VERSION "dbc-export 1 2025.20.8"

NS_ :

BS_:

BU_: APB APP APS DAS EPAS3S ESP GTW IBST PARK RADC RCM RCM2 RCM3 TPMS TRCM USM

BO_ 981 ESP_alertMatrix: 8 ESP
 SG_ ESP_matrixIndex M : 0|4@1+ (1,0) [0|15] "" Vector__XXX
 SG_ ESP_a001_ecuGenericFault m0 : 4|1@1+ (1,0) [0|1] "" Vector__XXX
 SG_ ESP_a002_valvesGenericFault m0 : 5|1@1+ (1,0) [0|1] "" Vector__XXX
 SG_ ESP_a003_outletValvesFault m0 : 6|1@1+ (1,0) [0|1] "" Vector__XXX
 SG_ ESP_a004_inletValvesFault m0 : 7|1@1+ (1,0) [0|1] "" Vector__XXX
 SG_ ESP_a005_HSVValvesFault m0 : 8|1@1+ (1,0) [0|1] "" Vector__XXX
 SG_ ESP_a006_USVValvesFault m0 : 9|1@1+ (1,0) [0|1] "" Vector__XXX
 SG_ ESP_a007_pumpMotorFault m0 : 10|1@1+ (1,0) [0|1] "" Vector__XXX
 SG_ ESP_a008_pumpMotor12VsupplyLow m0 : 11|1@1+ (1,0) [0|1] "" Vector__XXX
 SG_ ESP_a009_12VHardUndervoltage m0 : 12|1@1+ (1,0) [0|1] "" Vector__XXX
 SG_ ESP_a010_12VUndervoltage m0 : 13|1@1+ (1,0) [0|1] "" Vector__XXX
 SG_ ESP_a011_12VSystemUndervoltage m0 : 14|1@1+ (1,0) [0|1] "" Vector__XXX
 SG_ ESP_a012_netUndervoltage m0 : 15|1@1+ (1,0) [0|1] "" Vector__XXX
 SG_ ESP_a013_valveRelayUndervoltage m0 : 16|1@1+ (1,0) [0|1] "" Vector__XXX
 SG_ ESP_a014_WSSSupplyUndervoltage m0 : 17|1@1+ (1,0) [0|1] "" Vector__XXX
 SG_ ESP_a015_12VSupplyOvervoltage m0 : 18|1@1+ (1,0) [0|1] "" Vector__XXX
 SG_ ESP_a016_12VSystemOvervoltage m0 : 19|1@1+ (1,0) [0|1] "" Vector__XXX
 SG_ ESP_a017_netOvervoltage m0 : 20|1@1+ (1,0) [0|1] "" Vector__XXX
 SG_ ESP_a018_WSSSignFrontAxle m0 : 21|1@1+ (1,0) [0|1] "" Vector__XXX
 SG_ ESP_a019_WSSSignRearAxle m0 : 22|1@1+ (1,0) [0|1] "" Vector__XXX
 SG_ ESP_a020_WSSGenericTempFault m0 : 23|1@1+ (1,0) [0|1] "" Vector__XXX
 SG_ ESP_a021_WSSGeneralVDiffFault m0 : 24|1@1+ (1,0) [0|1] "" Vector__XXX
 SG_ ESP_a022_WSSDirectionFault m0 : 25|1@1+ (1,0) [0|1] "" Vector__XXX
 SG_ ESP_a023_WSSSeveralSuspected m0 : 26|1@1+ (1,0) [0|1] "" Vector__XXX
 SG_ ESP_a024_WSSReverseCurrent m0 : 27|1@1+ (1,0) [0|1] "" Vector__XXX
 SG_ ESP_a025_FrLWSSOpenOrShortToGnd m0 : 28|1@1+ (1,0) [0|1] "" Vector__XXX
 SG_ ESP_a026_FrLWSSShortTo12V m0 : 29|1@1+ (1,0) [0|1] "" Vector__XXX
 SG_ ESP_a027_FrLWSSLineInterruption m0 : 30|1@1+ (1,0) [0|1] "" Vector__XXX
 SG_ ESP_a028_FrLWSSMaxSpeedExceeded m0 : 31|1@1+ (1,0) [0|1] "" Vector__XXX
 SG_ ESP_a029_FrLWSSTooManyPulses m0 : 32|1@1+ (1,0) [0|1] "" Vector__XXX
 SG_ ESP_a030_FrLWSSLostSignal m0 : 33|1@1+ (1,0) [0|1] "" Vector__XXX
 SG_ ESP_a031_FrLWSSNoPulsesDetected m0 : 34|1@1+ (1,0) [0|1] "" Vector__XXX
 SG_ ESP_a032_FrLWSSWrongSensorType m0 : 35|1@1+ (1,0) [0|1] "" Vector__XXX
 SG_ ESP_a033_FrLWSSSignalNoise m0 : 36|1@1+ (1,0) [0|1] "" Vector__XXX
 SG_ ESP_a034_FrLWSSVDiffFault m0 : 37|1@1+ (1,0) [0|1] "" Vector__XXX
 SG_ ESP_a035_FrLWSSDirectionFault m0 : 38|1@1+ (1,0) [0|1] "" Vector__XXX
 SG_ ESP_a036_FrLWSSLargeAirGap m0 : 39|1@1+ (1,0) [0|1] "" Vector__XXX
 SG_ ESP_a037_FrLWSSSupplyShortToGnd m0 : 40|1@1+ (1,0) [0|1] "" Vector__XXX
 SG_ ESP_a038_FrLWSSGeneralFault m0 : 41|1@1+ (1,0) [0|1] "" Vector__XXX
 SG_ ESP_a039_FrRWSSOpenOrShortToGnd m0 : 42|1@1+ (1,0) [0|1] "" Vector__XXX
 SG_ ESP_a040_FrRWSSShortTo12V m0 : 43|1@1+ (1,0) [0|1] "" Vector__XXX
 SG_ ESP_a041_FrRWSSLineInterruption m0 : 44|1@1+ (1,0) [0|1] "" Vector__XXX
 SG_ ESP_a042_FrRWSSMaxSpeedExceeded m0 : 45|1@1+ (1,0) [0|1] "" Vector__XXX
 SG_ ESP_a043_FrRWSSTooManyPulses m0 : 46|1@1+ (1,0) [0|1] "" Vector__XXX
 SG_ ESP_a044_FrRWSSLostSignal m0 : 47|1@1+ (1,0) [0|1] "" Vector__XXX
 SG_ ESP_a045_FrRWSSNoPulsesDetected m0 : 48|1@1+ (1,0) [0|1] "" Vector__XXX
 SG_ ESP_a046_FrRWSSWrongSensorType m0 : 49|1@1+ (1,0) [0|1] "" Vector__XXX
 SG_ ESP_a047_FrRWSSSignalNoise m0 : 50|1@1+ (1,0) [0|1] "" Vector__XXX
 SG_ ESP_a048_FrRWSSVDiffFault m0 : 51|1@1+ (1,0) [0|1] "" Vector__XXX
 SG_ ESP_a049_FrRWSSDirectionFault m0 : 52|1@1+ (1,0) [0|1] "" Vector__XXX
 SG_ ESP_a050_FrRWSSLargeAirGap m0 : 53|1@1+ (1,0) [0|1] "" Vector__XXX
 SG_ ESP_a051_FrRWSSSupplyShortToGnd m0 : 54|1@1+ (1,0) [0|1] "" Vector__XXX
 SG_ ESP_a052_FrRWSSGeneralFault m0 : 55|1@1+ (1,0) [0|1] "" Vector__XXX
 SG_ ESP_a053_ReLWSSOpenOrShortToGnd m0 : 56|1@1+ (1,0) [0|1] "" Vector__XXX
 SG_ ESP_a054_ReLWSSShortTo12V m0 : 57|1@1+ (1,0) [0|1] "" Vector__XXX
 SG_ ESP_a055_ReLWSSLineInterruption m0 : 58|1@1+ (1,0) [0|1] "" Vector__XXX
 SG_ ESP_a056_ReLWSSMaxSpeedExceeded m0 : 59|1@1+ (1,0) [0|1] "" Vector__XXX
 SG_ ESP_a057_ReLWSSTooManyPulses m0 : 60|1@1+ (1,0) [0|1] "" Vector__XXX
 SG_ ESP_a058_ReLWSSLostSignal m0 : 61|1@1+ (1,0) [0|1] "" Vector__XXX
 SG_ ESP_a059_ReLWSSNoPulsesDetected m0 : 62|1@1+ (1,0) [0|1] "" Vector__XXX
 SG_ ESP_a060_ReLWSSWrongSensorType m0 : 63|1@1+ (1,0) [0|1] "" Vector__XXX
 SG_ ESP_a061_ReLWSSSignalNoise m1 : 4|1@1+ (1,0) [0|1] "" Vector__XXX
 SG_ ESP_a062_ReLWSSVDiffFault m1 : 5|1@1+ (1,0) [0|1] "" Vector__XXX
 SG_ ESP_a063_ReLWSSDirectionFault m1 : 6|1@1+ (1,0) [0|1] "" Vector__XXX
 SG_ ESP_a064_ReLWSSLargeAirGap m1 : 7|1@1+ (1,0) [0|1] "" Vector__XXX
 SG_ ESP_a065_ReLWSSSupplyShortToGnd m1 : 8|1@1+ (1,0) [0|1] "" Vector__XXX
 SG_ ESP_a066_ReLWSSGeneralFault m1 : 9|1@1+ (1,0) [0|1] "" Vector__XXX
 SG_ ESP_a067_ReRWSSOpenOrShortToGnd m1 : 10|1@1+ (1,0) [0|1] "" Vector__XXX
 SG_ ESP_a068_ReRWSSShortTo12V m1 : 11|1@1+ (1,0) [0|1] "" Vector__XXX
 SG_ ESP_a069_ReRWSSLineInterruption m1 : 12|1@1+ (1,0) [0|1] "" Vector__XXX
 SG_ ESP_a070_ReRWSSMaxSpeedExceeded m1 : 13|1@1+ (1,0) [0|1] "" Vector__XXX
 SG_ ESP_a071_ReRWSSTooManyPulses m1 : 14|1@1+ (1,0) [0|1] "" Vector__XXX
 SG_ ESP_a072_ReRWSSLostSignal m1 : 15|1@1+ (1,0) [0|1] "" Vector__XXX
 SG_ ESP_a073_ReRWSSNoPulsesDetected m1 : 16|1@1+ (1,0) [0|1] "" Vector__XXX
 SG_ ESP_a074_ReRWSSWrongSensorType m1 : 17|1@1+ (1,0) [0|1] "" Vector__XXX
 SG_ ESP_a075_ReRWSSSignalNoise m1 : 18|1@1+ (1,0) [0|1] "" Vector__XXX
 SG_ ESP_a076_ReRWSSVDiffFault m1 : 19|1@1+ (1,0) [0|1] "" Vector__XXX
 SG_ ESP_a077_ReRWSSDirectionFault m1 : 20|1@1+ (1,0) [0|1] "" Vector__XXX
 SG_ ESP_a078_ReRWSSLargeAirGap m1 : 21|1@1+ (1,0) [0|1] "" Vector__XXX
 SG_ ESP_a079_ReRWSSSupplyShortToGnd m1 : 22|1@1+ (1,0) [0|1] "" Vector__XXX
 SG_ ESP_a080_ReRWSSGeneralFault m1 : 23|1@1+ (1,0) [0|1] "" Vector__XXX
 SG_ ESP_a081_PressureSensorShort m1 : 24|1@1+ (1,0) [0|1] "" Vector__XXX
 SG_ ESP_a082_PMCSensorOffsetHigh m1 : 25|1@1+ (1,0) [0|1] "" Vector__XXX
 SG_ ESP_a083_PMCSensorFault m1 : 26|1@1+ (1,0) [0|1] "" Vector__XXX
 SG_ ESP_a084_BrakeFluidReservoirLow m1 : 27|1@1+ (1,0) [0|1] "" Vector__XXX
 SG_ ESP_a085_BrakeSwitchStuckHigh m1 : 28|1@1+ (1,0) [0|1] "" Vector__XXX
 SG_ ESP_a086_BrakeSwitchImplausible1 m1 : 29|1@1+ (1,0) [0|1] "" Vector__XXX
 SG_ ESP_a087_BrakeSwitchImplausible3 m1 : 30|1@1+ (1,0) [0|1] "" Vector__XXX
 SG_ ESP_a088_absContinuousControl m1 : 31|1@1+ (1,0) [0|1] "" Vector__XXX
 SG_ ESP_a089_absNoPressureIncrease m1 : 32|1@1+ (1,0) [0|1] "" Vector__XXX
 SG_ ESP_a090_vdcContinuousControl m1 : 33|1@1+ (1,0) [0|1] "" Vector__XXX
 SG_ ESP_a091_CANUndervoltage m1 : 34|1@1+ (1,0) [0|1] "" Vector__XXX
 SG_ ESP_a092_CANOvervoltage m1 : 35|1@1+ (1,0) [0|1] "" Vector__XXX
 SG_ ESP_a093_partyBusOff m1 : 36|1@1+ (1,0) [0|1] "" Vector__XXX
 SG_ ESP_a094_partyBusPassive m1 : 37|1@1+ (1,0) [0|1] "" Vector__XXX
 SG_ ESP_a095_chassisBusOff m1 : 38|1@1+ (1,0) [0|1] "" Vector__XXX
 SG_ ESP_a096_chassisBusPassive m1 : 39|1@1+ (1,0) [0|1] "" Vector__XXX
 SG_ ESP_a097_tcsRefSpeedNotInit m1 : 40|1@1+ (1,0) [0|1] "" Vector__XXX
 SG_ ESP_a098_vdcRefSpeedNotInit m1 : 41|1@1+ (1,0) [0|1] "" Vector__XXX
 SG_ ESP_a099_brakeTempModelOverheat m1 : 42|1@1+ (1,0) [0|1] "" Vector__XXX
 SG_ ESP_a100_brakeTempModelDisabled m1 : 43|1@1+ (1,0) [0|1] "" Vector__XXX
 SG_ ESP_a101_ebdFault m1 : 44|1@1+ (1,0) [0|1] "" Vector__XXX
 SG_ ESP_a102_absFault m1 : 45|1@1+ (1,0) [0|1] "" Vector__XXX
 SG_ ESP_a103_stabilityControlFault m1 : 46|1@1+ (1,0) [0|1] "" Vector__XXX
 SG_ ESP_a104_hbcEnabled m1 : 47|1@1+ (1,0) [0|1] "" Vector__XXX
 SG_ ESP_a105_ebrFault m1 : 48|1@1+ (1,0) [0|1] "" Vector__XXX
 SG_ ESP_a106_vdcActuatorFault m1 : 49|1@1+ (1,0) [0|1] "" Vector__XXX
 SG_ ESP_a107_reserved107 m1 : 50|1@1+ (1,0) [0|1] "" Vector__XXX
 SG_ ESP_a108_reserved108 m1 : 51|1@1+ (1,0) [0|1] "" Vector__XXX
 SG_ ESP_a109_reserved109 m1 : 52|1@1+ (1,0) [0|1] "" Vector__XXX
 SG_ ESP_a110_rollerBenchActive m1 : 53|1@1+ (1,0) [0|1] "" Vector__XXX
 SG_ ESP_a111_absActive m1 : 54|1@1+ (1,0) [0|1] "" Vector__XXX
 SG_ ESP_a112_espActive m1 : 55|1@1+ (1,0) [0|1] "" Vector__XXX
 SG_ ESP_a113_btcActive m1 : 56|1@1+ (1,0) [0|1] "" Vector__XXX
 SG_ ESP_a114_tvdcActive m1 : 57|1@1+ (1,0) [0|1] "" Vector__XXX
 SG_ ESP_a115_ebdActive m1 : 58|1@1+ (1,0) [0|1] "" Vector__XXX
 SG_ ESP_a116_tsmActive m1 : 59|1@1+ (1,0) [0|1] "" Vector__XXX
 SG_ ESP_a117_hbaActive m1 : 60|1@1+ (1,0) [0|1] "" Vector__XXX
 SG_ ESP_a118_hfcActive m1 : 61|1@1+ (1,0) [0|1] "" Vector__XXX
 SG_ ESP_a119_hbbActive m1 : 62|1@1+ (1,0) [0|1] "" Vector__XXX
 SG_ ESP_a120_rmiActive m1 : 63|1@1+ (1,0) [0|1] "" Vector__XXX
 SG_ ESP_a121_regenTcActive m2 : 4|1@1+ (1,0) [0|1] "" Vector__XXX
 SG_ ESP_a122_bdwActive m2 : 5|1@1+ (1,0) [0|1] "" Vector__XXX
 SG_ ESP_a123_ebrActive m2 : 6|1@1+ (1,0) [0|1] "" Vector__XXX
 SG_ ESP_a124_ebrSkidActive m2 : 7|1@1+ (1,0) [0|1] "" Vector__XXX
 SG_ ESP_a125_reserved125 m2 : 8|1@1+ (1,0) [0|1] "" Vector__XXX
 SG_ ESP_a126_reserved126 m2 : 9|1@1+ (1,0) [0|1] "" Vector__XXX
 SG_ ESP_a127_reserved127 m2 : 10|1@1+ (1,0) [0|1] "" Vector__XXX
 SG_ ESP_a128_reserved128 m2 : 11|1@1+ (1,0) [0|1] "" Vector__XXX
 SG_ ESP_a129_reserved129 m2 : 12|1@1+ (1,0) [0|1] "" Vector__XXX
 SG_ ESP_a130_EPAS3PsysStatusTimeout m2 : 13|1@1+ (1,0) [0|1] "" Vector__XXX
 SG_ ESP_a131_EPAS3PsysStatusDLC m2 : 14|1@1+ (1,0) [0|1] "" Vector__XXX
 SG_ ESP_a132_EPAS3PsysStatusChecksum m2 : 15|1@1+ (1,0) [0|1] "" Vector__XXX
 SG_ ESP_a133_EPAS3PsysStatusCounter m2 : 16|1@1+ (1,0) [0|1] "" Vector__XXX
 SG_ ESP_a134_steeringAngleInvalid m2 : 17|1@1+ (1,0) [0|1] "" Vector__XXX
 SG_ ESP_a135_steeringAngleNoCenter m2 : 18|1@1+ (1,0) [0|1] "" Vector__XXX
 SG_ ESP_a136_steeringAngleFrozen m2 : 19|1@1+ (1,0) [0|1] "" Vector__XXX
 SG_ ESP_a137_steeringOffsetTooLarge m2 : 20|1@1+ (1,0) [0|1] "" Vector__XXX
 SG_ ESP_a138_steeringAngleImplaus m2 : 21|1@1+ (1,0) [0|1] "" Vector__XXX
 SG_ ESP_a139_steeringAngleWrongSign m2 : 22|1@1+ (1,0) [0|1] "" Vector__XXX
 SG_ ESP_a140_RCMInertial1Timeout m2 : 23|1@1+ (1,0) [0|1] "" Vector__XXX
 SG_ ESP_a141_RCMInertial1DLC m2 : 24|1@1+ (1,0) [0|1] "" Vector__XXX
 SG_ ESP_a142_RCMInertial1Checksum m2 : 25|1@1+ (1,0) [0|1] "" Vector__XXX
 SG_ ESP_a143_RCMInertial1Counter m2 : 26|1@1+ (1,0) [0|1] "" Vector__XXX
 SG_ ESP_a144_yawMaxLatency m2 : 27|1@1+ (1,0) [0|1] "" Vector__XXX
 SG_ ESP_a145_yawInitFault m2 : 28|1@1+ (1,0) [0|1] "" Vector__XXX
 SG_ ESP_a146_yawInvalidValue m2 : 29|1@1+ (1,0) [0|1] "" Vector__XXX
 SG_ ESP_a147_yawSensorNotAvailable m2 : 30|1@1+ (1,0) [0|1] "" Vector__XXX
 SG_ ESP_a148_yawSignalFault m2 : 31|1@1+ (1,0) [0|1] "" Vector__XXX
 SG_ ESP_a149_yawInvalidSign m2 : 32|1@1+ (1,0) [0|1] "" Vector__XXX
 SG_ ESP_a150_yawImplausible m2 : 33|1@1+ (1,0) [0|1] "" Vector__XXX
 SG_ ESP_a151_RCMInertial2Timeout m2 : 34|1@1+ (1,0) [0|1] "" Vector__XXX
 SG_ ESP_a152_RCMInertial2DLC m2 : 35|1@1+ (1,0) [0|1] "" Vector__XXX
 SG_ ESP_a153_RCMInertial2Checksum m2 : 36|1@1+ (1,0) [0|1] "" Vector__XXX
 SG_ ESP_a154_RCMInertial2Counter m2 : 37|1@1+ (1,0) [0|1] "" Vector__XXX
 SG_ ESP_a155_ayMaxLatency m2 : 38|1@1+ (1,0) [0|1] "" Vector__XXX
 SG_ ESP_a156_ayInitFault m2 : 39|1@1+ (1,0) [0|1] "" Vector__XXX
 SG_ ESP_a157_ayInvalidValue m2 : 40|1@1+ (1,0) [0|1] "" Vector__XXX
 SG_ ESP_a158_aySensorNotAvailable m2 : 41|1@1+ (1,0) [0|1] "" Vector__XXX
 SG_ ESP_a159_aySignalFault m2 : 42|1@1+ (1,0) [0|1] "" Vector__XXX
 SG_ ESP_a160_ayRangeExceeded m2 : 43|1@1+ (1,0) [0|1] "" Vector__XXX
 SG_ ESP_a161_ayOffsetExceeded m2 : 44|1@1+ (1,0) [0|1] "" Vector__XXX
 SG_ ESP_a162_ayImplausible m2 : 45|1@1+ (1,0) [0|1] "" Vector__XXX
 SG_ ESP_a163_axMaxLatency m2 : 46|1@1+ (1,0) [0|1] "" Vector__XXX
 SG_ ESP_a164_axInitFault m2 : 47|1@1+ (1,0) [0|1] "" Vector__XXX
 SG_ ESP_a165_axInvalidValue m2 : 48|1@1+ (1,0) [0|1] "" Vector__XXX
 SG_ ESP_a166_axSensorNotAvailable m2 : 49|1@1+ (1,0) [0|1] "" Vector__XXX
 SG_ ESP_a167_axSignalFault m2 : 50|1@1+ (1,0) [0|1] "" Vector__XXX
 SG_ ESP_a168_axRangeExceeded m2 : 51|1@1+ (1,0) [0|1] "" Vector__XXX
 SG_ ESP_a169_axOffsetExceeded m2 : 52|1@1+ (1,0) [0|1] "" Vector__XXX
 SG_ ESP_a170_axSignalFrozen m2 : 53|1@1+ (1,0) [0|1] "" Vector__XXX
 SG_ ESP_a171_axImplausible m2 : 54|1@1+ (1,0) [0|1] "" Vector__XXX
 SG_ ESP_a172_IBSTparty1Timeout m2 : 55|1@1+ (1,0) [0|1] "" Vector__XXX
 SG_ ESP_a173_IBSTparty1DLC m2 : 56|1@1+ (1,0) [0|1] "" Vector__XXX
 SG_ ESP_a174_IBSTparty1Checksum m2 : 57|1@1+ (1,0) [0|1] "" Vector__XXX
 SG_ ESP_a175_IBSTparty1Counter m2 : 58|1@1+ (1,0) [0|1] "" Vector__XXX
 SG_ ESP_a176_IBSTEBRNotAvailable m2 : 59|1@1+ (1,0) [0|1] "" Vector__XXX
 SG_ ESP_a177_IBSTOutputRodDrvInvalid m2 : 60|1@1+ (1,0) [0|1] "" Vector__XXX
 SG_ ESP_a178_IBSTOutputRodActInvalid m2 : 61|1@1+ (1,0) [0|1] "" Vector__XXX
 SG_ ESP_a179_IBSTparty2Timeout m2 : 62|1@1+ (1,0) [0|1] "" Vector__XXX
 SG_ ESP_a180_IBSTparty2Checksum m2 : 63|1@1+ (1,0) [0|1] "" Vector__XXX
 SG_ ESP_a181_IBSTparty2DLC m3 : 4|1@1+ (1,0) [0|1] "" Vector__XXX
 SG_ ESP_a182_IBSTparty2Counter m3 : 5|1@1+ (1,0) [0|1] "" Vector__XXX
 SG_ ESP_a183_IBSTStatusOff m3 : 6|1@1+ (1,0) [0|1] "" Vector__XXX
 SG_ ESP_a184_IBSTpRunoutInvalid m3 : 7|1@1+ (1,0) [0|1] "" Vector__XXX
 SG_ ESP_a185_IBSTFeedforwardBackup m3 : 8|1@1+ (1,0) [0|1] "" Vector__XXX
 SG_ ESP_a186_IBSTBrakeAppliedInvalid m3 : 9|1@1+ (1,0) [0|1] "" Vector__XXX
 SG_ ESP_a187_DIbtcRequestTimeout m3 : 10|1@1+ (1,0) [0|1] "" Vector__XXX
 SG_ ESP_a188_DIbtcRequestDLC m3 : 11|1@1+ (1,0) [0|1] "" Vector__XXX
 SG_ ESP_a189_DIbtcRequestChecksum m3 : 12|1@1+ (1,0) [0|1] "" Vector__XXX
 SG_ ESP_a190_DIbtcRequestCounter m3 : 13|1@1+ (1,0) [0|1] "" Vector__XXX
 SG_ ESP_a191_DIchassisControlTimeout m3 : 14|1@1+ (1,0) [0|1] "" Vector__XXX
 SG_ ESP_a192_DIchassisControlDLC m3 : 15|1@1+ (1,0) [0|1] "" Vector__XXX
 SG_ ESP_a193_DIchassisControlChecksu m3 : 16|1@1+ (1,0) [0|1] "" Vector__XXX
 SG_ ESP_a194_DIchassisControlCounter m3 : 17|1@1+ (1,0) [0|1] "" Vector__XXX
 SG_ ESP_a195_ptcStateInvalid m3 : 18|1@1+ (1,0) [0|1] "" Vector__XXX
 SG_ ESP_a196_DIsystemStatusTimeout m3 : 19|1@1+ (1,0) [0|1] "" Vector__XXX
 SG_ ESP_a197_DIsystemStatusDLC m3 : 20|1@1+ (1,0) [0|1] "" Vector__XXX
 SG_ ESP_a198_DIsystemStatusChecksum m3 : 21|1@1+ (1,0) [0|1] "" Vector__XXX
 SG_ ESP_a199_DIsystemStatusCounter m3 : 22|1@1+ (1,0) [0|1] "" Vector__XXX
 SG_ ESP_a200_reverseGearStuckHigh m3 : 23|1@1+ (1,0) [0|1] "" Vector__XXX
 SG_ ESP_a201_reverseGearStuckLow m3 : 24|1@1+ (1,0) [0|1] "" Vector__XXX
 SG_ ESP_a202_accelPedalInvalid m3 : 25|1@1+ (1,0) [0|1] "" Vector__XXX
 SG_ ESP_a203_DItorqueTimeout m3 : 26|1@1+ (1,0) [0|1] "" Vector__XXX
 SG_ ESP_a204_DItorqueDLC m3 : 27|1@1+ (1,0) [0|1] "" Vector__XXX
 SG_ ESP_a205_DItorqueChecksum m3 : 28|1@1+ (1,0) [0|1] "" Vector__XXX
 SG_ ESP_a206_DItorqueCounter m3 : 29|1@1+ (1,0) [0|1] "" Vector__XXX
 SG_ ESP_a207_DITorqueCommandInvalid m3 : 30|1@1+ (1,0) [0|1] "" Vector__XXX
 SG_ ESP_a208_DIRPMInvalid m3 : 31|1@1+ (1,0) [0|1] "" Vector__XXX
 SG_ ESP_a209_DITorqueActualInvalid m3 : 32|1@1+ (1,0) [0|1] "" Vector__XXX
 SG_ ESP_a210_DIStorqueTimeout m3 : 33|1@1+ (1,0) [0|1] "" Vector__XXX
 SG_ ESP_a211_DIStorqueDLC m3 : 34|1@1+ (1,0) [0|1] "" Vector__XXX
 SG_ ESP_a212_DIStorqueChecksum m3 : 35|1@1+ (1,0) [0|1] "" Vector__XXX
 SG_ ESP_a213_DIStorqueCounter m3 : 36|1@1+ (1,0) [0|1] "" Vector__XXX
 SG_ ESP_a214_DISTorqueCommandInvalid m3 : 37|1@1+ (1,0) [0|1] "" Vector__XXX
 SG_ ESP_a215_DISRPMInvalid m3 : 38|1@1+ (1,0) [0|1] "" Vector__XXX
 SG_ ESP_a216_DISTorqueActualInvalid m3 : 39|1@1+ (1,0) [0|1] "" Vector__XXX
 SG_ ESP_a217_DIvdcLeftTimeout m3 : 40|1@1+ (1,0) [0|1] "" Vector__XXX
 SG_ ESP_a218_DIvdcLeftDLC m3 : 41|1@1+ (1,0) [0|1] "" Vector__XXX
 SG_ ESP_a219_DIvdcLeftChecksum m3 : 42|1@1+ (1,0) [0|1] "" Vector__XXX
 SG_ ESP_a220_DIvdcLeftCounter m3 : 43|1@1+ (1,0) [0|1] "" Vector__XXX
 SG_ ESP_a221_DIvdcRightTimeout m3 : 44|1@1+ (1,0) [0|1] "" Vector__XXX
 SG_ ESP_a222_DIvdcRightDLC m3 : 45|1@1+ (1,0) [0|1] "" Vector__XXX
 SG_ ESP_a223_DIvdcRightChecksum m3 : 46|1@1+ (1,0) [0|1] "" Vector__XXX
 SG_ ESP_a224_DIvdcRightCounter m3 : 47|1@1+ (1,0) [0|1] "" Vector__XXX
 SG_ ESP_a225_configMismatch m3 : 48|1@1+ (1,0) [0|1] "" Vector__XXX
 SG_ ESP_a226_bdwRequestInvalid m3 : 49|1@1+ (1,0) [0|1] "" Vector__XXX
 SG_ ESP_a227_bdwRequestActiveInvalid m3 : 50|1@1+ (1,0) [0|1] "" Vector__XXX
 SG_ ESP_a228_GTWvinTimeout m3 : 51|1@1+ (1,0) [0|1] "" Vector__XXX
 SG_ ESP_a229_GTWvinDLC m3 : 52|1@1+ (1,0) [0|1] "" Vector__XXX
 SG_ ESP_a230_vinNotLearned m3 : 53|1@1+ (1,0) [0|1] "" Vector__XXX
 SG_ ESP_a231_storedVINMismatch m3 : 54|1@1+ (1,0) [0|1] "" Vector__XXX
 SG_ ESP_a232_PMstate2Timeout m3 : 55|1@1+ (1,0) [0|1] "" Vector__XXX
 SG_ ESP_a233_PMstate2Checksum m3 : 56|1@1+ (1,0) [0|1] "" Vector__XXX
 SG_ ESP_a234_PMstate2DLC m3 : 57|1@1+ (1,0) [0|1] "" Vector__XXX
 SG_ ESP_a235_PMstate2Counter m3 : 58|1@1+ (1,0) [0|1] "" Vector__XXX
 SG_ ESP_a236_ebrCommandStateInvalid m3 : 59|1@1+ (1,0) [0|1] "" Vector__XXX
 SG_ ESP_a237_vdcCommandStateInvalid m3 : 60|1@1+ (1,0) [0|1] "" Vector__XXX
 SG_ ESP_a238_UIodoTimeout m3 : 61|1@1+ (1,0) [0|1] "" Vector__XXX
 SG_ ESP_a239_UIodoDLC m3 : 62|1@1+ (1,0) [0|1] "" Vector__XXX
 SG_ ESP_a240_LVPowerStateTimeout m3 : 63|1@1+ (1,0) [0|1] "" Vector__XXX
 SG_ ESP_a241_LVPowerStateChecksum m4 : 4|1@1+ (1,0) [0|1] "" Vector__XXX
 SG_ ESP_a242_LVPowerStateDLC m4 : 5|1@1+ (1,0) [0|1] "" Vector__XXX
 SG_ ESP_a243_LVPowerStateCounter m4 : 6|1@1+ (1,0) [0|1] "" Vector__XXX
 SG_ ESP_a244_LVOffStateInvalid m4 : 7|1@1+ (1,0) [0|1] "" Vector__XXX
 SG_ ESP_a245_LVGoingDownStateInvalid m4 : 8|1@1+ (1,0) [0|1] "" Vector__XXX
 SG_ ESP_a246_VCFRONTsensorTimeout m4 : 9|1@1+ (1,0) [0|1] "" Vector__XXX
 SG_ ESP_a247_VCFRONTsensorDLC m4 : 10|1@1+ (1,0) [0|1] "" Vector__XXX
 SG_ ESP_a248_vdcBrkeTrqTarFrLInvalid m4 : 11|1@1+ (1,0) [0|1] "" Vector__XXX
 SG_ ESP_a249_vdcBrkeTrqTarFrRInvalid m4 : 12|1@1+ (1,0) [0|1] "" Vector__XXX
 SG_ ESP_a250_vdcBrkeTrqTarReLInvalid m4 : 13|1@1+ (1,0) [0|1] "" Vector__XXX
 SG_ ESP_a251_vdcBrkeTrqTarReRInvalid m4 : 14|1@1+ (1,0) [0|1] "" Vector__XXX
 SG_ ESP_a252_vdcWhlSlipLimFrLInvalid m4 : 15|1@1+ (1,0) [0|1] "" Vector__XXX
 SG_ ESP_a253_vdcWhlSlipLimFrRInvalid m4 : 16|1@1+ (1,0) [0|1] "" Vector__XXX
 SG_ ESP_a254_vdcWhlSlipLimReLInvalid m4 : 17|1@1+ (1,0) [0|1] "" Vector__XXX
 SG_ ESP_a255_vdcWhlSlipLimReRInvalid m4 : 18|1@1+ (1,0) [0|1] "" Vector__XXX
 SG_ ESP_a256_epbmStatusTimeout m4 : 19|1@1+ (1,0) [0|1] "" Vector__XXX
 SG_ ESP_a257_epbmStatusChecksum m4 : 20|1@1+ (1,0) [0|1] "" Vector__XXX
 SG_ ESP_a258_epbmStatusDLC m4 : 21|1@1+ (1,0) [0|1] "" Vector__XXX
 SG_ ESP_a259_epbmStatusCounter m4 : 22|1@1+ (1,0) [0|1] "" Vector__XXX
 SG_ ESP_a260_epblStatusTimeout m4 : 23|1@1+ (1,0) [0|1] "" Vector__XXX
 SG_ ESP_a261_epblStatusChecksum m4 : 24|1@1+ (1,0) [0|1] "" Vector__XXX
 SG_ ESP_a262_epblStatusDLC m4 : 25|1@1+ (1,0) [0|1] "" Vector__XXX
 SG_ ESP_a263_epblStatusCounter m4 : 26|1@1+ (1,0) [0|1] "" Vector__XXX
 SG_ ESP_a264_pumpSpeedLimitInvalid m4 : 27|1@1+ (1,0) [0|1] "" Vector__XXX
 SG_ ESP_a265_DIRELtorqueTimeout m4 : 28|1@1+ (1,0) [0|1] "" Vector__XXX
 SG_ ESP_a266_DIRELtorqueDLC m4 : 29|1@1+ (1,0) [0|1] "" Vector__XXX
 SG_ ESP_a267_DIRELtorqueChecksum m4 : 30|1@1+ (1,0) [0|1] "" Vector__XXX
 SG_ ESP_a268_DIRELtorqueCounter m4 : 31|1@1+ (1,0) [0|1] "" Vector__XXX
 SG_ ESP_a269_DIRELTorqueCommandInval m4 : 32|1@1+ (1,0) [0|1] "" Vector__XXX
 SG_ ESP_a270_DIRELRPMInvalid m4 : 33|1@1+ (1,0) [0|1] "" Vector__XXX
 SG_ ESP_a271_DIRELTorqueActualInvali m4 : 34|1@1+ (1,0) [0|1] "" Vector__XXX
 SG_ ESP_a272_DIRERtorqueTimeout m4 : 35|1@1+ (1,0) [0|1] "" Vector__XXX
 SG_ ESP_a273_DIRERtorqueDLC m4 : 36|1@1+ (1,0) [0|1] "" Vector__XXX
 SG_ ESP_a274_DIRERtorqueChecksum m4 : 37|1@1+ (1,0) [0|1] "" Vector__XXX
 SG_ ESP_a275_DIRERtorqueCounter m4 : 38|1@1+ (1,0) [0|1] "" Vector__XXX
 SG_ ESP_a276_DIRERTorqueCommandInval m4 : 39|1@1+ (1,0) [0|1] "" Vector__XXX
 SG_ ESP_a277_DIRERRPMInvalid m4 : 40|1@1+ (1,0) [0|1] "" Vector__XXX
 SG_ ESP_a278_DIRERTorqueActualInvali m4 : 41|1@1+ (1,0) [0|1] "" Vector__XXX
 SG_ ESP_a279_lifetimeManagementOverr m4 : 42|1@1+ (1,0) [0|1] "" Vector__XXX
 SG_ ESP_a280_trackModeABSEnabled m4 : 43|1@1+ (1,0) [0|1] "" Vector__XXX
 SG_ ESP_a281_trackModeABSdisabled m4 : 44|1@1+ (1,0) [0|1] "" Vector__XXX
 SG_ ESP_a282_trackModeABSRequestInva m4 : 45|1@1+ (1,0) [0|1] "" Vector__XXX
 SG_ ESP_a283_secondaryCollisionMitig m4 : 46|1@1+ (1,0) [0|1] "" Vector__XXX
 SG_ ESP_a284_scmRequestInvalidChecks m4 : 47|1@1+ (1,0) [0|1] "" Vector__XXX
 SG_ ESP_a285_scmRequestDLC m4 : 48|1@1+ (1,0) [0|1] "" Vector__XXX
 SG_ ESP_a286_hydroplaneDetected m4 : 49|1@1+ (1,0) [0|1] "" Vector__XXX
 SG_ ESP_a287_failedBrakeCircuitDetec m4 : 50|1@1+ (1,0) [0|1] "" Vector__XXX
 SG_ ESP_a288_leftBusOff m4 : 51|1@1+ (1,0) [0|1] "" Vector__XXX
 SG_ ESP_a289_leftBusPassive m4 : 52|1@1+ (1,0) [0|1] "" Vector__XXX
 SG_ ESP_a290_brakeBusOff m4 : 53|1@1+ (1,0) [0|1] "" Vector__XXX
 SG_ ESP_a291_brakeBusPassive m4 : 54|1@1+ (1,0) [0|1] "" Vector__XXX
 SG_ ESP_a292_PEPSstatusTimeout m4 : 55|1@1+ (1,0) [0|1] "" Vector__XXX
 SG_ ESP_a293_PEPSstatusDLC m4 : 56|1@1+ (1,0) [0|1] "" Vector__XXX
 SG_ ESP_a294_PEPSstatusChecksum m4 : 57|1@1+ (1,0) [0|1] "" Vector__XXX
 SG_ ESP_a295_PEPSstatusCounter m4 : 58|1@1+ (1,0) [0|1] "" Vector__XXX
 SG_ ESP_a296_roadWheelAngleHealthDeg m4 : 59|1@1+ (1,0) [0|1] "" Vector__XXX
 SG_ ESP_a297_roadWheelAngleHealthFau m4 : 60|1@1+ (1,0) [0|1] "" Vector__XXX
 SG_ ESP_a298_RSArearSteerStatusTimeo m4 : 61|1@1+ (1,0) [0|1] "" Vector__XXX
 SG_ ESP_a299_RSArearSteerStatusDLC m4 : 62|1@1+ (1,0) [0|1] "" Vector__XXX
 SG_ ESP_a300_RSArearSteerStatusCheck m4 : 63|1@1+ (1,0) [0|1] "" Vector__XXX
 SG_ ESP_a301_PEPSstatusCounter m5 : 4|1@1+ (1,0) [0|1] "" Vector__XXX
 SG_ ESP_a302_rearRoadWheelAngleHealt m5 : 5|1@1+ (1,0) [0|1] "" Vector__XXX
 SG_ ESP_a303_rearRoadWheelAngleHealt m5 : 6|1@1+ (1,0) [0|1] "" Vector__XXX
 SG_ ESP_a304_rearVCLVPowerStateTimeo m5 : 7|1@1+ (1,0) [0|1] "" Vector__XXX
 SG_ ESP_a305_rearVCLVPowerStateDLC m5 : 8|1@1+ (1,0) [0|1] "" Vector__XXX
 SG_ ESP_a306_rearVCLVPowerStateCheck m5 : 9|1@1+ (1,0) [0|1] "" Vector__XXX
 SG_ ESP_a307_rearVCLVPowerStateCount m5 : 10|1@1+ (1,0) [0|1] "" Vector__XXX
 SG_ ESP_a308_evacFillNotComplete m5 : 11|1@1+ (1,0) [0|1] "" Vector__XXX
 SG_ ESP_a309_factoryModeActive m5 : 12|1@1+ (1,0) [0|1] "" Vector__XXX
 SG_ ESP_a310_brakeLatencyReductionAc m5 : 13|1@1+ (1,0) [0|1] "" Vector__XXX
 SG_ ESP_a311_aesActive m5 : 14|1@1+ (1,0) [0|1] "" Vector__XXX
 SG_ ESP_a312_undefinedAlertDetected m5 : 15|1@1+ (1,0) [0|1] "" Vector__XXX
 SG_ ESP_a313_cdpRequestStateInvalid m5 : 16|1@1+ (1,0) [0|1] "" Vector__XXX
 SG_ ESP_a314_aesFault m5 : 17|1@1+ (1,0) [0|1] "" Vector__XXX
 SG_ ESP_a315_EMCBackup11Timeout m5 : 18|1@1+ (1,0) [0|1] "" Vector__XXX
 SG_ ESP_a316_EMCBackup11DLC m5 : 19|1@1+ (1,0) [0|1] "" Vector__XXX
 SG_ ESP_a317_EMCBackup11Checksum m5 : 20|1@1+ (1,0) [0|1] "" Vector__XXX
 SG_ ESP_a318_EMCBackup11Counter m5 : 21|1@1+ (1,0) [0|1] "" Vector__XXX
 SG_ ESP_a319_AES_BackupActuatorActiv m5 : 22|1@1+ (1,0) [0|1] "" Vector__XXX
 SG_ ESP_a320_DPB_actuator1Counter m5 : 23|1@1+ (1,0) [0|1] "" Vector__XXX
 SG_ ESP_a321_DPB_actuator1Checksum m5 : 24|1@1+ (1,0) [0|1] "" Vector__XXX
 SG_ ESP_a322_DPB_actuator1DLC m5 : 25|1@1+ (1,0) [0|1] "" Vector__XXX
 SG_ ESP_a323_DPB_actuator1Timeout m5 : 26|1@1+ (1,0) [0|1] "" Vector__XXX
 SG_ ESP_a324_DPB_actuator2Counter m5 : 27|1@1+ (1,0) [0|1] "" Vector__XXX
 SG_ ESP_a325_DPB_actuator2Checksum m5 : 28|1@1+ (1,0) [0|1] "" Vector__XXX
 SG_ ESP_a326_DPB_actuator2DLC m5 : 29|1@1+ (1,0) [0|1] "" Vector__XXX
 SG_ ESP_a327_DPB_actuator2Timeout m5 : 30|1@1+ (1,0) [0|1] "" Vector__XXX
 SG_ ESP_a328_DPB_actuator3Counter m5 : 31|1@1+ (1,0) [0|1] "" Vector__XXX
 SG_ ESP_a329_DPB_actuator3Checksum m5 : 32|1@1+ (1,0) [0|1] "" Vector__XXX
 SG_ ESP_a330_DPB_actuator3DLC m5 : 33|1@1+ (1,0) [0|1] "" Vector__XXX
 SG_ ESP_a331_DPB_actuator3Timeout m5 : 34|1@1+ (1,0) [0|1] "" Vector__XXX
 SG_ ESP_a332_PressureSensorValHigh m5 : 35|1@1+ (1,0) [0|1] "" Vector__XXX
 SG_ ESP_a333_ActCircuitNoPressure m5 : 36|1@1+ (1,0) [0|1] "" Vector__XXX
 SG_ ESP_a334_BrakePedalAppliedInvali m5 : 37|1@1+ (1,0) [0|1] "" Vector__XXX
 SG_ ESP_a335_LdmFxTarBrakeActInvalid m5 : 38|1@1+ (1,0) [0|1] "" Vector__XXX
 SG_ ESP_a336_FxTargetDriverInvalid m5 : 39|1@1+ (1,0) [0|1] "" Vector__XXX
 SG_ ESP_a337_pReductionPotentialInva m5 : 40|1@1+ (1,0) [0|1] "" Vector__XXX
 SG_ ESP_a338_pRunoutInvalid m5 : 41|1@1+ (1,0) [0|1] "" Vector__XXX
 SG_ ESP_a339_sInputRodInvalid m5 : 42|1@1+ (1,0) [0|1] "" Vector__XXX
 SG_ ESP_a340_RollerBenchMisuse m5 : 43|1@1+ (1,0) [0|1] "" Vector__XXX
 SG_ ESP_a341_EnhancedPressureBuildAc m5 : 44|1@1+ (1,0) [0|1] "" Vector__XXX
 SG_ ESP_a342_EnhancedPressureBuildNo m5 : 45|1@1+ (1,0) [0|1] "" Vector__XXX
 SG_ ESP_a343_EnhancedPressureBuildLt m5 : 46|1@1+ (1,0) [0|1] "" Vector__XXX
 SG_ ESP_a344_DIbrakeCommandCounter m5 : 47|1@1+ (1,0) [0|1] "" Vector__XXX
 SG_ ESP_a345_DIbrakeCommandChecksum m5 : 48|1@1+ (1,0) [0|1] "" Vector__XXX
 SG_ ESP_a346_DIbrakeCommandDLC m5 : 49|1@1+ (1,0) [0|1] "" Vector__XXX
 SG_ ESP_a347_DIbrakeCommandTimeout m5 : 50|1@1+ (1,0) [0|1] "" Vector__XXX
 SG_ ESP_a348_brakeCmdStateInvalid m5 : 51|1@1+ (1,0) [0|1] "" Vector__XXX
 SG_ ESP_a349_ForceLampToRed m5 : 52|1@1+ (1,0) [0|1] "" Vector__XXX
 SG_ ESP_a350_ActuatorOff m5 : 53|1@1+ (1,0) [0|1] "" Vector__XXX
 SG_ ESP_a351_ActuatorYellowLampReque m5 : 54|1@1+ (1,0) [0|1] "" Vector__XXX
 SG_ ESP_a352_ActuatorLDMFailure m5 : 55|1@1+ (1,0) [0|1] "" Vector__XXX
 SG_ ESP_a353_PressureSensorImplausHi m5 : 56|1@1+ (1,0) [0|1] "" Vector__XXX
 SG_ ESP_a354_HBCRequestInvalid m5 : 57|1@1+ (1,0) [0|1] "" Vector__XXX
 SG_ ESP_a355_RecuStatusActInvalid m5 : 58|1@1+ (1,0) [0|1] "" Vector__XXX
 SG_ ESP_a356_DIFAxleTorqueInvalid m5 : 59|1@1+ (1,0) [0|1] "" Vector__XXX
 SG_ ESP_a357_DIRAxleTorqueInvalid m5 : 60|1@1+ (1,0) [0|1] "" Vector__XXX
 SG_ ESP_a358_externalActuatorFallbac m5 : 61|1@1+ (1,0) [0|1] "" Vector__XXX
 SG_ ESP_a359_externalActuatorNoExtRe m5 : 62|1@1+ (1,0) [0|1] "" Vector__XXX
 SG_ ESP_a360_BBbrakeActuationTimeout m5 : 63|1@1+ (1,0) [0|1] "" Vector__XXX
 SG_ ESP_a361_BBbrakeActuationDLC m6 : 4|1@1+ (1,0) [0|1] "" Vector__XXX
 SG_ ESP_a362_BBbrakeActuationChecksu m6 : 5|1@1+ (1,0) [0|1] "" Vector__XXX
 SG_ ESP_a363_BBbrakeActuationCounter m6 : 6|1@1+ (1,0) [0|1] "" Vector__XXX
 SG_ ESP_a364_DIgearInvalid m6 : 7|1@1+ (1,0) [0|1] "" Vector__XXX
 SG_ ESP_a365_TCSInputQualityTooLow m6 : 8|1@1+ (1,0) [0|1] "" Vector__XXX
 SG_ ESP_a366_ActuatorBlendingModeReq m6 : 9|1@1+ (1,0) [0|1] "" Vector__XXX
 SG_ ESP_a367_CBDS_fillBufferThreshol m6 : 10|1@1+ (1,0) [0|1] "" Vector__XXX
 SG_ ESP_a368_CBDS_fmeInternalEvent m6 : 11|1@1+ (1,0) [0|1] "" Vector__XXX
 SG_ ESP_a369_LargeLeakageDetectedByD m6 : 12|1@1+ (1,0) [0|1] "" Vector__XXX
 SG_ ESP_a370_DPB_actuator4Timeout m6 : 13|1@1+ (1,0) [0|1] "" Vector__XXX
 SG_ ESP_a371_DPB_actuator4DLC m6 : 14|1@1+ (1,0) [0|1] "" Vector__XXX
 SG_ ESP_a372_DPB_actuator4Checksum m6 : 15|1@1+ (1,0) [0|1] "" Vector__XXX
 SG_ ESP_a373_DPB_actuator4Counter m6 : 16|1@1+ (1,0) [0|1] "" Vector__XXX
 SG_ ESP_a374_StatInvalid_DI_FullSNA m6 : 17|1@1+ (1,0) [0|1] "" Vector__XXX
 SG_ ESP_a375_PM_locStateCounter m6 : 18|1@1+ (1,0) [0|1] "" Vector__XXX
 SG_ ESP_a376_PM_locStateChecksum m6 : 19|1@1+ (1,0) [0|1] "" Vector__XXX
 SG_ ESP_a377_PM_locStateDLC m6 : 20|1@1+ (1,0) [0|1] "" Vector__XXX
 SG_ ESP_a378_PM_locStateTimeout m6 : 21|1@1+ (1,0) [0|1] "" Vector__XXX

BO_ 805 ESP_info: 8 ESP
 SG_ ESP_infoIndex M : 0|8@1+ (1,0) [0|255] "" Vector__XXX
 SG_ ESP_infoBuildType m10 : 8|8@1+ (1,0) [0|255] "" Vector__XXX
 SG_ ESP_vehFlashMode m10 : 24|1@1+ (1,0) [0|1] "" Vector__XXX
 SG_ ESP_infoComponentID m10 : 48|16@1+ (1,0) [0|65535] "" Vector__XXX
 SG_ ESP_infoPcbaID m11 : 16|8@1+ (1,0) [0|255] "" Vector__XXX
 SG_ ESP_infoAssemblyID m11 : 24|8@1+ (1,0) [0|255] "" Vector__XXX
 SG_ ESP_infoUsageID m11 : 32|16@1+ (1,0) [0|65535] "" Vector__XXX
 SG_ ESP_infoSubUsageID m11 : 48|16@1+ (1,0) [0|65535] "" Vector__XXX
 SG_ ESP_infoApplicationCRC m13 : 39|32@0+ (1,0) [0|4294967295] "" Vector__XXX
 SG_ ESP_infoVehicleVariant m16 : 16|8@1+ (1,0) [0|255] "" Vector__XXX
 SG_ ESP_infoSubcomponent1 m16 : 32|32@1+ (1,0) [0|4294967295] "" Vector__XXX
 SG_ ESP_infoBootUdsProtoVersion m20 : 8|8@1+ (1,0) [0|255] "" Vector__XXX
 SG_ ESP_infoBootloaderCRC m20 : 32|32@1+ (1,0) [0|4294967295] "" Vector__XXX
 SG_ ESP_infoVariantCRC m22 : 39|32@0+ (1,0) [0|4294967295] "" Vector__XXX

BO_ 861 IBST_alertMatrix: 8 IBST
 SG_ IBST_matrixIndex M : 0|4@1+ (1,0) [0|15] "" Vector__XXX
 SG_ IBST_a001_microSupplyError m0 : 4|1@1+ (1,0) [0|1] "" Vector__XXX
 SG_ IBST_a002_HWBISTError m0 : 5|1@1+ (1,0) [0|1] "" Vector__XXX
 SG_ IBST_a003_RAMFault m0 : 6|1@1+ (1,0) [0|1] "" Vector__XXX
 SG_ IBST_a004_flashFault m0 : 7|1@1+ (1,0) [0|1] "" Vector__XXX
 SG_ IBST_a005_microSafetyFault m0 : 8|1@1+ (1,0) [0|1] "" Vector__XXX
 SG_ IBST_a006_microSafetyLogicFault m0 : 9|1@1+ (1,0) [0|1] "" Vector__XXX
 SG_ IBST_a007_RBCPUException m0 : 10|1@1+ (1,0) [0|1] "" Vector__XXX
 SG_ IBST_a008_stackOverUnderFlow m0 : 11|1@1+ (1,0) [0|1] "" Vector__XXX
 SG_ IBST_a009_systemErrorHook m0 : 12|1@1+ (1,0) [0|1] "" Vector__XXX
 SG_ IBST_a010_OSErrorHook m0 : 13|1@1+ (1,0) [0|1] "" Vector__XXX
 SG_ IBST_a011_systemTaskOverRun m0 : 14|1@1+ (1,0) [0|1] "" Vector__XXX
 SG_ IBST_a012_OSTaskSchemeError m0 : 15|1@1+ (1,0) [0|1] "" Vector__XXX
 SG_ IBST_a013_systemTaskJitter m0 : 16|1@1+ (1,0) [0|1] "" Vector__XXX
 SG_ IBST_a014_DMATransferError m0 : 17|1@1+ (1,0) [0|1] "" Vector__XXX
 SG_ IBST_a015_asicOscillatorError m0 : 18|1@1+ (1,0) [0|1] "" Vector__XXX
 SG_ IBST_a016_RBBLMShaftShiftError m0 : 19|1@1+ (1,0) [0|1] "" Vector__XXX
 SG_ IBST_a017_assertionFault m0 : 20|1@1+ (1,0) [0|1] "" Vector__XXX
 SG_ IBST_a018_unsupportedHW m0 : 21|1@1+ (1,0) [0|1] "" Vector__XXX
 SG_ IBST_a019_supplyASICInitFault m0 : 22|1@1+ (1,0) [0|1] "" Vector__XXX
 SG_ IBST_a020_VPREU5VOutOfRange m0 : 23|1@1+ (1,0) [0|1] "" Vector__XXX
 SG_ IBST_a021_IREFOutOfRange m0 : 24|1@1+ (1,0) [0|1] "" Vector__XXX
 SG_ IBST_a022_U5VTestFault m0 : 25|1@1+ (1,0) [0|1] "" Vector__XXX
 SG_ IBST_a023_U5VOutOfRange m0 : 26|1@1+ (1,0) [0|1] "" Vector__XXX
 SG_ IBST_a024_chargePumpFault m0 : 27|1@1+ (1,0) [0|1] "" Vector__XXX
 SG_ IBST_a025_ecuClockTestFault m0 : 28|1@1+ (1,0) [0|1] "" Vector__XXX
 SG_ IBST_a026_ecuBistCmdTestFault m0 : 29|1@1+ (1,0) [0|1] "" Vector__XXX
 SG_ IBST_a027_ecuFastWdTestFault m0 : 30|1@1+ (1,0) [0|1] "" Vector__XXX
 SG_ IBST_a028_ecuBistFaultCtrFault m0 : 31|1@1+ (1,0) [0|1] "" Vector__XXX
 SG_ IBST_a029_ecuErrpinCounterFault m0 : 32|1@1+ (1,0) [0|1] "" Vector__XXX
 SG_ IBST_a030_ecuEnableElLowFault m0 : 33|1@1+ (1,0) [0|1] "" Vector__XXX
 SG_ IBST_a031_decoupleBitTestFault m0 : 34|1@1+ (1,0) [0|1] "" Vector__XXX
 SG_ IBST_a032_ecuEnableElHighFault m0 : 35|1@1+ (1,0) [0|1] "" Vector__XXX
 SG_ IBST_a033_ecuWdStartuptestFault m0 : 36|1@1+ (1,0) [0|1] "" Vector__XXX
 SG_ IBST_a034_ecuEnableHyHighFault m0 : 37|1@1+ (1,0) [0|1] "" Vector__XXX
 SG_ IBST_a035_ecuEnableHyLowFault m0 : 38|1@1+ (1,0) [0|1] "" Vector__XXX
 SG_ IBST_a036_MRGPathTestFault m0 : 39|1@1+ (1,0) [0|1] "" Vector__XXX
 SG_ IBST_a037_ecuWdSContinuousError m0 : 40|1@1+ (1,0) [0|1] "" Vector__XXX
 SG_ IBST_a038_ecuEnContinuousError m0 : 41|1@1+ (1,0) [0|1] "" Vector__XXX
 SG_ IBST_a039_GTMRefFrequencyError m0 : 42|1@1+ (1,0) [0|1] "" Vector__XXX
 SG_ IBST_a040_GTMTbuMonError m0 : 43|1@1+ (1,0) [0|1] "" Vector__XXX
 SG_ IBST_a041_micAsicClkInError m0 : 44|1@1+ (1,0) [0|1] "" Vector__XXX
 SG_ IBST_a042_micAsicInitTestError m0 : 45|1@1+ (1,0) [0|1] "" Vector__XXX
 SG_ IBST_a043_micSpiTransferError m0 : 46|1@1+ (1,0) [0|1] "" Vector__XXX
 SG_ IBST_a044_NvMEepromWIP m0 : 47|1@1+ (1,0) [0|1] "" Vector__XXX
 SG_ IBST_a045_WdhAsicWdErrorCntStuck m0 : 48|1@1+ (1,0) [0|1] "" Vector__XXX
 SG_ IBST_a046_WdhAsicWdErrorCntLimit m0 : 49|1@1+ (1,0) [0|1] "" Vector__XXX
 SG_ IBST_a047_WdhAsicWdCmdMissing m0 : 50|1@1+ (1,0) [0|1] "" Vector__XXX
 SG_ IBST_a048_WdhSwBistConCnt m0 : 51|1@1+ (1,0) [0|1] "" Vector__XXX
 SG_ IBST_a049_WdhTaskMonConCnt m0 : 52|1@1+ (1,0) [0|1] "" Vector__XXX
 SG_ IBST_a050_VPreExternalFeeding m0 : 53|1@1+ (1,0) [0|1] "" Vector__XXX
 SG_ IBST_a051_ecuBandgap m0 : 54|1@1+ (1,0) [0|1] "" Vector__XXX
 SG_ IBST_a052_AdcPinTest m0 : 55|1@1+ (1,0) [0|1] "" Vector__XXX
 SG_ IBST_a053_AdcSelftestC5P m0 : 56|1@1+ (1,0) [0|1] "" Vector__XXX
 SG_ IBST_a054_AdcPeripheralFault m0 : 57|1@1+ (1,0) [0|1] "" Vector__XXX
 SG_ IBST_a055_UB6SupplyPathFault m0 : 58|1@1+ (1,0) [0|1] "" Vector__XXX
 SG_ IBST_a056_UB6PlausiMonFault m0 : 59|1@1+ (1,0) [0|1] "" Vector__XXX
 SG_ IBST_a057_microRegisterFault m0 : 60|1@1+ (1,0) [0|1] "" Vector__XXX
 SG_ IBST_a058_NvMWriteCycleExceed m0 : 61|1@1+ (1,0) [0|1] "" Vector__XXX
 SG_ IBST_a059_NvMEepromSize m0 : 62|1@1+ (1,0) [0|1] "" Vector__XXX
 SG_ IBST_a060_NvMMigrationFault m0 : 63|1@1+ (1,0) [0|1] "" Vector__XXX
 SG_ IBST_a061_AswSystemTimeOut m1 : 4|1@1+ (1,0) [0|1] "" Vector__XXX
 SG_ IBST_a062_MICB6TransferError m1 : 5|1@1+ (1,0) [0|1] "" Vector__XXX
 SG_ IBST_a063_tempSens2ShortToSupply m1 : 6|1@1+ (1,0) [0|1] "" Vector__XXX
 SG_ IBST_a064_tempSens1ShortToGround m1 : 7|1@1+ (1,0) [0|1] "" Vector__XXX
 SG_ IBST_a065_tempSens2ShortToGround m1 : 8|1@1+ (1,0) [0|1] "" Vector__XXX
 SG_ IBST_a066_tempSens1ShortToSupply m1 : 9|1@1+ (1,0) [0|1] "" Vector__XXX
 SG_ IBST_a067_tempSensImplausVoltage m1 : 10|1@1+ (1,0) [0|1] "" Vector__XXX
 SG_ IBST_a068_chargePumpUndervoltage m1 : 11|1@1+ (1,0) [0|1] "" Vector__XXX
 SG_ IBST_a069_greasingRoutineFault m1 : 12|1@1+ (1,0) [0|1] "" Vector__XXX
 SG_ IBST_a070_notShutDownNvMWrite m1 : 13|1@1+ (1,0) [0|1] "" Vector__XXX
 SG_ IBST_a071_notShutDownNvMRead m1 : 14|1@1+ (1,0) [0|1] "" Vector__XXX
 SG_ IBST_a072_notShutDownRight m1 : 15|1@1+ (1,0) [0|1] "" Vector__XXX
 SG_ IBST_a073_jumpInAdjustNvMRead m1 : 16|1@1+ (1,0) [0|1] "" Vector__XXX
 SG_ IBST_a074_FindIdleDataNvMWrite m1 : 17|1@1+ (1,0) [0|1] "" Vector__XXX
 SG_ IBST_a075_FindIdleRoutineFault m1 : 18|1@1+ (1,0) [0|1] "" Vector__XXX
 SG_ IBST_a076_masterCylLengthRead m1 : 19|1@1+ (1,0) [0|1] "" Vector__XXX
 SG_ IBST_a077_runOutMotorSaturated m1 : 20|1@1+ (1,0) [0|1] "" Vector__XXX
 SG_ IBST_a078_wearOffsetCompNVMRead m1 : 21|1@1+ (1,0) [0|1] "" Vector__XXX
 SG_ IBST_a079_motorTempHighLevel1 m1 : 22|1@1+ (1,0) [0|1] "" Vector__XXX
 SG_ IBST_a080_motorTempHighLevel2 m1 : 23|1@1+ (1,0) [0|1] "" Vector__XXX
 SG_ IBST_a081_travelDeviation m1 : 24|1@1+ (1,0) [0|1] "" Vector__XXX
 SG_ IBST_a082_motorSpeedDeviation m1 : 25|1@1+ (1,0) [0|1] "" Vector__XXX
 SG_ IBST_a083_spindlePositionTooHigh m1 : 26|1@1+ (1,0) [0|1] "" Vector__XXX
 SG_ IBST_a084_CANTransceiverHWFault m1 : 27|1@1+ (1,0) [0|1] "" Vector__XXX
 SG_ IBST_a085_supplyUndervoltageLvl3 m1 : 28|1@1+ (1,0) [0|1] "" Vector__XXX
 SG_ IBST_a086_supplyOvervoltageLvl3 m1 : 29|1@1+ (1,0) [0|1] "" Vector__XXX
 SG_ IBST_a087_rotorSinOutOfRangeLow m1 : 30|1@1+ (1,0) [0|1] "" Vector__XXX
 SG_ IBST_a088_rotorCosOutOfRangeLow m1 : 31|1@1+ (1,0) [0|1] "" Vector__XXX
 SG_ IBST_a089_rotorSinOutOfRangeHigh m1 : 32|1@1+ (1,0) [0|1] "" Vector__XXX
 SG_ IBST_a090_rotorCosOutOfRangeHigh m1 : 33|1@1+ (1,0) [0|1] "" Vector__XXX
 SG_ IBST_a091_SMMOneRequestsInit m1 : 34|1@1+ (1,0) [0|1] "" Vector__XXX
 SG_ IBST_a092_systemStartTimeOut m1 : 35|1@1+ (1,0) [0|1] "" Vector__XXX
 SG_ IBST_a093_UEXSOvertemperature m1 : 36|1@1+ (1,0) [0|1] "" Vector__XXX
 SG_ IBST_a094_XPASSEchoTimeDeviation m1 : 37|1@1+ (1,0) [0|1] "" Vector__XXX
 SG_ IBST_a095_XPASSTimeOut m1 : 38|1@1+ (1,0) [0|1] "" Vector__XXX
 SG_ IBST_a096_bridgeDriverMonError m1 : 39|1@1+ (1,0) [0|1] "" Vector__XXX
 SG_ IBST_a097_bridgeDriverError m1 : 40|1@1+ (1,0) [0|1] "" Vector__XXX
 SG_ IBST_a098_bridgeShortedPhase m1 : 41|1@1+ (1,0) [0|1] "" Vector__XXX
 SG_ IBST_a099_bridgeSwitchInitError m1 : 42|1@1+ (1,0) [0|1] "" Vector__XXX
 SG_ IBST_a100_current2OffsetHigh m1 : 43|1@1+ (1,0) [0|1] "" Vector__XXX
 SG_ IBST_a101_current2OffsetLow m1 : 44|1@1+ (1,0) [0|1] "" Vector__XXX
 SG_ IBST_a102_current1OffsetHigh m1 : 45|1@1+ (1,0) [0|1] "" Vector__XXX
 SG_ IBST_a103_current1OffsetLow m1 : 46|1@1+ (1,0) [0|1] "" Vector__XXX
 SG_ IBST_a104_bridgeDriverShort m1 : 47|1@1+ (1,0) [0|1] "" Vector__XXX
 SG_ IBST_a105_LiPSUndervoltage m1 : 48|1@1+ (1,0) [0|1] "" Vector__XXX
 SG_ IBST_a106_LiPS5VSupply m1 : 49|1@1+ (1,0) [0|1] "" Vector__XXX
 SG_ IBST_a107_LiPS2PwmLineHigh m1 : 50|1@1+ (1,0) [0|1] "" Vector__XXX
 SG_ IBST_a108_LiPS2PwmLineLow m1 : 51|1@1+ (1,0) [0|1] "" Vector__XXX
 SG_ IBST_a109_LiPS2PwmTransmission m1 : 52|1@1+ (1,0) [0|1] "" Vector__XXX
 SG_ IBST_a110_LiPS1SentLineHigh m1 : 53|1@1+ (1,0) [0|1] "" Vector__XXX
 SG_ IBST_a111_LiPS1SentLineLow m1 : 54|1@1+ (1,0) [0|1] "" Vector__XXX
 SG_ IBST_a112_LiPS1SentTransmission m1 : 55|1@1+ (1,0) [0|1] "" Vector__XXX
 SG_ IBST_a113_LiPS1SentSensor m1 : 56|1@1+ (1,0) [0|1] "" Vector__XXX
 SG_ IBST_a114_partyBusOff m1 : 57|1@1+ (1,0) [0|1] "" Vector__XXX
 SG_ IBST_a115_chassisBusOff m1 : 58|1@1+ (1,0) [0|1] "" Vector__XXX
 SG_ IBST_a116_supplyUndervoltageLvl2 m1 : 59|1@1+ (1,0) [0|1] "" Vector__XXX
 SG_ IBST_a117_supplyOvervoltageLvl2 m1 : 60|1@1+ (1,0) [0|1] "" Vector__XXX
 SG_ IBST_a118_RPSNvMReadFault m1 : 61|1@1+ (1,0) [0|1] "" Vector__XXX
 SG_ IBST_a119_RPSWrongCalibData m1 : 62|1@1+ (1,0) [0|1] "" Vector__XXX
 SG_ IBST_a120_RPSVectorRangeHigh m1 : 63|1@1+ (1,0) [0|1] "" Vector__XXX
 SG_ IBST_a121_RPSVectorRangeLow m2 : 4|1@1+ (1,0) [0|1] "" Vector__XXX
 SG_ IBST_a122_RPSVectorOscillating m2 : 5|1@1+ (1,0) [0|1] "" Vector__XXX
 SG_ IBST_a123_bridgeDriverUnavail m2 : 6|1@1+ (1,0) [0|1] "" Vector__XXX
 SG_ IBST_a124_OBDCurrent1OORHigh m2 : 7|1@1+ (1,0) [0|1] "" Vector__XXX
 SG_ IBST_a125_OBDCurrent2OORHigh m2 : 8|1@1+ (1,0) [0|1] "" Vector__XXX
 SG_ IBST_a126_OBDCurrent1OORLow m2 : 9|1@1+ (1,0) [0|1] "" Vector__XXX
 SG_ IBST_a127_OBDCurrent2OORLow m2 : 10|1@1+ (1,0) [0|1] "" Vector__XXX
 SG_ IBST_a128_BLMMuxerTimeoutError m2 : 11|1@1+ (1,0) [0|1] "" Vector__XXX
 SG_ IBST_a129_loadDumpOnFSLTest m2 : 12|1@1+ (1,0) [0|1] "" Vector__XXX
 SG_ IBST_a130_DTSFunctionalRangeLow m2 : 13|1@1+ (1,0) [0|1] "" Vector__XXX
 SG_ IBST_a131_DTSFunctionalRangeHigh m2 : 14|1@1+ (1,0) [0|1] "" Vector__XXX
 SG_ IBST_a132_DTSPlausiCheck1vs2 m2 : 15|1@1+ (1,0) [0|1] "" Vector__XXX
 SG_ IBST_a133_DTSOffsetTooLow m2 : 16|1@1+ (1,0) [0|1] "" Vector__XXX
 SG_ IBST_a134_DTSOffsetTooHigh m2 : 17|1@1+ (1,0) [0|1] "" Vector__XXX
 SG_ IBST_a135_ESPparty1DLC m2 : 18|1@1+ (1,0) [0|1] "" Vector__XXX
 SG_ IBST_a136_ESPparty1Timeout m2 : 19|1@1+ (1,0) [0|1] "" Vector__XXX
 SG_ IBST_a137_ESPparty1Checksum m2 : 20|1@1+ (1,0) [0|1] "" Vector__XXX
 SG_ IBST_a138_ESPparty1Counter m2 : 21|1@1+ (1,0) [0|1] "" Vector__XXX
 SG_ IBST_a139_ESPparty2DLC m2 : 22|1@1+ (1,0) [0|1] "" Vector__XXX
 SG_ IBST_a140_ESPparty2Timeout m2 : 23|1@1+ (1,0) [0|1] "" Vector__XXX
 SG_ IBST_a141_ESPparty2Checksum m2 : 24|1@1+ (1,0) [0|1] "" Vector__XXX
 SG_ IBST_a142_ESPparty2Counter m2 : 25|1@1+ (1,0) [0|1] "" Vector__XXX
 SG_ IBST_a143_ESPparty3DLC m2 : 26|1@1+ (1,0) [0|1] "" Vector__XXX
 SG_ IBST_a144_ESPparty3Timeout m2 : 27|1@1+ (1,0) [0|1] "" Vector__XXX
 SG_ IBST_a145_ESPparty3Checksum m2 : 28|1@1+ (1,0) [0|1] "" Vector__XXX
 SG_ IBST_a146_ESPparty3Counter m2 : 29|1@1+ (1,0) [0|1] "" Vector__XXX
 SG_ IBST_a147_PSCMotorSizeReadFault m2 : 30|1@1+ (1,0) [0|1] "" Vector__XXX
 SG_ IBST_a148_MLIGainMechReadFault m2 : 31|1@1+ (1,0) [0|1] "" Vector__XXX
 SG_ IBST_a149_MLITMCAreaReadFault m2 : 32|1@1+ (1,0) [0|1] "" Vector__XXX
 SG_ IBST_a150_motorTestFault m2 : 33|1@1+ (1,0) [0|1] "" Vector__XXX
 SG_ IBST_a151_PSCGearRatioReadFault m2 : 34|1@1+ (1,0) [0|1] "" Vector__XXX
 SG_ IBST_a152_PSCVoltageImplausible m2 : 35|1@1+ (1,0) [0|1] "" Vector__XXX
 SG_ IBST_a153_unused m2 : 36|1@1+ (1,0) [0|1] "" Vector__XXX
 SG_ IBST_a154_unused m2 : 37|1@1+ (1,0) [0|1] "" Vector__XXX
 SG_ IBST_a155_supplyUndervoltageLvl1 m2 : 38|1@1+ (1,0) [0|1] "" Vector__XXX
 SG_ IBST_a156_supplyOvervoltageLvl1 m2 : 39|1@1+ (1,0) [0|1] "" Vector__XXX
 SG_ IBST_a157_masterCylPressInvalid m2 : 40|1@1+ (1,0) [0|1] "" Vector__XXX
 SG_ IBST_a158_DTSOffsHighSuspicious m2 : 41|1@1+ (1,0) [0|1] "" Vector__XXX
 SG_ IBST_a159_FindIdleNvMReadError m2 : 42|1@1+ (1,0) [0|1] "" Vector__XXX
 SG_ IBST_a160_DTSIDTimeOut m2 : 43|1@1+ (1,0) [0|1] "" Vector__XXX
 SG_ IBST_a161_powerPackMismatch m2 : 44|1@1+ (1,0) [0|1] "" Vector__XXX
 SG_ IBST_a162_idlePosNotDetected m2 : 45|1@1+ (1,0) [0|1] "" Vector__XXX
 SG_ IBST_a163_ESPpEstMaxInvalid m2 : 46|1@1+ (1,0) [0|1] "" Vector__XXX
 SG_ IBST_a164_ESPVehicleSpeedInvalid m2 : 47|1@1+ (1,0) [0|1] "" Vector__XXX
 SG_ IBST_a165_ESPpForceBlendInvalid m2 : 48|1@1+ (1,0) [0|1] "" Vector__XXX
 SG_ IBST_a166_ESPpMcVirtualInvalid m2 : 49|1@1+ (1,0) [0|1] "" Vector__XXX
 SG_ IBST_a167_ESPqTargetExterInvalid m2 : 50|1@1+ (1,0) [0|1] "" Vector__XXX
 SG_ IBST_a168_CANOvervoltage m2 : 51|1@1+ (1,0) [0|1] "" Vector__XXX
 SG_ IBST_a169_CANUndervoltage m2 : 52|1@1+ (1,0) [0|1] "" Vector__XXX
 SG_ IBST_a170_LVPowerStateTimeout m2 : 53|1@1+ (1,0) [0|1] "" Vector__XXX
 SG_ IBST_a171_LVPowerStateChecksum m2 : 54|1@1+ (1,0) [0|1] "" Vector__XXX
 SG_ IBST_a172_LVPowerStateDLC m2 : 55|1@1+ (1,0) [0|1] "" Vector__XXX
 SG_ IBST_a173_LVPowerStateCounter m2 : 56|1@1+ (1,0) [0|1] "" Vector__XXX
 SG_ IBST_a174_LVOffStateInvalid m2 : 57|1@1+ (1,0) [0|1] "" Vector__XXX
 SG_ IBST_a175_LVGoingDownInvalid m2 : 58|1@1+ (1,0) [0|1] "" Vector__XXX
 SG_ IBST_a176_blockedPedalDetected m2 : 59|1@1+ (1,0) [0|1] "" Vector__XXX
 SG_ IBST_a177_EPBLsystemStatusMIA m2 : 60|1@1+ (1,0) [0|1] "" Vector__XXX
 SG_ IBST_a178_EPBRsystemStatusMIA m2 : 61|1@1+ (1,0) [0|1] "" Vector__XXX
 SG_ IBST_a179_VCLEFTepbmStatusMIA m2 : 62|1@1+ (1,0) [0|1] "" Vector__XXX
 SG_ IBST_a180_VCRIGHTepbmStatusMIA m2 : 63|1@1+ (1,0) [0|1] "" Vector__XXX
 SG_ IBST_a181_DIchassisControlDLC m3 : 4|1@1+ (1,0) [0|1] "" Vector__XXX
 SG_ IBST_a182_DIchassisControlTimeou m3 : 5|1@1+ (1,0) [0|1] "" Vector__XXX
 SG_ IBST_a183_DIchassisControlChecks m3 : 6|1@1+ (1,0) [0|1] "" Vector__XXX
 SG_ IBST_a184_DIchassisControlCounte m3 : 7|1@1+ (1,0) [0|1] "" Vector__XXX
 SG_ IBST_a185_rightBusOff m3 : 8|1@1+ (1,0) [0|1] "" Vector__XXX
 SG_ IBST_a186_rightBusPassive m3 : 9|1@1+ (1,0) [0|1] "" Vector__XXX
 SG_ IBST_a187_brakeBusOff m3 : 10|1@1+ (1,0) [0|1] "" Vector__XXX
 SG_ IBST_a188_brakeBusPassive m3 : 11|1@1+ (1,0) [0|1] "" Vector__XXX
 SG_ IBST_a189_rightVCLVPowerStateTim m3 : 12|1@1+ (1,0) [0|1] "" Vector__XXX
 SG_ IBST_a190_rightVCLVPowerStateDLC m3 : 13|1@1+ (1,0) [0|1] "" Vector__XXX
 SG_ IBST_a191_rightVCLVPowerStateChe m3 : 14|1@1+ (1,0) [0|1] "" Vector__XXX
 SG_ IBST_a192_rightVCLVPowerStateCou m3 : 15|1@1+ (1,0) [0|1] "" Vector__XXX
 SG_ IBST_a193_leftVCLVPowerStateTime m3 : 16|1@1+ (1,0) [0|1] "" Vector__XXX
 SG_ IBST_a194_leftVCLVPowerStateChec m3 : 17|1@1+ (1,0) [0|1] "" Vector__XXX
 SG_ IBST_a195_leftVCLVPowerStateDLC m3 : 18|1@1+ (1,0) [0|1] "" Vector__XXX
 SG_ IBST_a196_leftVCLVPowerStateCoun m3 : 19|1@1+ (1,0) [0|1] "" Vector__XXX
 SG_ IBST_a197_brakeLatencyReductionA m3 : 20|1@1+ (1,0) [0|1] "" Vector__XXX
 SG_ IBST_a198_aesActive m3 : 21|1@1+ (1,0) [0|1] "" Vector__XXX
 SG_ IBST_a199_undefinedAlertDetected m3 : 22|1@1+ (1,0) [0|1] "" Vector__XXX
 SG_ IBST_a200_aesFault m3 : 23|1@1+ (1,0) [0|1] "" Vector__XXX
 SG_ IBST_a201_EGGREAR1wheelSpeedsRea m3 : 24|1@1+ (1,0) [0|1] "" Vector__XXX
 SG_ IBST_a202_EGGREAR1wheelSpeedsRea m3 : 25|1@1+ (1,0) [0|1] "" Vector__XXX
 SG_ IBST_a203_EGGREAR1wheelSpeedsRea m3 : 26|1@1+ (1,0) [0|1] "" Vector__XXX
 SG_ IBST_a204_EGGREAR1wheelSpeedsRea m3 : 27|1@1+ (1,0) [0|1] "" Vector__XXX
 SG_ IBST_a205_EGGRIGHT1wheelSpeedsFr m3 : 28|1@1+ (1,0) [0|1] "" Vector__XXX
 SG_ IBST_a206_EGGRIGHT1wheelSpeedsFr m3 : 29|1@1+ (1,0) [0|1] "" Vector__XXX
 SG_ IBST_a207_EGGRIGHT1wheelSpeedsFr m3 : 30|1@1+ (1,0) [0|1] "" Vector__XXX
 SG_ IBST_a208_EGGRIGHT1wheelSpeedsFr m3 : 31|1@1+ (1,0) [0|1] "" Vector__XXX
 SG_ IBST_a209_reducedBrakePowerActiv m3 : 32|1@1+ (1,0) [0|1] "" Vector__XXX
 SG_ IBST_a210_reducedBrakePowerNotAv m3 : 33|1@1+ (1,0) [0|1] "" Vector__XXX
 SG_ IBST_a211_DETReportError m3 : 34|1@1+ (1,0) [0|1] "" Vector__XXX
 SG_ IBST_a212_infoFailureWrongCUBASH m3 : 35|1@1+ (1,0) [0|1] "" Vector__XXX
 SG_ IBST_a213_PDURouterinitializatio m3 : 36|1@1+ (1,0) [0|1] "" Vector__XXX
 SG_ IBST_a214_LossOfPDUInstanceDetec m3 : 37|1@1+ (1,0) [0|1] "" Vector__XXX
 SG_ IBST_a215_UnsupportedSeriesHWDet m3 : 38|1@1+ (1,0) [0|1] "" Vector__XXX
 SG_ IBST_a216_AsicMalfunctionDetecte m3 : 39|1@1+ (1,0) [0|1] "" Vector__XXX
 SG_ IBST_a217_AsicTrimmingNotComplet m3 : 40|1@1+ (1,0) [0|1] "" Vector__XXX
 SG_ IBST_a218_uCSafetyNotificationGR m3 : 41|1@1+ (1,0) [0|1] "" Vector__XXX
 SG_ IBST_a219_uCSafetyNotification m3 : 42|1@1+ (1,0) [0|1] "" Vector__XXX
 SG_ IBST_a220_ASICOvercurrentOnGPIO2 m3 : 43|1@1+ (1,0) [0|1] "" Vector__XXX
 SG_ IBST_a221_ASICOvercurrentOnGPIO2 m3 : 44|1@1+ (1,0) [0|1] "" Vector__XXX
 SG_ IBST_a222_ASICOvercurrentOnGPIO5 m3 : 45|1@1+ (1,0) [0|1] "" Vector__XXX
 SG_ IBST_a223_ASICOvercurrentOnGPIO5 m3 : 46|1@1+ (1,0) [0|1] "" Vector__XXX
 SG_ IBST_a224_ASICOvercurrentOnGPIO5 m3 : 47|1@1+ (1,0) [0|1] "" Vector__XXX
 SG_ IBST_a225_ASICOvercurrentOnGPIO5 m3 : 48|1@1+ (1,0) [0|1] "" Vector__XXX
 SG_ IBST_a226_ASICOvercurrentOnWRHS m3 : 49|1@1+ (1,0) [0|1] "" Vector__XXX
 SG_ IBST_a227_wakeRequestMismatchDet m3 : 50|1@1+ (1,0) [0|1] "" Vector__XXX
 SG_ IBST_a228_BlockedPedalDetectedDu m3 : 51|1@1+ (1,0) [0|1] "" Vector__XXX
 SG_ IBST_a229_BlockedPedalDetected m3 : 52|1@1+ (1,0) [0|1] "" Vector__XXX
 SG_ IBST_a230_DTS2FunctionalRangeLow m3 : 53|1@1+ (1,0) [0|1] "" Vector__XXX
 SG_ IBST_a231_DTS2FunctionalRangeLow m3 : 54|1@1+ (1,0) [0|1] "" Vector__XXX
 SG_ IBST_a232_PostAssemblyRoutineFai m3 : 55|1@1+ (1,0) [0|1] "" Vector__XXX
 SG_ IBST_a233_ReferenceRunAbortByECU m3 : 56|1@1+ (1,0) [0|1] "" Vector__XXX
 SG_ IBST_a234_LiPSOutOfRangeHigh m3 : 57|1@1+ (1,0) [0|1] "" Vector__XXX
 SG_ IBST_a235_LiPSOutOfRangeLow m3 : 58|1@1+ (1,0) [0|1] "" Vector__XXX

BO_ 813 IBST_info: 8 IBST
 SG_ IBST_infoIndex M : 0|8@1+ (1,0) [0|255] "" Vector__XXX
 SG_ IBST_infoBuildType m10 : 8|8@1+ (1,0) [0|255] "" Vector__XXX
 SG_ IBST_infoComponentID m10 : 55|16@0+ (1,0) [0|65535] "" Vector__XXX
 SG_ IBST_infoPcbaID m11 : 16|8@1+ (1,0) [0|255] "" Vector__XXX
 SG_ IBST_infoAssemblyID m11 : 24|8@1+ (1,0) [0|255] "" Vector__XXX
 SG_ IBST_infoUsageID m11 : 32|16@1+ (1,0) [0|65535] "" Vector__XXX
 SG_ IBST_infoSubUsageID m11 : 48|16@1+ (1,0) [0|65535] "" Vector__XXX
 SG_ IBST_infoApplicationCRC m13 : 32|32@1+ (1,0) [0|4294967295] "" Vector__XXX
 SG_ IBST_infoBootUdsProtoVersion m20 : 8|8@1+ (1,0) [0|255] "" Vector__XXX
 SG_ IBST_infoBootloaderCRC m20 : 32|32@1+ (1,0) [0|4294967295] "" Vector__XXX
 SG_ IBST_infoVariantCRC m22 : 32|32@1+ (1,0) [0|4294967295] "" Vector__XXX

BO_ 1486 PARK_alertLog: 8 PARK
 SG_ PARK_alertID M : 0|7@1+ (1,0) [0|127] "" Vector__XXX
 SG_ PARK_alertState : 15|1@1+ (1,0) [0|1] "" Vector__XXX
 SG_ PARK_sw001_sensorTemperature m1 : 16|16@1+ (0.1,-40) [-40|6513.5] "deg" Vector__XXX
 SG_ PARK_sw002_membraneDisconct m2 : 16|1@1+ (1,0) [0|1] "" Vector__XXX
 SG_ PARK_sw002_dampResistorFail m2 : 17|1@1+ (1,0) [0|1] "" Vector__XXX
 SG_ PARK_sw002_resonanceDrift m2 : 18|1@1+ (1,0) [0|1] "" Vector__XXX
 SG_ PARK_sw002_sensorCRC m2 : 19|1@1+ (1,0) [0|1] "" Vector__XXX
 SG_ PARK_sw002_recieveFailure m2 : 20|1@1+ (1,0) [0|1] "" Vector__XXX
 SG_ PARK_sw002_diagnosticTransferErr m2 : 21|1@1+ (1,0) [0|1] "" Vector__XXX
 SG_ PARK_sw003_linError m3 : 16|1@1+ (1,0) [0|1] "" Vector__XXX
 SG_ PARK_sw003_linBusError m3 : 17|1@1+ (1,0) [0|1] "" Vector__XXX
 SG_ PARK_sw003_linFrameCountError m3 : 18|1@1+ (1,0) [0|1] "" Vector__XXX
 SG_ PARK_sw004_reverbPeriod m4 : 16|16@1+ (1,0) [0|65535] "microseconds" Vector__XXX
 SG_ PARK_sw004_reverbTime m4 : 32|16@1+ (1,0) [0|65535] "microseconds" Vector__XXX
 SG_ PARK_sw004_highAttenTime m4 : 48|1@1+ (1,0) [0|1] "" Vector__XXX
 SG_ PARK_sw004_closeConstEcho m4 : 49|1@1+ (1,0) [0|1] "" Vector__XXX
 SG_ PARK_sw004_lowAttenTime m4 : 50|1@1+ (1,0) [0|1] "" Vector__XXX
 SG_ PARK_sw004_attenTimeJitter m4 : 51|1@1+ (1,0) [0|1] "" Vector__XXX
 SG_ PARK_sw004_reverbFreqJitter m4 : 52|1@1+ (1,0) [0|1] "" Vector__XXX
 SG_ PARK_sw006_sensorTemperature m6 : 16|16@1+ (0.1,-40) [-40|6513.5] "deg" Vector__XXX
 SG_ PARK_sw007_membraneDisconct m7 : 16|1@1+ (1,0) [0|1] "" Vector__XXX
 SG_ PARK_sw007_dampResistorFail m7 : 17|1@1+ (1,0) [0|1] "" Vector__XXX
 SG_ PARK_sw007_resonanceDrift m7 : 18|1@1+ (1,0) [0|1] "" Vector__XXX
 SG_ PARK_sw007_sensorCRC m7 : 19|1@1+ (1,0) [0|1] "" Vector__XXX
 SG_ PARK_sw007_recieveFailure m7 : 20|1@1+ (1,0) [0|1] "" Vector__XXX
 SG_ PARK_sw007_diagnosticTransferErr m7 : 21|1@1+ (1,0) [0|1] "" Vector__XXX
 SG_ PARK_sw008_linError m8 : 16|1@1+ (1,0) [0|1] "" Vector__XXX
 SG_ PARK_sw008_linBusError m8 : 17|1@1+ (1,0) [0|1] "" Vector__XXX
 SG_ PARK_sw008_linFrameCountError m8 : 18|1@1+ (1,0) [0|1] "" Vector__XXX
 SG_ PARK_sw009_reverbPeriod m9 : 16|16@1+ (1,0) [0|65535] "microseconds" Vector__XXX
 SG_ PARK_sw009_reverbTime m9 : 32|16@1+ (1,0) [0|65535] "microseconds" Vector__XXX
 SG_ PARK_sw009_highAttenTime m9 : 48|1@1+ (1,0) [0|1] "" Vector__XXX
 SG_ PARK_sw009_closeConstEcho m9 : 49|1@1+ (1,0) [0|1] "" Vector__XXX
 SG_ PARK_sw009_lowAttenTime m9 : 50|1@1+ (1,0) [0|1] "" Vector__XXX
 SG_ PARK_sw009_attenTimeJitter m9 : 51|1@1+ (1,0) [0|1] "" Vector__XXX
 SG_ PARK_sw009_reverbFreqJitter m9 : 52|1@1+ (1,0) [0|1] "" Vector__XXX
 SG_ PARK_sw011_sensorTemperature m11 : 16|16@1+ (0.1,-40) [-40|6513.5] "deg" Vector__XXX
 SG_ PARK_sw012_membraneDisconct m12 : 16|1@1+ (1,0) [0|1] "" Vector__XXX
 SG_ PARK_sw012_dampResistorFail m12 : 17|1@1+ (1,0) [0|1] "" Vector__XXX
 SG_ PARK_sw012_resonanceDrift m12 : 18|1@1+ (1,0) [0|1] "" Vector__XXX
 SG_ PARK_sw012_sensorCRC m12 : 19|1@1+ (1,0) [0|1] "" Vector__XXX
 SG_ PARK_sw012_recieveFailure m12 : 20|1@1+ (1,0) [0|1] "" Vector__XXX
 SG_ PARK_sw012_diagnosticTransferErr m12 : 21|1@1+ (1,0) [0|1] "" Vector__XXX
 SG_ PARK_sw013_linError m13 : 16|1@1+ (1,0) [0|1] "" Vector__XXX
 SG_ PARK_sw013_linBusError m13 : 17|1@1+ (1,0) [0|1] "" Vector__XXX
 SG_ PARK_sw013_linFrameCountError m13 : 18|1@1+ (1,0) [0|1] "" Vector__XXX
 SG_ PARK_sw014_reverbPeriod m14 : 16|16@1+ (1,0) [0|65535] "microseconds" Vector__XXX
 SG_ PARK_sw014_reverbTime m14 : 32|16@1+ (1,0) [0|65535] "microseconds" Vector__XXX
 SG_ PARK_sw014_highAttenTime m14 : 48|1@1+ (1,0) [0|1] "" Vector__XXX
 SG_ PARK_sw014_closeConstEcho m14 : 49|1@1+ (1,0) [0|1] "" Vector__XXX
 SG_ PARK_sw014_lowAttenTime m14 : 50|1@1+ (1,0) [0|1] "" Vector__XXX
 SG_ PARK_sw014_attenTimeJitter m14 : 51|1@1+ (1,0) [0|1] "" Vector__XXX
 SG_ PARK_sw014_reverbFreqJitter m14 : 52|1@1+ (1,0) [0|1] "" Vector__XXX
 SG_ PARK_sw016_sensorTemperature m16 : 16|16@1+ (0.1,-40) [-40|6513.5] "deg" Vector__XXX
 SG_ PARK_sw017_membraneDisconct m17 : 16|1@1+ (1,0) [0|1] "" Vector__XXX
 SG_ PARK_sw017_dampResistorFail m17 : 17|1@1+ (1,0) [0|1] "" Vector__XXX
 SG_ PARK_sw017_resonanceDrift m17 : 18|1@1+ (1,0) [0|1] "" Vector__XXX
 SG_ PARK_sw017_sensorCRC m17 : 19|1@1+ (1,0) [0|1] "" Vector__XXX
 SG_ PARK_sw017_recieveFailure m17 : 20|1@1+ (1,0) [0|1] "" Vector__XXX
 SG_ PARK_sw017_diagnosticTransferErr m17 : 21|1@1+ (1,0) [0|1] "" Vector__XXX
 SG_ PARK_sw018_linError m18 : 16|1@1+ (1,0) [0|1] "" Vector__XXX
 SG_ PARK_sw018_linBusError m18 : 17|1@1+ (1,0) [0|1] "" Vector__XXX
 SG_ PARK_sw018_linFrameCountError m18 : 18|1@1+ (1,0) [0|1] "" Vector__XXX
 SG_ PARK_sw019_reverbPeriod m19 : 16|16@1+ (1,0) [0|65535] "microseconds" Vector__XXX
 SG_ PARK_sw019_reverbTime m19 : 32|16@1+ (1,0) [0|65535] "microseconds" Vector__XXX
 SG_ PARK_sw019_highAttenTime m19 : 48|1@1+ (1,0) [0|1] "" Vector__XXX
 SG_ PARK_sw019_closeConstEcho m19 : 49|1@1+ (1,0) [0|1] "" Vector__XXX
 SG_ PARK_sw019_lowAttenTime m19 : 50|1@1+ (1,0) [0|1] "" Vector__XXX
 SG_ PARK_sw019_attenTimeJitter m19 : 51|1@1+ (1,0) [0|1] "" Vector__XXX
 SG_ PARK_sw019_reverbFreqJitter m19 : 52|1@1+ (1,0) [0|1] "" Vector__XXX
 SG_ PARK_sw021_sensorTemperature m21 : 16|16@1+ (0.1,-40) [-40|6513.5] "deg" Vector__XXX
 SG_ PARK_sw022_membraneDisconct m22 : 16|1@1+ (1,0) [0|1] "" Vector__XXX
 SG_ PARK_sw022_dampResistorFail m22 : 17|1@1+ (1,0) [0|1] "" Vector__XXX
 SG_ PARK_sw022_resonanceDrift m22 : 18|1@1+ (1,0) [0|1] "" Vector__XXX
 SG_ PARK_sw022_sensorCRC m22 : 19|1@1+ (1,0) [0|1] "" Vector__XXX
 SG_ PARK_sw022_recieveFailure m22 : 20|1@1+ (1,0) [0|1] "" Vector__XXX
 SG_ PARK_sw022_diagnosticTransferErr m22 : 21|1@1+ (1,0) [0|1] "" Vector__XXX
 SG_ PARK_sw023_linError m23 : 16|1@1+ (1,0) [0|1] "" Vector__XXX
 SG_ PARK_sw023_linBusError m23 : 17|1@1+ (1,0) [0|1] "" Vector__XXX
 SG_ PARK_sw023_linFrameCountError m23 : 18|1@1+ (1,0) [0|1] "" Vector__XXX
 SG_ PARK_sw024_reverbPeriod m24 : 16|16@1+ (1,0) [0|65535] "microseconds" Vector__XXX
 SG_ PARK_sw024_reverbTime m24 : 32|16@1+ (1,0) [0|65535] "microseconds" Vector__XXX
 SG_ PARK_sw024_highAttenTime m24 : 48|1@1+ (1,0) [0|1] "" Vector__XXX
 SG_ PARK_sw024_closeConstEcho m24 : 49|1@1+ (1,0) [0|1] "" Vector__XXX
 SG_ PARK_sw024_lowAttenTime m24 : 50|1@1+ (1,0) [0|1] "" Vector__XXX
 SG_ PARK_sw024_attenTimeJitter m24 : 51|1@1+ (1,0) [0|1] "" Vector__XXX
 SG_ PARK_sw024_reverbFreqJitter m24 : 52|1@1+ (1,0) [0|1] "" Vector__XXX
 SG_ PARK_sw026_sensorTemperature m26 : 16|16@1+ (0.1,-40) [-40|6513.5] "deg" Vector__XXX
 SG_ PARK_sw027_membraneDisconct m27 : 16|1@1+ (1,0) [0|1] "" Vector__XXX
 SG_ PARK_sw027_dampResistorFail m27 : 17|1@1+ (1,0) [0|1] "" Vector__XXX
 SG_ PARK_sw027_resonanceDrift m27 : 18|1@1+ (1,0) [0|1] "" Vector__XXX
 SG_ PARK_sw027_sensorCRC m27 : 19|1@1+ (1,0) [0|1] "" Vector__XXX
 SG_ PARK_sw027_recieveFailure m27 : 20|1@1+ (1,0) [0|1] "" Vector__XXX
 SG_ PARK_sw027_diagnosticTransferErr m27 : 21|1@1+ (1,0) [0|1] "" Vector__XXX
 SG_ PARK_sw028_linError m28 : 16|1@1+ (1,0) [0|1] "" Vector__XXX
 SG_ PARK_sw028_linBusError m28 : 17|1@1+ (1,0) [0|1] "" Vector__XXX
 SG_ PARK_sw028_linFrameCountError m28 : 18|1@1+ (1,0) [0|1] "" Vector__XXX
 SG_ PARK_sw029_reverbPeriod m29 : 16|16@1+ (1,0) [0|65535] "microseconds" Vector__XXX
 SG_ PARK_sw029_reverbTime m29 : 32|16@1+ (1,0) [0|65535] "microseconds" Vector__XXX
 SG_ PARK_sw029_highAttenTime m29 : 48|1@1+ (1,0) [0|1] "" Vector__XXX
 SG_ PARK_sw029_closeConstEcho m29 : 49|1@1+ (1,0) [0|1] "" Vector__XXX
 SG_ PARK_sw029_lowAttenTime m29 : 50|1@1+ (1,0) [0|1] "" Vector__XXX
 SG_ PARK_sw029_attenTimeJitter m29 : 51|1@1+ (1,0) [0|1] "" Vector__XXX
 SG_ PARK_sw029_reverbFreqJitter m29 : 52|1@1+ (1,0) [0|1] "" Vector__XXX
 SG_ PARK_sw031_sensorTemperature m31 : 16|16@1+ (0.1,-40) [-40|6513.5] "deg" Vector__XXX
 SG_ PARK_sw032_membraneDisconct m32 : 16|1@1+ (1,0) [0|1] "" Vector__XXX
 SG_ PARK_sw032_dampResistorFail m32 : 17|1@1+ (1,0) [0|1] "" Vector__XXX
 SG_ PARK_sw032_resonanceDrift m32 : 18|1@1+ (1,0) [0|1] "" Vector__XXX
 SG_ PARK_sw032_sensorCRC m32 : 19|1@1+ (1,0) [0|1] "" Vector__XXX
 SG_ PARK_sw032_recieveFailure m32 : 20|1@1+ (1,0) [0|1] "" Vector__XXX
 SG_ PARK_sw032_diagnosticTransferErr m32 : 21|1@1+ (1,0) [0|1] "" Vector__XXX
 SG_ PARK_sw033_linError m33 : 16|1@1+ (1,0) [0|1] "" Vector__XXX
 SG_ PARK_sw033_linBusError m33 : 17|1@1+ (1,0) [0|1] "" Vector__XXX
 SG_ PARK_sw033_linFrameCountError m33 : 18|1@1+ (1,0) [0|1] "" Vector__XXX
 SG_ PARK_sw034_reverbPeriod m34 : 16|16@1+ (1,0) [0|65535] "microseconds" Vector__XXX
 SG_ PARK_sw034_reverbTime m34 : 32|16@1+ (1,0) [0|65535] "microseconds" Vector__XXX
 SG_ PARK_sw034_highAttenTime m34 : 48|1@1+ (1,0) [0|1] "" Vector__XXX
 SG_ PARK_sw034_closeConstEcho m34 : 49|1@1+ (1,0) [0|1] "" Vector__XXX
 SG_ PARK_sw034_lowAttenTime m34 : 50|1@1+ (1,0) [0|1] "" Vector__XXX
 SG_ PARK_sw034_attenTimeJitter m34 : 51|1@1+ (1,0) [0|1] "" Vector__XXX
 SG_ PARK_sw034_reverbFreqJitter m34 : 52|1@1+ (1,0) [0|1] "" Vector__XXX
 SG_ PARK_sw036_sensorTemperature m36 : 16|16@1+ (0.1,-40) [-40|6513.5] "deg" Vector__XXX
 SG_ PARK_sw037_membraneDisconct m37 : 16|1@1+ (1,0) [0|1] "" Vector__XXX
 SG_ PARK_sw037_dampResistorFail m37 : 17|1@1+ (1,0) [0|1] "" Vector__XXX
 SG_ PARK_sw037_resonanceDrift m37 : 18|1@1+ (1,0) [0|1] "" Vector__XXX
 SG_ PARK_sw037_sensorCRC m37 : 19|1@1+ (1,0) [0|1] "" Vector__XXX
 SG_ PARK_sw037_recieveFailure m37 : 20|1@1+ (1,0) [0|1] "" Vector__XXX
 SG_ PARK_sw037_diagnosticTransferErr m37 : 21|1@1+ (1,0) [0|1] "" Vector__XXX
 SG_ PARK_sw038_linError m38 : 16|1@1+ (1,0) [0|1] "" Vector__XXX
 SG_ PARK_sw038_linBusError m38 : 17|1@1+ (1,0) [0|1] "" Vector__XXX
 SG_ PARK_sw038_linFrameCountError m38 : 18|1@1+ (1,0) [0|1] "" Vector__XXX
 SG_ PARK_sw039_reverbPeriod m39 : 16|16@1+ (1,0) [0|65535] "microseconds" Vector__XXX
 SG_ PARK_sw039_reverbTime m39 : 32|16@1+ (1,0) [0|65535] "microseconds" Vector__XXX
 SG_ PARK_sw039_highAttenTime m39 : 48|1@1+ (1,0) [0|1] "" Vector__XXX
 SG_ PARK_sw039_closeConstEcho m39 : 49|1@1+ (1,0) [0|1] "" Vector__XXX
 SG_ PARK_sw039_lowAttenTime m39 : 50|1@1+ (1,0) [0|1] "" Vector__XXX
 SG_ PARK_sw039_attenTimeJitter m39 : 51|1@1+ (1,0) [0|1] "" Vector__XXX
 SG_ PARK_sw039_reverbFreqJitter m39 : 52|1@1+ (1,0) [0|1] "" Vector__XXX
 SG_ PARK_sw041_sensorTemperature m41 : 16|16@1+ (0.1,-40) [-40|6513.5] "deg" Vector__XXX
 SG_ PARK_sw042_membraneDisconct m42 : 16|1@1+ (1,0) [0|1] "" Vector__XXX
 SG_ PARK_sw042_dampResistorFail m42 : 17|1@1+ (1,0) [0|1] "" Vector__XXX
 SG_ PARK_sw042_resonanceDrift m42 : 18|1@1+ (1,0) [0|1] "" Vector__XXX
 SG_ PARK_sw042_sensorCRC m42 : 19|1@1+ (1,0) [0|1] "" Vector__XXX
 SG_ PARK_sw042_recieveFailure m42 : 20|1@1+ (1,0) [0|1] "" Vector__XXX
 SG_ PARK_sw042_diagnosticTransferErr m42 : 21|1@1+ (1,0) [0|1] "" Vector__XXX
 SG_ PARK_sw043_linError m43 : 16|1@1+ (1,0) [0|1] "" Vector__XXX
 SG_ PARK_sw043_linBusError m43 : 17|1@1+ (1,0) [0|1] "" Vector__XXX
 SG_ PARK_sw043_linFrameCountError m43 : 18|1@1+ (1,0) [0|1] "" Vector__XXX
 SG_ PARK_sw044_reverbPeriod m44 : 16|16@1+ (1,0) [0|65535] "microseconds" Vector__XXX
 SG_ PARK_sw044_reverbTime m44 : 32|16@1+ (1,0) [0|65535] "microseconds" Vector__XXX
 SG_ PARK_sw044_highAttenTime m44 : 48|1@1+ (1,0) [0|1] "" Vector__XXX
 SG_ PARK_sw044_closeConstEcho m44 : 49|1@1+ (1,0) [0|1] "" Vector__XXX
 SG_ PARK_sw044_lowAttenTime m44 : 50|1@1+ (1,0) [0|1] "" Vector__XXX
 SG_ PARK_sw044_attenTimeJitter m44 : 51|1@1+ (1,0) [0|1] "" Vector__XXX
 SG_ PARK_sw044_reverbFreqJitter m44 : 52|1@1+ (1,0) [0|1] "" Vector__XXX
 SG_ PARK_sw046_sensorTemperature m46 : 16|16@1+ (0.1,-40) [-40|6513.5] "deg" Vector__XXX
 SG_ PARK_sw047_membraneDisconct m47 : 16|1@1+ (1,0) [0|1] "" Vector__XXX
 SG_ PARK_sw047_dampResistorFail m47 : 17|1@1+ (1,0) [0|1] "" Vector__XXX
 SG_ PARK_sw047_resonanceDrift m47 : 18|1@1+ (1,0) [0|1] "" Vector__XXX
 SG_ PARK_sw047_sensorCRC m47 : 19|1@1+ (1,0) [0|1] "" Vector__XXX
 SG_ PARK_sw047_recieveFailure m47 : 20|1@1+ (1,0) [0|1] "" Vector__XXX
 SG_ PARK_sw047_diagnosticTransferErr m47 : 21|1@1+ (1,0) [0|1] "" Vector__XXX
 SG_ PARK_sw048_linError m48 : 16|1@1+ (1,0) [0|1] "" Vector__XXX
 SG_ PARK_sw048_linBusError m48 : 17|1@1+ (1,0) [0|1] "" Vector__XXX
 SG_ PARK_sw048_linFrameCountError m48 : 18|1@1+ (1,0) [0|1] "" Vector__XXX
 SG_ PARK_sw049_reverbPeriod m49 : 16|16@1+ (1,0) [0|65535] "microseconds" Vector__XXX
 SG_ PARK_sw049_reverbTime m49 : 32|16@1+ (1,0) [0|65535] "microseconds" Vector__XXX
 SG_ PARK_sw049_highAttenTime m49 : 48|1@1+ (1,0) [0|1] "" Vector__XXX
 SG_ PARK_sw049_closeConstEcho m49 : 49|1@1+ (1,0) [0|1] "" Vector__XXX
 SG_ PARK_sw049_lowAttenTime m49 : 50|1@1+ (1,0) [0|1] "" Vector__XXX
 SG_ PARK_sw049_attenTimeJitter m49 : 51|1@1+ (1,0) [0|1] "" Vector__XXX
 SG_ PARK_sw049_reverbFreqJitter m49 : 52|1@1+ (1,0) [0|1] "" Vector__XXX
 SG_ PARK_sw051_sensorTemperature m51 : 16|16@1+ (0.1,-40) [-40|6513.5] "deg" Vector__XXX
 SG_ PARK_sw052_membraneDisconct m52 : 16|1@1+ (1,0) [0|1] "" Vector__XXX
 SG_ PARK_sw052_dampResistorFail m52 : 17|1@1+ (1,0) [0|1] "" Vector__XXX
 SG_ PARK_sw052_resonanceDrift m52 : 18|1@1+ (1,0) [0|1] "" Vector__XXX
 SG_ PARK_sw052_sensorCRC m52 : 19|1@1+ (1,0) [0|1] "" Vector__XXX
 SG_ PARK_sw052_recieveFailure m52 : 20|1@1+ (1,0) [0|1] "" Vector__XXX
 SG_ PARK_sw052_diagnosticTransferErr m52 : 21|1@1+ (1,0) [0|1] "" Vector__XXX
 SG_ PARK_sw053_linError m53 : 16|1@1+ (1,0) [0|1] "" Vector__XXX
 SG_ PARK_sw053_linBusError m53 : 17|1@1+ (1,0) [0|1] "" Vector__XXX
 SG_ PARK_sw053_linFrameCountError m53 : 18|1@1+ (1,0) [0|1] "" Vector__XXX
 SG_ PARK_sw054_reverbPeriod m54 : 16|16@1+ (1,0) [0|65535] "microseconds" Vector__XXX
 SG_ PARK_sw054_reverbTime m54 : 32|16@1+ (1,0) [0|65535] "microseconds" Vector__XXX
 SG_ PARK_sw054_highAttenTime m54 : 48|1@1+ (1,0) [0|1] "" Vector__XXX
 SG_ PARK_sw054_closeConstEcho m54 : 49|1@1+ (1,0) [0|1] "" Vector__XXX
 SG_ PARK_sw054_lowAttenTime m54 : 50|1@1+ (1,0) [0|1] "" Vector__XXX
 SG_ PARK_sw054_attenTimeJitter m54 : 51|1@1+ (1,0) [0|1] "" Vector__XXX
 SG_ PARK_sw054_reverbFreqJitter m54 : 52|1@1+ (1,0) [0|1] "" Vector__XXX
 SG_ PARK_sw056_sensorTemperature m56 : 16|16@1+ (0.1,-40) [-40|6513.5] "deg" Vector__XXX
 SG_ PARK_sw057_membraneDisconct m57 : 16|1@1+ (1,0) [0|1] "" Vector__XXX
 SG_ PARK_sw057_dampResistorFail m57 : 17|1@1+ (1,0) [0|1] "" Vector__XXX
 SG_ PARK_sw057_resonanceDrift m57 : 18|1@1+ (1,0) [0|1] "" Vector__XXX
 SG_ PARK_sw057_sensorCRC m57 : 19|1@1+ (1,0) [0|1] "" Vector__XXX
 SG_ PARK_sw057_recieveFailure m57 : 20|1@1+ (1,0) [0|1] "" Vector__XXX
 SG_ PARK_sw057_diagnosticTransferErr m57 : 21|1@1+ (1,0) [0|1] "" Vector__XXX
 SG_ PARK_sw058_linError m58 : 16|1@1+ (1,0) [0|1] "" Vector__XXX
 SG_ PARK_sw058_linBusError m58 : 17|1@1+ (1,0) [0|1] "" Vector__XXX
 SG_ PARK_sw058_linFrameCountError m58 : 18|1@1+ (1,0) [0|1] "" Vector__XXX
 SG_ PARK_sw059_reverbPeriod m59 : 16|16@1+ (1,0) [0|65535] "microseconds" Vector__XXX
 SG_ PARK_sw059_reverbTime m59 : 32|16@1+ (1,0) [0|65535] "microseconds" Vector__XXX
 SG_ PARK_sw059_highAttenTime m59 : 48|1@1+ (1,0) [0|1] "" Vector__XXX
 SG_ PARK_sw059_closeConstEcho m59 : 49|1@1+ (1,0) [0|1] "" Vector__XXX
 SG_ PARK_sw059_lowAttenTime m59 : 50|1@1+ (1,0) [0|1] "" Vector__XXX
 SG_ PARK_sw059_attenTimeJitter m59 : 51|1@1+ (1,0) [0|1] "" Vector__XXX
 SG_ PARK_sw059_reverbFreqJitter m59 : 52|1@1+ (1,0) [0|1] "" Vector__XXX
 SG_ PARK_sw061_voltage m61 : 16|16@1+ (0.1,0) [0|6553.5] "volts" Vector__XXX
 SG_ PARK_sw063_voltage m63 : 16|16@1+ (0.1,0) [0|6553.5] "volts" Vector__XXX
 SG_ PARK_sw064_faultCode m64 : 16|8@1+ (1,0) [0|255] "" Vector__XXX
 SG_ PARK_sw065_expectedCRC m65 : 16|16@1+ (1,0) [0|65535] "" Vector__XXX
 SG_ PARK_sw065_calculatedCRC m65 : 32|16@1+ (1,0) [0|65535] "" Vector__XXX
 SG_ PARK_sw066_placeHolder m66 : 16|1@1+ (1,0) [0|1] "" Vector__XXX
 SG_ PARK_sw068_placeHolder m68 : 16|1@1+ (1,0) [0|1] "" Vector__XXX
 SG_ PARK_sw069_messageID m69 : 16|16@1+ (1,0) [0|65535] "" Vector__XXX
 SG_ PARK_sw070_messageID m70 : 16|16@1+ (1,0) [0|65535] "" Vector__XXX
 SG_ PARK_sw071_messageID m71 : 16|16@1+ (1,0) [0|65535] "" Vector__XXX
 SG_ PARK_sw072_messageID m72 : 16|16@1+ (1,0) [0|65535] "" Vector__XXX
 SG_ PARK_sw073_messageID m73 : 16|16@1+ (1,0) [0|65535] "" Vector__XXX
 SG_ PARK_sw074_messageID m74 : 16|16@1+ (1,0) [0|65535] "" Vector__XXX
 SG_ PARK_sw075_messageID m75 : 16|16@1+ (1,0) [0|65535] "" Vector__XXX
 SG_ PARK_sw076_messageID m76 : 16|16@1+ (1,0) [0|65535] "" Vector__XXX
 SG_ PARK_sw077_errorExp m77 : 16|8@1+ (1,0) [0|255] "" Vector__XXX
 SG_ PARK_sw077_errorRx m77 : 24|8@1+ (1,0) [0|255] "" Vector__XXX
 SG_ PARK_sw077_messageID m77 : 32|12@1+ (1,0) [0|4095] "" Vector__XXX
 SG_ PARK_sw077_errorType m77 : 44|3@1+ (1,0) [0|7] "" Vector__XXX
 SG_ PARK_sw078_errorExp m78 : 16|8@1+ (1,0) [0|255] "" Vector__XXX
 SG_ PARK_sw078_errorRx m78 : 24|8@1+ (1,0) [0|255] "" Vector__XXX
 SG_ PARK_sw078_messageID m78 : 32|12@1+ (1,0) [0|4095] "" Vector__XXX
 SG_ PARK_sw078_errorType m78 : 44|3@1+ (1,0) [0|7] "" Vector__XXX
 SG_ PARK_sw079_errorExp m79 : 16|8@1+ (1,0) [0|255] "" Vector__XXX
 SG_ PARK_sw079_errorRx m79 : 24|8@1+ (1,0) [0|255] "" Vector__XXX
 SG_ PARK_sw079_messageID m79 : 32|12@1+ (1,0) [0|4095] "" Vector__XXX
 SG_ PARK_sw079_errorType m79 : 44|3@1+ (1,0) [0|7] "" Vector__XXX
 SG_ PARK_sw080_errorExp m80 : 16|8@1+ (1,0) [0|255] "" Vector__XXX
 SG_ PARK_sw080_errorRx m80 : 24|8@1+ (1,0) [0|255] "" Vector__XXX
 SG_ PARK_sw080_messageID m80 : 32|12@1+ (1,0) [0|4095] "" Vector__XXX
 SG_ PARK_sw080_errorType m80 : 44|3@1+ (1,0) [0|7] "" Vector__XXX
 SG_ PARK_sw081_errorExp m81 : 16|8@1+ (1,0) [0|255] "" Vector__XXX
 SG_ PARK_sw081_errorRx m81 : 24|8@1+ (1,0) [0|255] "" Vector__XXX
 SG_ PARK_sw081_messageID m81 : 32|12@1+ (1,0) [0|4095] "" Vector__XXX
 SG_ PARK_sw081_errorType m81 : 44|3@1+ (1,0) [0|7] "" Vector__XXX
 SG_ PARK_sw082_errorExp m82 : 16|8@1+ (1,0) [0|255] "" Vector__XXX
 SG_ PARK_sw082_errorRx m82 : 24|8@1+ (1,0) [0|255] "" Vector__XXX
 SG_ PARK_sw082_messageID m82 : 32|12@1+ (1,0) [0|4095] "" Vector__XXX
 SG_ PARK_sw082_errorType m82 : 44|3@1+ (1,0) [0|7] "" Vector__XXX
 SG_ PARK_sw083_errorExp m83 : 16|8@1+ (1,0) [0|255] "" Vector__XXX
 SG_ PARK_sw083_errorRx m83 : 24|8@1+ (1,0) [0|255] "" Vector__XXX
 SG_ PARK_sw083_messageID m83 : 32|12@1+ (1,0) [0|4095] "" Vector__XXX
 SG_ PARK_sw083_errorType m83 : 44|3@1+ (1,0) [0|7] "" Vector__XXX
 SG_ PARK_sw084_errorExp m84 : 16|8@1+ (1,0) [0|255] "" Vector__XXX
 SG_ PARK_sw084_errorRx m84 : 24|8@1+ (1,0) [0|255] "" Vector__XXX
 SG_ PARK_sw084_messageID m84 : 32|12@1+ (1,0) [0|4095] "" Vector__XXX
 SG_ PARK_sw084_errorType m84 : 44|3@1+ (1,0) [0|7] "" Vector__XXX
 SG_ PARK_sw086_writeRetryCounter m86 : 16|8@1+ (1,0) [0|255] "" Vector__XXX
 SG_ PARK_sw086_readRetryCounter m86 : 24|8@1+ (1,0) [0|255] "" Vector__XXX
 SG_ PARK_sw086_currentErrorCode m86 : 32|8@1+ (1,0) [0|255] "" Vector__XXX
 SG_ PARK_sw087_s1_sensorType m87 : 16|2@1+ (1,0) [0|2] "" Vector__XXX
 SG_ PARK_sw087_s2_sensorType m87 : 18|2@1+ (1,0) [0|2] "" Vector__XXX
 SG_ PARK_sw087_s3_sensorType m87 : 20|2@1+ (1,0) [0|2] "" Vector__XXX
 SG_ PARK_sw087_s4_sensorType m87 : 22|2@1+ (1,0) [0|2] "" Vector__XXX
 SG_ PARK_sw087_s5_sensorType m87 : 24|2@1+ (1,0) [0|2] "" Vector__XXX
 SG_ PARK_sw087_s6_sensorType m87 : 26|2@1+ (1,0) [0|2] "" Vector__XXX
 SG_ PARK_sw087_s7_sensorType m87 : 28|2@1+ (1,0) [0|2] "" Vector__XXX
 SG_ PARK_sw087_s8_sensorType m87 : 30|2@1+ (1,0) [0|2] "" Vector__XXX
 SG_ PARK_sw087_s9_sensorType m87 : 32|2@1+ (1,0) [0|2] "" Vector__XXX
 SG_ PARK_sw087_s10_sensorType m87 : 34|2@1+ (1,0) [0|2] "" Vector__XXX
 SG_ PARK_sw087_s11_sensorType m87 : 36|2@1+ (1,0) [0|2] "" Vector__XXX
 SG_ PARK_sw087_s12_sensorType m87 : 38|2@1+ (1,0) [0|2] "" Vector__XXX

BO_ 806 PARK_info: 8 PARK
 SG_ PARK_infoIndex M : 0|8@1+ (1,0) [0|255] "" Vector__XXX
 SG_ PARK_infoBuildType m10 : 8|8@1+ (1,0) [0|255] "" Vector__XXX
 SG_ PARK_infoComponentID m10 : 48|16@1+ (1,0) [0|65535] "" Vector__XXX
 SG_ PARK_infoPcbaID m11 : 16|8@1+ (1,0) [0|255] "" Vector__XXX
 SG_ PARK_infoAssemblyID m11 : 24|8@1+ (1,0) [0|255] "" Vector__XXX
 SG_ PARK_infoUsageID m11 : 32|16@1+ (1,0) [0|65535] "" Vector__XXX
 SG_ PARK_infoApplicationCRC m13 : 32|32@1+ (1,0) [0|4294967295] "" Vector__XXX
 SG_ PARK_infoBootUdsProtoVersion m20 : 8|8@1+ (1,0) [0|255] "" Vector__XXX
 SG_ PARK_infoBootloaderCRC m20 : 32|32@1+ (1,0) [0|4294967295] "" Vector__XXX

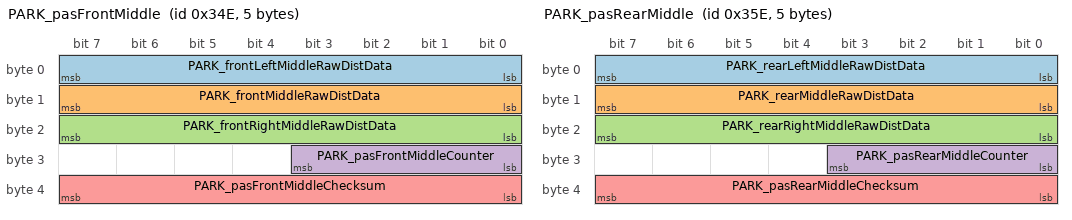
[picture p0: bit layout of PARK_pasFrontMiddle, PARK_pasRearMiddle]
BO_ 846 PARK_pasFrontMiddle: 5 PARK
 SG_ PARK_frontLeftMiddleRawDistData : 0|8@1+ (1,0) [0|254] "cm" Vector__XXX
 SG_ PARK_frontMiddleRawDistData : 8|8@1+ (1,0) [0|254] "cm" Vector__XXX
 SG_ PARK_frontRightMiddleRawDistData : 16|8@1+ (1,0) [0|254] "cm" Vector__XXX
 SG_ PARK_pasFrontMiddleCounter : 24|4@1+ (1,0) [0|15] "" Vector__XXX
 SG_ PARK_pasFrontMiddleChecksum : 32|8@1+ (1,0) [0|255] "" Vector__XXX

BO_ 862 PARK_pasRearMiddle: 5 PARK
 SG_ PARK_rearLeftMiddleRawDistData : 0|8@1+ (1,0) [0|254] "cm" Vector__XXX
 SG_ PARK_rearMiddleRawDistData : 8|8@1+ (1,0) [0|254] "cm" Vector__XXX
 SG_ PARK_rearRightMiddleRawDistData : 16|8@1+ (1,0) [0|254] "cm" Vector__XXX
 SG_ PARK_pasRearMiddleCounter : 24|4@1+ (1,0) [0|15] "" Vector__XXX
 SG_ PARK_pasRearMiddleChecksum : 32|8@1+ (1,0) [0|255] "" Vector__XXX

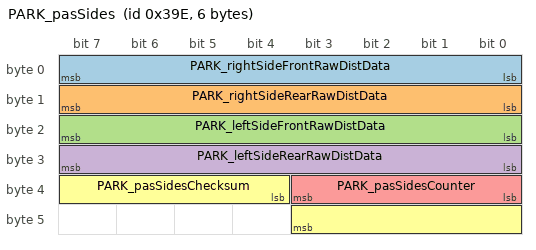
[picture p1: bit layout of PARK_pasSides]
BO_ 926 PARK_pasSides: 6 PARK
 SG_ PARK_rightSideFrontRawDistData : 0|8@1+ (1,0) [0|254] "cm" Vector__XXX
 SG_ PARK_rightSideRearRawDistData : 8|8@1+ (1,0) [0|254] "cm" Vector__XXX
 SG_ PARK_leftSideFrontRawDistData : 16|8@1+ (1,0) [0|254] "cm" Vector__XXX
 SG_ PARK_leftSideRearRawDistData : 24|8@1+ (1,0) [0|254] "cm" Vector__XXX
 SG_ PARK_pasSidesCounter : 32|4@1+ (1,0) [0|15] "" Vector__XXX
 SG_ PARK_pasSidesChecksum : 36|8@1+ (1,0) [0|255] "" Vector__XXX

BO_ 606 PARK_pscEnvSlot: 8 PARK
 SG_ PARK_pscEnvSlotType M : 0|2@1+ (1,0) [0|3] "" Vector__XXX
 SG_ PARK_pscLeftParallelObj1X m0 : 3|11@1+ (2,-2048) [-2048|2044] "cm" Vector__XXX
 SG_ PARK_pscLeftParallelObj1Y m0 : 14|11@1+ (2,-2048) [-2048|2044] "cm" Vector__XXX
 SG_ PARK_pscLeftParallelObj1Alpha m0 : 25|7@1+ (2,-128) [-128|124] "deg" Vector__XXX
 SG_ PARK_pscLeftParallelObj2Y m0 : 35|11@1+ (2,-2048) [-2048|2044] "cm" Vector__XXX
 SG_ PARK_pscLeftParallelObj2X m0 : 46|11@1+ (2,-2048) [-2048|2044] "cm" Vector__XXX
 SG_ PARK_pscLeftParallelObj2Alpha m0 : 57|7@1+ (2,-128) [-128|124] "deg" Vector__XXX
 SG_ PARK_pscLeftCrossObj1X m1 : 3|11@1+ (2,-2048) [-2048|2044] "cm" Vector__XXX
 SG_ PARK_pscLeftCrossObj1Y m1 : 14|11@1+ (2,-2048) [-2048|2044] "cm" Vector__XXX
 SG_ PARK_pscLeftCrossObj1Alpha m1 : 25|7@1+ (2,-128) [-128|124] "deg" Vector__XXX
 SG_ PARK_pscLeftCrossObj2Y m1 : 35|11@1+ (2,-2048) [-2048|2044] "cm" Vector__XXX
 SG_ PARK_pscLeftCrossObj2X m1 : 46|11@1+ (2,-2048) [-2048|2044] "cm" Vector__XXX
 SG_ PARK_pscLeftCrossObj2Alpha m1 : 57|7@1+ (2,-128) [-128|124] "deg" Vector__XXX
 SG_ PARK_pscRightParallelObj1X m2 : 3|11@1+ (2,-2048) [-2048|2044] "cm" Vector__XXX
 SG_ PARK_pscRightParallelObj1Y m2 : 14|11@1+ (2,-2048) [-2048|2044] "cm" Vector__XXX
 SG_ PARK_pscRightParallelObj1Alpha m2 : 25|7@1+ (2,-128) [-128|124] "deg" Vector__XXX
 SG_ PARK_pscRightParallelObj2Y m2 : 35|11@1+ (2,-2048) [-2048|2044] "cm" Vector__XXX
 SG_ PARK_pscRightParallelObj2X m2 : 46|11@1+ (2,-2048) [-2048|2044] "cm" Vector__XXX
 SG_ PARK_pscRightParallelObj2Alpha m2 : 57|7@1+ (2,-128) [-128|124] "deg" Vector__XXX
 SG_ PARK_pscRightCrossObj1X m3 : 3|11@1+ (2,-2048) [-2048|2044] "cm" Vector__XXX
 SG_ PARK_pscRightCrossObj1Y m3 : 14|11@1+ (2,-2048) [-2048|2044] "cm" Vector__XXX
 SG_ PARK_pscRightCrossObj1Alpha m3 : 25|7@1+ (2,-128) [-128|124] "deg" Vector__XXX
 SG_ PARK_pscRightCrossObj2Y m3 : 35|11@1+ (2,-2048) [-2048|2044] "cm" Vector__XXX
 SG_ PARK_pscRightCrossObj2X m3 : 46|11@1+ (2,-2048) [-2048|2044] "cm" Vector__XXX
 SG_ PARK_pscRightCrossObj2Alpha m3 : 57|7@1+ (2,-128) [-128|124] "deg" Vector__XXX

BO_TX_BU_ 981 : ESP;
BO_TX_BU_ 805 : ESP;
BO_TX_BU_ 861 : IBST;
BO_TX_BU_ 813 : IBST;
BO_TX_BU_ 1486 : PARK;
BO_TX_BU_ 806 : PARK;
BO_TX_BU_ 846 : PARK;
BO_TX_BU_ 862 : PARK;
BO_TX_BU_ 926 : PARK;
BO_TX_BU_ 606 : PARK;
CM_ BO_ 981 "Electronic stability control message: alert matrix";
CM_ SG_ 981 ESP_matrixIndex "Electronic stability control: matrix index";
CM_ SG_ 981 ESP_a001_ecuGenericFault "Electronic stability control: a001 ecu generic fault";
CM_ SG_ 981 ESP_a002_valvesGenericFault "Electronic stability control: a002 valves generic fault";
CM_ SG_ 981 ESP_a003_outletValvesFault "Electronic stability control: a003 outlet valves fault";
CM_ SG_ 981 ESP_a004_inletValvesFault "Electronic stability control: a004 inlet valves fault";
CM_ SG_ 981 ESP_a005_HSVValvesFault "Electronic stability control: a005 HSV valves fault";
CM_ SG_ 981 ESP_a006_USVValvesFault "Electronic stability control: a006 USV valves fault";
CM_ SG_ 981 ESP_a007_pumpMotorFault "Electronic stability control: a007 pump motor fault";
CM_ SG_ 981 ESP_a008_pumpMotor12VsupplyLow "Electronic stability control: a008 pump motor12 vsupply low";
CM_ SG_ 981 ESP_a009_12VHardUndervoltage "Electronic stability control: a009 12 v hard undervoltage";
CM_ SG_ 981 ESP_a010_12VUndervoltage "Electronic stability control: a010 12 v undervoltage";
CM_ SG_ 981 ESP_a011_12VSystemUndervoltage "Electronic stability control: a011 12 v system undervoltage";
CM_ SG_ 981 ESP_a012_netUndervoltage "Electronic stability control: a012 net undervoltage";
CM_ SG_ 981 ESP_a013_valveRelayUndervoltage "Electronic stability control: a013 valve relay undervoltage";
CM_ SG_ 981 ESP_a014_WSSSupplyUndervoltage "Electronic stability control: a014 WSS supply undervoltage";
CM_ SG_ 981 ESP_a015_12VSupplyOvervoltage "Electronic stability control: a015 12 v supply overvoltage";
CM_ SG_ 981 ESP_a016_12VSystemOvervoltage "Electronic stability control: a016 12 v system overvoltage";
CM_ SG_ 981 ESP_a017_netOvervoltage "Electronic stability control: a017 net overvoltage";
CM_ SG_ 981 ESP_a018_WSSSignFrontAxle "Electronic stability control: a018 WSS sign front axle";
CM_ SG_ 981 ESP_a019_WSSSignRearAxle "Electronic stability control: a019 WSS sign rear axle";
CM_ SG_ 981 ESP_a020_WSSGenericTempFault "Electronic stability control: a020 WSS generic temp fault";
CM_ SG_ 981 ESP_a021_WSSGeneralVDiffFault "Electronic stability control: a021 WSS general v diff fault";
CM_ SG_ 981 ESP_a022_WSSDirectionFault "Electronic stability control: a022 WSS direction fault";
CM_ SG_ 981 ESP_a023_WSSSeveralSuspected "Electronic stability control: a023 WSS several suspected";
CM_ SG_ 981 ESP_a024_WSSReverseCurrent "Electronic stability control: a024 WSS reverse current";
CM_ SG_ 981 ESP_a025_FrLWSSOpenOrShortToGnd "Electronic stability control: a025 fr LWSS open or short to gnd";
CM_ SG_ 981 ESP_a026_FrLWSSShortTo12V "Electronic stability control: a026 fr LWSS short to12 v";
CM_ SG_ 981 ESP_a027_FrLWSSLineInterruption "Electronic stability control: a027 fr LWSS line interruption";
CM_ SG_ 981 ESP_a028_FrLWSSMaxSpeedExceeded "Electronic stability control: a028 fr LWSS max speed exceeded";
CM_ SG_ 981 ESP_a029_FrLWSSTooManyPulses "Electronic stability control: a029 fr LWSS too many pulses";
CM_ SG_ 981 ESP_a030_FrLWSSLostSignal "Electronic stability control: a030 fr LWSS lost signal";
CM_ SG_ 981 ESP_a031_FrLWSSNoPulsesDetected "Electronic stability control: a031 fr LWSS no pulses detected";
CM_ SG_ 981 ESP_a032_FrLWSSWrongSensorType "Electronic stability control: a032 fr LWSS wrong sensor type";
CM_ SG_ 981 ESP_a033_FrLWSSSignalNoise "Electronic stability control: a033 fr LWSS signal noise";
CM_ SG_ 981 ESP_a034_FrLWSSVDiffFault "Electronic stability control: a034 fr LWSSV diff fault";
CM_ SG_ 981 ESP_a035_FrLWSSDirectionFault "Electronic stability control: a035 fr LWSS direction fault";
CM_ SG_ 981 ESP_a036_FrLWSSLargeAirGap "Electronic stability control: a036 fr LWSS large air gap";
CM_ SG_ 981 ESP_a037_FrLWSSSupplyShortToGnd "Electronic stability control: a037 fr LWSS supply short to gnd";
CM_ SG_ 981 ESP_a038_FrLWSSGeneralFault "Electronic stability control: a038 fr LWSS general fault";
CM_ SG_ 981 ESP_a039_FrRWSSOpenOrShortToGnd "Electronic stability control: a039 fr RWSS open or short to gnd";
CM_ SG_ 981 ESP_a040_FrRWSSShortTo12V "Electronic stability control: a040 fr RWSS short to12 v";
CM_ SG_ 981 ESP_a041_FrRWSSLineInterruption "Electronic stability control: a041 fr RWSS line interruption";
CM_ SG_ 981 ESP_a042_FrRWSSMaxSpeedExceeded "Electronic stability control: a042 fr RWSS max speed exceeded";
CM_ SG_ 981 ESP_a043_FrRWSSTooManyPulses "Electronic stability control: a043 fr RWSS too many pulses";
CM_ SG_ 981 ESP_a044_FrRWSSLostSignal "Electronic stability control: a044 fr RWSS lost signal";
CM_ SG_ 981 ESP_a045_FrRWSSNoPulsesDetected "Electronic stability control: a045 fr RWSS no pulses detected";
CM_ SG_ 981 ESP_a046_FrRWSSWrongSensorType "Electronic stability control: a046 fr RWSS wrong sensor type";
CM_ SG_ 981 ESP_a047_FrRWSSSignalNoise "Electronic stability control: a047 fr RWSS signal noise";
CM_ SG_ 981 ESP_a048_FrRWSSVDiffFault "Electronic stability control: a048 fr RWSSV diff fault";
CM_ SG_ 981 ESP_a049_FrRWSSDirectionFault "Electronic stability control: a049 fr RWSS direction fault";
CM_ SG_ 981 ESP_a050_FrRWSSLargeAirGap "Electronic stability control: a050 fr RWSS large air gap";
CM_ SG_ 981 ESP_a051_FrRWSSSupplyShortToGnd "Electronic stability control: a051 fr RWSS supply short to gnd";
CM_ SG_ 981 ESP_a052_FrRWSSGeneralFault "Electronic stability control: a052 fr RWSS general fault";
CM_ SG_ 981 ESP_a053_ReLWSSOpenOrShortToGnd "Electronic stability control: a053 re LWSS open or short to gnd";
CM_ SG_ 981 ESP_a054_ReLWSSShortTo12V "Electronic stability control: a054 re LWSS short to12 v";
CM_ SG_ 981 ESP_a055_ReLWSSLineInterruption "Electronic stability control: a055 re LWSS line interruption";
CM_ SG_ 981 ESP_a056_ReLWSSMaxSpeedExceeded "Electronic stability control: a056 re LWSS max speed exceeded";
CM_ SG_ 981 ESP_a057_ReLWSSTooManyPulses "Electronic stability control: a057 re LWSS too many pulses";
CM_ SG_ 981 ESP_a058_ReLWSSLostSignal "Electronic stability control: a058 re LWSS lost signal";
CM_ SG_ 981 ESP_a059_ReLWSSNoPulsesDetected "Electronic stability control: a059 re LWSS no pulses detected";
CM_ SG_ 981 ESP_a060_ReLWSSWrongSensorType "Electronic stability control: a060 re LWSS wrong sensor type";
CM_ SG_ 981 ESP_a061_ReLWSSSignalNoise "Electronic stability control: a061 re LWSS signal noise";
CM_ SG_ 981 ESP_a062_ReLWSSVDiffFault "Electronic stability control: a062 re LWSSV diff fault";
CM_ SG_ 981 ESP_a063_ReLWSSDirectionFault "Electronic stability control: a063 re LWSS direction fault";
CM_ SG_ 981 ESP_a064_ReLWSSLargeAirGap "Electronic stability control: a064 re LWSS large air gap";
CM_ SG_ 981 ESP_a065_ReLWSSSupplyShortToGnd "Electronic stability control: a065 re LWSS supply short to gnd";
CM_ SG_ 981 ESP_a066_ReLWSSGeneralFault "Electronic stability control: a066 re LWSS general fault";
CM_ SG_ 981 ESP_a067_ReRWSSOpenOrShortToGnd "Electronic stability control: a067 re RWSS open or short to gnd";
CM_ SG_ 981 ESP_a068_ReRWSSShortTo12V "Electronic stability control: a068 re RWSS short to12 v";
CM_ SG_ 981 ESP_a069_ReRWSSLineInterruption "Electronic stability control: a069 re RWSS line interruption";
CM_ SG_ 981 ESP_a070_ReRWSSMaxSpeedExceeded "Electronic stability control: a070 re RWSS max speed exceeded";
CM_ SG_ 981 ESP_a071_ReRWSSTooManyPulses "Electronic stability control: a071 re RWSS too many pulses";
CM_ SG_ 981 ESP_a072_ReRWSSLostSignal "Electronic stability control: a072 re RWSS lost signal";
CM_ SG_ 981 ESP_a073_ReRWSSNoPulsesDetected "Electronic stability control: a073 re RWSS no pulses detected";
CM_ SG_ 981 ESP_a074_ReRWSSWrongSensorType "Electronic stability control: a074 re RWSS wrong sensor type";
CM_ SG_ 981 ESP_a075_ReRWSSSignalNoise "Electronic stability control: a075 re RWSS signal noise";
CM_ SG_ 981 ESP_a076_ReRWSSVDiffFault "Electronic stability control: a076 re RWSSV diff fault";
CM_ SG_ 981 ESP_a077_ReRWSSDirectionFault "Electronic stability control: a077 re RWSS direction fault";
CM_ SG_ 981 ESP_a078_ReRWSSLargeAirGap "Electronic stability control: a078 re RWSS large air gap";
CM_ SG_ 981 ESP_a079_ReRWSSSupplyShortToGnd "Electronic stability control: a079 re RWSS supply short to gnd";
CM_ SG_ 981 ESP_a080_ReRWSSGeneralFault "Electronic stability control: a080 re RWSS general fault";
CM_ SG_ 981 ESP_a081_PressureSensorShort "Electronic stability control: a081 pressure sensor short";
CM_ SG_ 981 ESP_a082_PMCSensorOffsetHigh "Electronic stability control: a082 PMC sensor offset high";
CM_ SG_ 981 ESP_a083_PMCSensorFault "Electronic stability control: a083 PMC sensor fault";
CM_ SG_ 981 ESP_a084_BrakeFluidReservoirLow "Electronic stability control: a084 brake fluid reservoir low";
CM_ SG_ 981 ESP_a085_BrakeSwitchStuckHigh "Electronic stability control: a085 brake switch stuck high";
CM_ SG_ 981 ESP_a086_BrakeSwitchImplausible1 "Electronic stability control: a086 brake switch implausible1";
CM_ SG_ 981 ESP_a087_BrakeSwitchImplausible3 "Electronic stability control: a087 brake switch implausible3";
CM_ SG_ 981 ESP_a088_absContinuousControl "Electronic stability control: a088 abs continuous control";
CM_ SG_ 981 ESP_a089_absNoPressureIncrease "Electronic stability control: a089 abs no pressure increase";
CM_ SG_ 981 ESP_a090_vdcContinuousControl "Electronic stability control: a090 vdc continuous control";
CM_ SG_ 981 ESP_a091_CANUndervoltage "Electronic stability control: a091 CAN undervoltage";
CM_ SG_ 981 ESP_a092_CANOvervoltage "Electronic stability control: a092 CAN overvoltage";
CM_ SG_ 981 ESP_a093_partyBusOff "Electronic stability control: a093 party bus off";
CM_ SG_ 981 ESP_a094_partyBusPassive "Electronic stability control: a094 party bus passive";
CM_ SG_ 981 ESP_a095_chassisBusOff "Electronic stability control: a095 chassis bus off";
CM_ SG_ 981 ESP_a096_chassisBusPassive "Electronic stability control: a096 chassis bus passive";
CM_ SG_ 981 ESP_a097_tcsRefSpeedNotInit "Electronic stability control: a097 tcs ref speed not init";
CM_ SG_ 981 ESP_a098_vdcRefSpeedNotInit "Electronic stability control: a098 vdc ref speed not init";
CM_ SG_ 981 ESP_a099_brakeTempModelOverheat "Electronic stability control: a099 brake temp model overheat";
CM_ SG_ 981 ESP_a100_brakeTempModelDisabled "Electronic stability control: a100 brake temp model disabled";
CM_ SG_ 981 ESP_a101_ebdFault "Electronic stability control: a101 ebd fault";
CM_ SG_ 981 ESP_a102_absFault "Electronic stability control: a102 abs fault";
CM_ SG_ 981 ESP_a103_stabilityControlFault "Electronic stability control: a103 stability control fault";
CM_ SG_ 981 ESP_a104_hbcEnabled "Electronic stability control: a104 hbc enabled";
CM_ SG_ 981 ESP_a105_ebrFault "Electronic stability control: a105 ebr fault";
CM_ SG_ 981 ESP_a106_vdcActuatorFault "Electronic stability control: a106 vdc actuator fault";
CM_ SG_ 981 ESP_a107_reserved107 "Electronic stability control: a107 reserved107";
CM_ SG_ 981 ESP_a108_reserved108 "Electronic stability control: a108 reserved108";
CM_ SG_ 981 ESP_a109_reserved109 "Electronic stability control: a109 reserved109";
CM_ SG_ 981 ESP_a110_rollerBenchActive "Electronic stability control: a110 roller bench active";
CM_ SG_ 981 ESP_a111_absActive "Electronic stability control: a111 abs active";
CM_ SG_ 981 ESP_a112_espActive "Electronic stability control: a112 esp active";
CM_ SG_ 981 ESP_a113_btcActive "Electronic stability control: a113 btc active";
CM_ SG_ 981 ESP_a114_tvdcActive "Electronic stability control: a114 tvdc active";
CM_ SG_ 981 ESP_a115_ebdActive "Electronic stability control: a115 ebd active";
CM_ SG_ 981 ESP_a116_tsmActive "Electronic stability control: a116 tsm active";
CM_ SG_ 981 ESP_a117_hbaActive "Electronic stability control: a117 hba active";
CM_ SG_ 981 ESP_a118_hfcActive "Electronic stability control: a118 hfc active";
CM_ SG_ 981 ESP_a119_hbbActive "Electronic stability control: a119 hbb active";
CM_ SG_ 981 ESP_a120_rmiActive "Electronic stability control: a120 rmi active";
CM_ SG_ 981 ESP_a121_regenTcActive "Electronic stability control: a121 regen tc active";
CM_ SG_ 981 ESP_a122_bdwActive "Electronic stability control: a122 bdw active";
CM_ SG_ 981 ESP_a123_ebrActive "Electronic stability control: a123 ebr active";
CM_ SG_ 981 ESP_a124_ebrSkidActive "Electronic stability control: a124 ebr skid active";
CM_ SG_ 981 ESP_a125_reserved125 "Electronic stability control: a125 reserved125";
CM_ SG_ 981 ESP_a126_reserved126 "Electronic stability control: a126 reserved126";
CM_ SG_ 981 ESP_a127_reserved127 "Electronic stability control: a127 reserved127";
CM_ SG_ 981 ESP_a128_reserved128 "Electronic stability control: a128 reserved128";
CM_ SG_ 981 ESP_a129_reserved129 "Electronic stability control: a129 reserved129";
CM_ SG_ 981 ESP_a130_EPAS3PsysStatusTimeout "Electronic stability control: a130 EPAS3 psys status timeout";
CM_ SG_ 981 ESP_a131_EPAS3PsysStatusDLC "Electronic stability control: a131 EPAS3 psys status DLC";
CM_ SG_ 981 ESP_a132_EPAS3PsysStatusChecksum "Electronic stability control: a132 EPAS3 psys status checksum";
CM_ SG_ 981 ESP_a133_EPAS3PsysStatusCounter "Electronic stability control: a133 EPAS3 psys status counter";
CM_ SG_ 981 ESP_a134_steeringAngleInvalid "Electronic stability control: a134 steering angle invalid";
CM_ SG_ 981 ESP_a135_steeringAngleNoCenter "Electronic stability control: a135 steering angle no center";
CM_ SG_ 981 ESP_a136_steeringAngleFrozen "Electronic stability control: a136 steering angle frozen";
CM_ SG_ 981 ESP_a137_steeringOffsetTooLarge "Electronic stability control: a137 steering offset too large";
CM_ SG_ 981 ESP_a138_steeringAngleImplaus "Electronic stability control: a138 steering angle implaus";
CM_ SG_ 981 ESP_a139_steeringAngleWrongSign "Electronic stability control: a139 steering angle wrong sign";
CM_ SG_ 981 ESP_a140_RCMInertial1Timeout "Electronic stability control: a140 RCM inertial1 timeout";
CM_ SG_ 981 ESP_a141_RCMInertial1DLC "Electronic stability control: a141 RCM inertial1 DLC";
CM_ SG_ 981 ESP_a142_RCMInertial1Checksum "Electronic stability control: a142 RCM inertial1 checksum";
CM_ SG_ 981 ESP_a143_RCMInertial1Counter "Electronic stability control: a143 RCM inertial1 counter";
CM_ SG_ 981 ESP_a144_yawMaxLatency "Electronic stability control: a144 yaw max latency";
CM_ SG_ 981 ESP_a145_yawInitFault "Electronic stability control: a145 yaw init fault";
CM_ SG_ 981 ESP_a146_yawInvalidValue "Electronic stability control: a146 yaw invalid value";
CM_ SG_ 981 ESP_a147_yawSensorNotAvailable "Electronic stability control: a147 yaw sensor not available";
CM_ SG_ 981 ESP_a148_yawSignalFault "Electronic stability control: a148 yaw signal fault";
CM_ SG_ 981 ESP_a149_yawInvalidSign "Electronic stability control: a149 yaw invalid sign";
CM_ SG_ 981 ESP_a150_yawImplausible "Electronic stability control: a150 yaw implausible";
CM_ SG_ 981 ESP_a151_RCMInertial2Timeout "Electronic stability control: a151 RCM inertial2 timeout";
CM_ SG_ 981 ESP_a152_RCMInertial2DLC "Electronic stability control: a152 RCM inertial2 DLC";
CM_ SG_ 981 ESP_a153_RCMInertial2Checksum "Electronic stability control: a153 RCM inertial2 checksum";
CM_ SG_ 981 ESP_a154_RCMInertial2Counter "Electronic stability control: a154 RCM inertial2 counter";
CM_ SG_ 981 ESP_a155_ayMaxLatency "Electronic stability control: a155 ay max latency";
CM_ SG_ 981 ESP_a156_ayInitFault "Electronic stability control: a156 ay init fault";
CM_ SG_ 981 ESP_a157_ayInvalidValue "Electronic stability control: a157 ay invalid value";
CM_ SG_ 981 ESP_a158_aySensorNotAvailable "Electronic stability control: a158 ay sensor not available";
CM_ SG_ 981 ESP_a159_aySignalFault "Electronic stability control: a159 ay signal fault";
CM_ SG_ 981 ESP_a160_ayRangeExceeded "Electronic stability control: a160 ay range exceeded";
CM_ SG_ 981 ESP_a161_ayOffsetExceeded "Electronic stability control: a161 ay offset exceeded";
CM_ SG_ 981 ESP_a162_ayImplausible "Electronic stability control: a162 ay implausible";
CM_ SG_ 981 ESP_a163_axMaxLatency "Electronic stability control: a163 ax max latency";
CM_ SG_ 981 ESP_a164_axInitFault "Electronic stability control: a164 ax init fault";
CM_ SG_ 981 ESP_a165_axInvalidValue "Electronic stability control: a165 ax invalid value";
CM_ SG_ 981 ESP_a166_axSensorNotAvailable "Electronic stability control: a166 ax sensor not available";
CM_ SG_ 981 ESP_a167_axSignalFault "Electronic stability control: a167 ax signal fault";
CM_ SG_ 981 ESP_a168_axRangeExceeded "Electronic stability control: a168 ax range exceeded";
CM_ SG_ 981 ESP_a169_axOffsetExceeded "Electronic stability control: a169 ax offset exceeded";
CM_ SG_ 981 ESP_a170_axSignalFrozen "Electronic stability control: a170 ax signal frozen";
CM_ SG_ 981 ESP_a171_axImplausible "Electronic stability control: a171 ax implausible";
CM_ SG_ 981 ESP_a172_IBSTparty1Timeout "Electronic stability control: a172 IBS tparty1 timeout";
CM_ SG_ 981 ESP_a173_IBSTparty1DLC "Electronic stability control: a173 IBS tparty1 DLC";
CM_ SG_ 981 ESP_a174_IBSTparty1Checksum "Electronic stability control: a174 IBS tparty1 checksum";
CM_ SG_ 981 ESP_a175_IBSTparty1Counter "Electronic stability control: a175 IBS tparty1 counter";
CM_ SG_ 981 ESP_a176_IBSTEBRNotAvailable "Electronic stability control: a176 IBSTEBR not available";
CM_ SG_ 981 ESP_a177_IBSTOutputRodDrvInvalid "Electronic stability control: a177 IBST output rod drv invalid";
CM_ SG_ 981 ESP_a178_IBSTOutputRodActInvalid "Electronic stability control: a178 IBST output rod act invalid";
CM_ SG_ 981 ESP_a179_IBSTparty2Timeout "Electronic stability control: a179 IBS tparty2 timeout";
CM_ SG_ 981 ESP_a180_IBSTparty2Checksum "Electronic stability control: a180 IBS tparty2 checksum";
CM_ SG_ 981 ESP_a181_IBSTparty2DLC "Electronic stability control: a181 IBS tparty2 DLC";
CM_ SG_ 981 ESP_a182_IBSTparty2Counter "Electronic stability control: a182 IBS tparty2 counter";
CM_ SG_ 981 ESP_a183_IBSTStatusOff "Electronic stability control: a183 IBST status off";
CM_ SG_ 981 ESP_a184_IBSTpRunoutInvalid "Electronic stability control: a184 IBS tp runout invalid";
CM_ SG_ 981 ESP_a185_IBSTFeedforwardBackup "Electronic stability control: a185 IBST feedforward backup";
CM_ SG_ 981 ESP_a186_IBSTBrakeAppliedInvalid "Electronic stability control: a186 IBST brake applied invalid";
CM_ SG_ 981 ESP_a187_DIbtcRequestTimeout "Electronic stability control: a187 d ibtc request timeout";
CM_ SG_ 981 ESP_a188_DIbtcRequestDLC "Electronic stability control: a188 d ibtc request DLC";
CM_ SG_ 981 ESP_a189_DIbtcRequestChecksum "Electronic stability control: a189 d ibtc request checksum";
CM_ SG_ 981 ESP_a190_DIbtcRequestCounter "Electronic stability control: a190 d ibtc request counter";
CM_ SG_ 981 ESP_a191_DIchassisControlTimeout "Electronic stability control: a191 d ichassis control timeout";
CM_ SG_ 981 ESP_a192_DIchassisControlDLC "Electronic stability control: a192 d ichassis control DLC";
CM_ SG_ 981 ESP_a193_DIchassisControlChecksu "Electronic stability control: a193 d ichassis control checksum";
CM_ SG_ 981 ESP_a194_DIchassisControlCounter "Electronic stability control: a194 d ichassis control counter";
CM_ SG_ 981 ESP_a195_ptcStateInvalid "Electronic stability control: a195 ptc state invalid";
CM_ SG_ 981 ESP_a196_DIsystemStatusTimeout "Electronic stability control: a196 d isystem status timeout";
CM_ SG_ 981 ESP_a197_DIsystemStatusDLC "Electronic stability control: a197 d isystem status DLC";
CM_ SG_ 981 ESP_a198_DIsystemStatusChecksum "Electronic stability control: a198 d isystem status checksum";
CM_ SG_ 981 ESP_a199_DIsystemStatusCounter "Electronic stability control: a199 d isystem status counter";
CM_ SG_ 981 ESP_a200_reverseGearStuckHigh "Electronic stability control: a200 reverse gear stuck high";
CM_ SG_ 981 ESP_a201_reverseGearStuckLow "Electronic stability control: a201 reverse gear stuck low";
CM_ SG_ 981 ESP_a202_accelPedalInvalid "Electronic stability control: a202 accel pedal invalid";
CM_ SG_ 981 ESP_a203_DItorqueTimeout "Electronic stability control: a203 d itorque timeout";
CM_ SG_ 981 ESP_a204_DItorqueDLC "Electronic stability control: a204 d itorque DLC";
CM_ SG_ 981 ESP_a205_DItorqueChecksum "Electronic stability control: a205 d itorque checksum";
CM_ SG_ 981 ESP_a206_DItorqueCounter "Electronic stability control: a206 d itorque counter";
CM_ SG_ 981 ESP_a207_DITorqueCommandInvalid "Electronic stability control: a207 DI torque command invalid";
CM_ SG_ 981 ESP_a208_DIRPMInvalid "Electronic stability control: a208 DIRPM invalid";
CM_ SG_ 981 ESP_a209_DITorqueActualInvalid "Electronic stability control: a209 DI torque actual invalid";
CM_ SG_ 981 ESP_a210_DIStorqueTimeout "Electronic stability control: a210 DI storque timeout";
CM_ SG_ 981 ESP_a211_DIStorqueDLC "Electronic stability control: a211 DI storque DLC";
CM_ SG_ 981 ESP_a212_DIStorqueChecksum "Electronic stability control: a212 DI storque checksum";
CM_ SG_ 981 ESP_a213_DIStorqueCounter "Electronic stability control: a213 DI storque counter";
CM_ SG_ 981 ESP_a214_DISTorqueCommandInvalid "Electronic stability control: a214 DIS torque command invalid";
CM_ SG_ 981 ESP_a215_DISRPMInvalid "Electronic stability control: a215 DISRPM invalid";
CM_ SG_ 981 ESP_a216_DISTorqueActualInvalid "Electronic stability control: a216 DIS torque actual invalid";
CM_ SG_ 981 ESP_a217_DIvdcLeftTimeout "Electronic stability control: a217 d ivdc left timeout";
CM_ SG_ 981 ESP_a218_DIvdcLeftDLC "Electronic stability control: a218 d ivdc left DLC";
CM_ SG_ 981 ESP_a219_DIvdcLeftChecksum "Electronic stability control: a219 d ivdc left checksum";
CM_ SG_ 981 ESP_a220_DIvdcLeftCounter "Electronic stability control: a220 d ivdc left counter";
CM_ SG_ 981 ESP_a221_DIvdcRightTimeout "Electronic stability control: a221 d ivdc right timeout";
CM_ SG_ 981 ESP_a222_DIvdcRightDLC "Electronic stability control: a222 d ivdc right DLC";
CM_ SG_ 981 ESP_a223_DIvdcRightChecksum "Electronic stability control: a223 d ivdc right checksum";
CM_ SG_ 981 ESP_a224_DIvdcRightCounter "Electronic stability control: a224 d ivdc right counter";
CM_ SG_ 981 ESP_a225_configMismatch "Electronic stability control: a225 config mismatch";
CM_ SG_ 981 ESP_a226_bdwRequestInvalid "Electronic stability control: a226 bdw request invalid";
CM_ SG_ 981 ESP_a227_bdwRequestActiveInvalid "Electronic stability control: a227 bdw request active invalid";
CM_ SG_ 981 ESP_a228_GTWvinTimeout "Electronic stability control: a228 GT wvin timeout";
CM_ SG_ 981 ESP_a229_GTWvinDLC "Electronic stability control: a229 GT wvin DLC";
CM_ SG_ 981 ESP_a230_vinNotLearned "Electronic stability control: a230 vin not learned";
CM_ SG_ 981 ESP_a231_storedVINMismatch "Electronic stability control: a231 stored VIN mismatch";
CM_ SG_ 981 ESP_a232_PMstate2Timeout "Electronic stability control: a232 p mstate2 timeout";
CM_ SG_ 981 ESP_a233_PMstate2Checksum "Electronic stability control: a233 p mstate2 checksum";
CM_ SG_ 981 ESP_a234_PMstate2DLC "Electronic stability control: a234 p mstate2 DLC";
CM_ SG_ 981 ESP_a235_PMstate2Counter "Electronic stability control: a235 p mstate2 counter";
CM_ SG_ 981 ESP_a236_ebrCommandStateInvalid "Electronic stability control: a236 ebr command state invalid";
CM_ SG_ 981 ESP_a237_vdcCommandStateInvalid "Electronic stability control: a237 vdc command state invalid";
CM_ SG_ 981 ESP_a238_UIodoTimeout "Electronic stability control: a238 u iodo timeout";
CM_ SG_ 981 ESP_a239_UIodoDLC "Electronic stability control: a239 u iodo DLC";
CM_ SG_ 981 ESP_a240_LVPowerStateTimeout "Electronic stability control: a240 LV power state timeout";
CM_ SG_ 981 ESP_a241_LVPowerStateChecksum "Electronic stability control: a241 LV power state checksum";
CM_ SG_ 981 ESP_a242_LVPowerStateDLC "Electronic stability control: a242 LV power state DLC";
CM_ SG_ 981 ESP_a243_LVPowerStateCounter "Electronic stability control: a243 LV power state counter";
CM_ SG_ 981 ESP_a244_LVOffStateInvalid "Electronic stability control: a244 LV off state invalid";
CM_ SG_ 981 ESP_a245_LVGoingDownStateInvalid "Electronic stability control: a245 LV going down state invalid";
CM_ SG_ 981 ESP_a246_VCFRONTsensorTimeout "Electronic stability control: a246 VCFRON tsensor timeout";
CM_ SG_ 981 ESP_a247_VCFRONTsensorDLC "Electronic stability control: a247 VCFRON tsensor DLC";
CM_ SG_ 981 ESP_a248_vdcBrkeTrqTarFrLInvalid "Electronic stability control: a248 vdc brke trq tar fr l invalid";
CM_ SG_ 981 ESP_a249_vdcBrkeTrqTarFrRInvalid "Electronic stability control: a249 vdc brke trq tar fr r invalid";
CM_ SG_ 981 ESP_a250_vdcBrkeTrqTarReLInvalid "Electronic stability control: a250 vdc brke trq tar re l invalid";
CM_ SG_ 981 ESP_a251_vdcBrkeTrqTarReRInvalid "Electronic stability control: a251 vdc brke trq tar re r invalid";
CM_ SG_ 981 ESP_a252_vdcWhlSlipLimFrLInvalid "Electronic stability control: a252 vdc whl slip lim fr l invalid";
CM_ SG_ 981 ESP_a253_vdcWhlSlipLimFrRInvalid "Electronic stability control: a253 vdc whl slip lim fr r invalid";
CM_ SG_ 981 ESP_a254_vdcWhlSlipLimReLInvalid "Electronic stability control: a254 vdc whl slip lim re l invalid";
CM_ SG_ 981 ESP_a255_vdcWhlSlipLimReRInvalid "Electronic stability control: a255 vdc whl slip lim re r invalid";
CM_ SG_ 981 ESP_a256_epbmStatusTimeout "Electronic stability control: a256 epbm status timeout";
CM_ SG_ 981 ESP_a257_epbmStatusChecksum "Electronic stability control: a257 epbm status checksum";
CM_ SG_ 981 ESP_a258_epbmStatusDLC "Electronic stability control: a258 epbm status DLC";
CM_ SG_ 981 ESP_a259_epbmStatusCounter "Electronic stability control: a259 epbm status counter";
CM_ SG_ 981 ESP_a260_epblStatusTimeout "Electronic stability control: a260 epbl status timeout";
CM_ SG_ 981 ESP_a261_epblStatusChecksum "Electronic stability control: a261 epbl status checksum";
CM_ SG_ 981 ESP_a262_epblStatusDLC "Electronic stability control: a262 epbl status DLC";
CM_ SG_ 981 ESP_a263_epblStatusCounter "Electronic stability control: a263 epbl status counter";
CM_ SG_ 981 ESP_a264_pumpSpeedLimitInvalid "Electronic stability control: a264 pump speed limit invalid";
CM_ SG_ 981 ESP_a265_DIRELtorqueTimeout "Electronic stability control: a265 DIRE ltorque timeout";
CM_ SG_ 981 ESP_a266_DIRELtorqueDLC "Electronic stability control: a266 DIRE ltorque DLC";
CM_ SG_ 981 ESP_a267_DIRELtorqueChecksum "Electronic stability control: a267 DIRE ltorque checksum";
CM_ SG_ 981 ESP_a268_DIRELtorqueCounter "Electronic stability control: a268 DIRE ltorque counter";
CM_ SG_ 981 ESP_a269_DIRELTorqueCommandInval "Electronic stability control: a269 DIREL torque command invalid";
CM_ SG_ 981 ESP_a270_DIRELRPMInvalid "Electronic stability control: a270 DIRELRPM invalid";
CM_ SG_ 981 ESP_a271_DIRELTorqueActualInvali "Electronic stability control: a271 DIREL torque actual invalid";
CM_ SG_ 981 ESP_a272_DIRERtorqueTimeout "Electronic stability control: a272 DIRE rtorque timeout";
CM_ SG_ 981 ESP_a273_DIRERtorqueDLC "Electronic stability control: a273 DIRE rtorque DLC";
CM_ SG_ 981 ESP_a274_DIRERtorqueChecksum "Electronic stability control: a274 DIRE rtorque checksum";
CM_ SG_ 981 ESP_a275_DIRERtorqueCounter "Electronic stability control: a275 DIRE rtorque counter";
CM_ SG_ 981 ESP_a276_DIRERTorqueCommandInval "Electronic stability control: a276 DIRER torque command invalid";
CM_ SG_ 981 ESP_a277_DIRERRPMInvalid "Electronic stability control: a277 DIRERRPM invalid";
CM_ SG_ 981 ESP_a278_DIRERTorqueActualInvali "Electronic stability control: a278 DIRER torque actual invalid";
CM_ SG_ 981 ESP_a279_lifetimeManagementOverr "Electronic stability control: a279 lifetime management overrun";
CM_ SG_ 981 ESP_a280_trackModeABSEnabled "Electronic stability control: a280 track mode ABS enabled";
CM_ SG_ 981 ESP_a281_trackModeABSdisabled "Electronic stability control: a281 track mode AB sdisabled";
CM_ SG_ 981 ESP_a282_trackModeABSRequestInva "Electronic stability control: a282 track mode ABS request invalid";
CM_ SG_ 981 ESP_a283_secondaryCollisionMitig "Electronic stability control: a283 secondary collision mitigation active";
CM_ SG_ 981 ESP_a284_scmRequestInvalidChecks "Electronic stability control: a284 scm request invalid checksum";
CM_ SG_ 981 ESP_a285_scmRequestDLC "Electronic stability control: a285 scm request DLC";
CM_ SG_ 981 ESP_a286_hydroplaneDetected "Electronic stability control: a286 hydroplane detected";
CM_ SG_ 981 ESP_a287_failedBrakeCircuitDetec "Electronic stability control: a287 failed brake circuit detected";
CM_ SG_ 981 ESP_a288_leftBusOff "Electronic stability control: a288 left bus off";
CM_ SG_ 981 ESP_a289_leftBusPassive "Electronic stability control: a289 left bus passive";
CM_ SG_ 981 ESP_a290_brakeBusOff "Electronic stability control: a290 brake bus off";
CM_ SG_ 981 ESP_a291_brakeBusPassive "Electronic stability control: a291 brake bus passive";
CM_ SG_ 981 ESP_a292_PEPSstatusTimeout "Electronic stability control: a292 PEP sstatus timeout";
CM_ SG_ 981 ESP_a293_PEPSstatusDLC "Electronic stability control: a293 PEP sstatus DLC";
CM_ SG_ 981 ESP_a294_PEPSstatusChecksum "Electronic stability control: a294 PEP sstatus checksum";
CM_ SG_ 981 ESP_a295_PEPSstatusCounter "Electronic stability control: a295 PEP sstatus counter";
CM_ SG_ 981 ESP_a296_roadWheelAngleHealthDeg "Electronic stability control: a296 road wheel angle health degraded";
CM_ SG_ 981 ESP_a297_roadWheelAngleHealthFau "Electronic stability control: a297 road wheel angle health faulted";
CM_ SG_ 981 ESP_a298_RSArearSteerStatusTimeo "Electronic stability control: a298 RS arear steer status timeout";
CM_ SG_ 981 ESP_a299_RSArearSteerStatusDLC "Electronic stability control: a299 RS arear steer status DLC";
CM_ SG_ 981 ESP_a300_RSArearSteerStatusCheck "Electronic stability control: a300 RS arear steer status checksum";
CM_ SG_ 981 ESP_a301_PEPSstatusCounter "Electronic stability control: a301 PEP sstatus counter";
CM_ SG_ 981 ESP_a302_rearRoadWheelAngleHealt "Electronic stability control: a302 rear road wheel angle health degraded";
CM_ SG_ 981 ESP_a303_rearRoadWheelAngleHealt "Electronic stability control: a303 rear road wheel angle health faulted";
CM_ SG_ 981 ESP_a304_rearVCLVPowerStateTimeo "Electronic stability control: a304 rear VCLV power state timeout";
CM_ SG_ 981 ESP_a305_rearVCLVPowerStateDLC "Electronic stability control: a305 rear VCLV power state DLC";
CM_ SG_ 981 ESP_a306_rearVCLVPowerStateCheck "Electronic stability control: a306 rear VCLV power state checksum";
CM_ SG_ 981 ESP_a307_rearVCLVPowerStateCount "Electronic stability control: a307 rear VCLV power state counter";
CM_ SG_ 981 ESP_a308_evacFillNotComplete "Electronic stability control: a308 evac fill not complete";
CM_ SG_ 981 ESP_a309_factoryModeActive "Electronic stability control: a309 factory mode active";
CM_ SG_ 981 ESP_a310_brakeLatencyReductionAc "Electronic stability control: a310 brake latency reduction active";
CM_ SG_ 981 ESP_a311_aesActive "Electronic stability control: a311 aes active";
CM_ SG_ 981 ESP_a312_undefinedAlertDetected "Electronic stability control: a312 undefined alert detected";
CM_ SG_ 981 ESP_a313_cdpRequestStateInvalid "Electronic stability control: a313 cdp request state invalid";
CM_ SG_ 981 ESP_a314_aesFault "Electronic stability control: a314 aes fault";
CM_ SG_ 981 ESP_a315_EMCBackup11Timeout "Electronic stability control: a315 EMC backup11 timeout";
CM_ SG_ 981 ESP_a316_EMCBackup11DLC "Electronic stability control: a316 EMC backup11 DLC";
CM_ SG_ 981 ESP_a317_EMCBackup11Checksum "Electronic stability control: a317 EMC backup11 checksum";
CM_ SG_ 981 ESP_a318_EMCBackup11Counter "Electronic stability control: a318 EMC backup11 counter";
CM_ SG_ 981 ESP_a319_AES_BackupActuatorActiv "Electronic stability control: a319 AES backup actuator active";
CM_ SG_ 981 ESP_a320_DPB_actuator1Counter "Electronic stability control: a320 DPB actuator1 counter";
CM_ SG_ 981 ESP_a321_DPB_actuator1Checksum "Electronic stability control: a321 DPB actuator1 checksum";
CM_ SG_ 981 ESP_a322_DPB_actuator1DLC "Electronic stability control: a322 DPB actuator1 DLC";
CM_ SG_ 981 ESP_a323_DPB_actuator1Timeout "Electronic stability control: a323 DPB actuator1 timeout";
CM_ SG_ 981 ESP_a324_DPB_actuator2Counter "Electronic stability control: a324 DPB actuator2 counter";
CM_ SG_ 981 ESP_a325_DPB_actuator2Checksum "Electronic stability control: a325 DPB actuator2 checksum";
CM_ SG_ 981 ESP_a326_DPB_actuator2DLC "Electronic stability control: a326 DPB actuator2 DLC";
CM_ SG_ 981 ESP_a327_DPB_actuator2Timeout "Electronic stability control: a327 DPB actuator2 timeout";
CM_ SG_ 981 ESP_a328_DPB_actuator3Counter "Electronic stability control: a328 DPB actuator3 counter";
CM_ SG_ 981 ESP_a329_DPB_actuator3Checksum "Electronic stability control: a329 DPB actuator3 checksum";
CM_ SG_ 981 ESP_a330_DPB_actuator3DLC "Electronic stability control: a330 DPB actuator3 DLC";
CM_ SG_ 981 ESP_a331_DPB_actuator3Timeout "Electronic stability control: a331 DPB actuator3 timeout";
CM_ SG_ 981 ESP_a332_PressureSensorValHigh "Electronic stability control: a332 pressure sensor val high";
CM_ SG_ 981 ESP_a333_ActCircuitNoPressure "Electronic stability control: a333 act circuit no pressure";
CM_ SG_ 981 ESP_a334_BrakePedalAppliedInvali "Electronic stability control: a334 brake pedal applied invalid";
CM_ SG_ 981 ESP_a335_LdmFxTarBrakeActInvalid "Electronic stability control: a335 ldm fx tar brake act invalid";
CM_ SG_ 981 ESP_a336_FxTargetDriverInvalid "Electronic stability control: a336 fx target driver invalid";
CM_ SG_ 981 ESP_a337_pReductionPotentialInva "Electronic stability control: a337 p reduction potential invalid";
CM_ SG_ 981 ESP_a338_pRunoutInvalid "Electronic stability control: a338 p runout invalid";
CM_ SG_ 981 ESP_a339_sInputRodInvalid "Electronic stability control: a339 s input rod invalid";
CM_ SG_ 981 ESP_a340_RollerBenchMisuse "Electronic stability control: a340 roller bench misuse";
CM_ SG_ 981 ESP_a341_EnhancedPressureBuildAc "Electronic stability control: a341 enhanced pressure build active";
CM_ SG_ 981 ESP_a342_EnhancedPressureBuildNo "Electronic stability control: a342 enhanced pressure build not active";
CM_ SG_ 981 ESP_a343_EnhancedPressureBuildLt "Electronic stability control: a343 enhanced pressure build ltm reached";
CM_ SG_ 981 ESP_a344_DIbrakeCommandCounter "Electronic stability control: a344 d ibrake command counter";
CM_ SG_ 981 ESP_a345_DIbrakeCommandChecksum "Electronic stability control: a345 d ibrake command checksum";
CM_ SG_ 981 ESP_a346_DIbrakeCommandDLC "Electronic stability control: a346 d ibrake command DLC";
CM_ SG_ 981 ESP_a347_DIbrakeCommandTimeout "Electronic stability control: a347 d ibrake command timeout";
CM_ SG_ 981 ESP_a348_brakeCmdStateInvalid "Electronic stability control: a348 brake cmd state invalid";
CM_ SG_ 981 ESP_a349_ForceLampToRed "Electronic stability control: a349 force lamp to red";
CM_ SG_ 981 ESP_a350_ActuatorOff "Electronic stability control: a350 actuator off";
CM_ SG_ 981 ESP_a351_ActuatorYellowLampReque "Electronic stability control: a351 actuator yellow lamp requested";
CM_ SG_ 981 ESP_a352_ActuatorLDMFailure "Electronic stability control: a352 actuator LDM failure";
CM_ SG_ 981 ESP_a353_PressureSensorImplausHi "Electronic stability control: a353 pressure sensor implaus high";
CM_ SG_ 981 ESP_a354_HBCRequestInvalid "Electronic stability control: a354 HBC request invalid";
CM_ SG_ 981 ESP_a355_RecuStatusActInvalid "Electronic stability control: a355 recu status act invalid";
CM_ SG_ 981 ESP_a356_DIFAxleTorqueInvalid "Electronic stability control: a356 DIF axle torque invalid";
CM_ SG_ 981 ESP_a357_DIRAxleTorqueInvalid "Electronic stability control: a357 DIR axle torque invalid";
CM_ SG_ 981 ESP_a358_externalActuatorFallbac "Electronic stability control: a358 external actuator fallback";
CM_ SG_ 981 ESP_a359_externalActuatorNoExtRe "Electronic stability control: a359 external actuator no ext req";
CM_ SG_ 981 ESP_a360_BBbrakeActuationTimeout "Electronic stability control: a360 b bbrake actuation timeout";
CM_ SG_ 981 ESP_a361_BBbrakeActuationDLC "Electronic stability control: a361 b bbrake actuation DLC";
CM_ SG_ 981 ESP_a362_BBbrakeActuationChecksu "Electronic stability control: a362 b bbrake actuation checksum";
CM_ SG_ 981 ESP_a363_BBbrakeActuationCounter "Electronic stability control: a363 b bbrake actuation counter";
CM_ SG_ 981 ESP_a364_DIgearInvalid "Electronic stability control: a364 d igear invalid";
CM_ SG_ 981 ESP_a365_TCSInputQualityTooLow "Electronic stability control: a365 TCS input quality too low";
CM_ SG_ 981 ESP_a366_ActuatorBlendingModeReq "Electronic stability control: a366 actuator blending mode req not available";
CM_ SG_ 981 ESP_a367_CBDS_fillBufferThreshol "Electronic stability control: a367 CBDS fill buffer threshold";
CM_ SG_ 981 ESP_a368_CBDS_fmeInternalEvent "Electronic stability control: a368 CBDS fme internal event";
CM_ SG_ 981 ESP_a369_LargeLeakageDetectedByD "Electronic stability control: a369 large leakage detected by DPB";
CM_ SG_ 981 ESP_a370_DPB_actuator4Timeout "Electronic stability control: a370 DPB actuator4 timeout";
CM_ SG_ 981 ESP_a371_DPB_actuator4DLC "Electronic stability control: a371 DPB actuator4 DLC";
CM_ SG_ 981 ESP_a372_DPB_actuator4Checksum "Electronic stability control: a372 DPB actuator4 checksum";
CM_ SG_ 981 ESP_a373_DPB_actuator4Counter "Electronic stability control: a373 DPB actuator4 counter";
CM_ SG_ 981 ESP_a374_StatInvalid_DI_FullSNA "Electronic stability control: a374 stat invalid DI full SNA";
CM_ SG_ 981 ESP_a375_PM_locStateCounter "Electronic stability control: a375 PM loc state counter";
CM_ SG_ 981 ESP_a376_PM_locStateChecksum "Electronic stability control: a376 PM loc state checksum";
CM_ SG_ 981 ESP_a377_PM_locStateDLC "Electronic stability control: a377 PM loc state DLC";
CM_ SG_ 981 ESP_a378_PM_locStateTimeout "Electronic stability control: a378 PM loc state timeout";
CM_ BO_ 805 "Electronic stability control message: info";
CM_ SG_ 805 ESP_infoIndex "Electronic stability control: info index";
CM_ SG_ 805 ESP_infoBuildType "Electronic stability control: info build type";
CM_ SG_ 805 ESP_vehFlashMode "Electronic stability control: veh flash mode";
CM_ SG_ 805 ESP_infoComponentID "Electronic stability control: info component ID";
CM_ SG_ 805 ESP_infoPcbaID "Electronic stability control: info pcba ID";
CM_ SG_ 805 ESP_infoAssemblyID "Electronic stability control: info assembly ID";
CM_ SG_ 805 ESP_infoUsageID "Electronic stability control: info usage ID";
CM_ SG_ 805 ESP_infoSubUsageID "Electronic stability control: info sub usage ID";
CM_ SG_ 805 ESP_infoApplicationCRC "Indicating the Application CRC value of firmware running in system.";
CM_ SG_ 805 ESP_infoVehicleVariant "Electronic stability control: info vehicle variant";
CM_ SG_ 805 ESP_infoSubcomponent1 "Electronic stability control: info subcomponent1";
CM_ SG_ 805 ESP_infoBootUdsProtoVersion "Electronic stability control: info boot uds proto version";
CM_ SG_ 805 ESP_infoBootloaderCRC "Electronic stability control: info bootloader CRC";
CM_ SG_ 805 ESP_infoVariantCRC "Indicating the Calibration CRC value of firmware running in system.";
CM_ BO_ 861 "Electric brake booster message: alert matrix";
CM_ SG_ 861 IBST_matrixIndex "Electric brake booster: matrix index";
CM_ SG_ 861 IBST_a001_microSupplyError "Electric brake booster: a001 micro supply error";
CM_ SG_ 861 IBST_a002_HWBISTError "Electric brake booster: a002 HWBIST error";
CM_ SG_ 861 IBST_a003_RAMFault "Electric brake booster: a003 RAM fault";
CM_ SG_ 861 IBST_a004_flashFault "Electric brake booster: a004 flash fault";
CM_ SG_ 861 IBST_a005_microSafetyFault "Electric brake booster: a005 micro safety fault";
CM_ SG_ 861 IBST_a006_microSafetyLogicFault "Electric brake booster: a006 micro safety logic fault";
CM_ SG_ 861 IBST_a007_RBCPUException "Electric brake booster: a007 RBCPU exception";
CM_ SG_ 861 IBST_a008_stackOverUnderFlow "Electric brake booster: a008 stack over under flow";
CM_ SG_ 861 IBST_a009_systemErrorHook "Electric brake booster: a009 system error hook";
CM_ SG_ 861 IBST_a010_OSErrorHook "Electric brake booster: a010 OS error hook";
CM_ SG_ 861 IBST_a011_systemTaskOverRun "Electric brake booster: a011 system task over run";
CM_ SG_ 861 IBST_a012_OSTaskSchemeError "Electric brake booster: a012 OS task scheme error";
CM_ SG_ 861 IBST_a013_systemTaskJitter "Electric brake booster: a013 system task jitter";
CM_ SG_ 861 IBST_a014_DMATransferError "Electric brake booster: a014 DMA transfer error";
CM_ SG_ 861 IBST_a015_asicOscillatorError "Electric brake booster: a015 asic oscillator error";
CM_ SG_ 861 IBST_a016_RBBLMShaftShiftError "Electric brake booster: a016 RBBLM shaft shift error";
CM_ SG_ 861 IBST_a017_assertionFault "Electric brake booster: a017 assertion fault";
CM_ SG_ 861 IBST_a018_unsupportedHW "Electric brake booster: a018 unsupported HW";
CM_ SG_ 861 IBST_a019_supplyASICInitFault "Electric brake booster: a019 supply ASIC init fault";
CM_ SG_ 861 IBST_a020_VPREU5VOutOfRange "Electric brake booster: a020 VPREU5 v out of range";
CM_ SG_ 861 IBST_a021_IREFOutOfRange "Electric brake booster: a021 IREF out of range";
CM_ SG_ 861 IBST_a022_U5VTestFault "Electric brake booster: a022 U5 v test fault";
CM_ SG_ 861 IBST_a023_U5VOutOfRange "Electric brake booster: a023 U5 v out of range";
CM_ SG_ 861 IBST_a024_chargePumpFault "Electric brake booster: a024 charge pump fault";
CM_ SG_ 861 IBST_a025_ecuClockTestFault "Electric brake booster: a025 ecu clock test fault";
CM_ SG_ 861 IBST_a026_ecuBistCmdTestFault "Electric brake booster: a026 ecu bist cmd test fault";
CM_ SG_ 861 IBST_a027_ecuFastWdTestFault "Electric brake booster: a027 ecu fast wd test fault";
CM_ SG_ 861 IBST_a028_ecuBistFaultCtrFault "Electric brake booster: a028 ecu bist fault ctr fault";
CM_ SG_ 861 IBST_a029_ecuErrpinCounterFault "Electric brake booster: a029 ecu errpin counter fault";
CM_ SG_ 861 IBST_a030_ecuEnableElLowFault "Electric brake booster: a030 ecu enable el low fault";
CM_ SG_ 861 IBST_a031_decoupleBitTestFault "Electric brake booster: a031 decouple bit test fault";
CM_ SG_ 861 IBST_a032_ecuEnableElHighFault "Electric brake booster: a032 ecu enable el high fault";
CM_ SG_ 861 IBST_a033_ecuWdStartuptestFault "Electric brake booster: a033 ecu wd startuptest fault";
CM_ SG_ 861 IBST_a034_ecuEnableHyHighFault "Electric brake booster: a034 ecu enable hy high fault";
CM_ SG_ 861 IBST_a035_ecuEnableHyLowFault "Electric brake booster: a035 ecu enable hy low fault";
CM_ SG_ 861 IBST_a036_MRGPathTestFault "Electric brake booster: a036 MRG path test fault";
CM_ SG_ 861 IBST_a037_ecuWdSContinuousError "Electric brake booster: a037 ecu wd s continuous error";
CM_ SG_ 861 IBST_a038_ecuEnContinuousError "Electric brake booster: a038 ecu en continuous error";
CM_ SG_ 861 IBST_a039_GTMRefFrequencyError "Electric brake booster: a039 GTM ref frequency error";
CM_ SG_ 861 IBST_a040_GTMTbuMonError "Electric brake booster: a040 GTM tbu mon error";
CM_ SG_ 861 IBST_a041_micAsicClkInError "Electric brake booster: a041 mic asic clk in error";
CM_ SG_ 861 IBST_a042_micAsicInitTestError "Electric brake booster: a042 mic asic init test error";
CM_ SG_ 861 IBST_a043_micSpiTransferError "Electric brake booster: a043 mic spi transfer error";
CM_ SG_ 861 IBST_a044_NvMEepromWIP "Electric brake booster: a044 nv m eeprom WIP";
CM_ SG_ 861 IBST_a045_WdhAsicWdErrorCntStuck "Electric brake booster: a045 wdh asic wd error cnt stuck";
CM_ SG_ 861 IBST_a046_WdhAsicWdErrorCntLimit "Electric brake booster: a046 wdh asic wd error cnt limit";
CM_ SG_ 861 IBST_a047_WdhAsicWdCmdMissing "Electric brake booster: a047 wdh asic wd cmd missing";
CM_ SG_ 861 IBST_a048_WdhSwBistConCnt "Electric brake booster: a048 wdh sw bist con cnt";
CM_ SG_ 861 IBST_a049_WdhTaskMonConCnt "Electric brake booster: a049 wdh task mon con cnt";
CM_ SG_ 861 IBST_a050_VPreExternalFeeding "Electric brake booster: a050 v pre external feeding";
CM_ SG_ 861 IBST_a051_ecuBandgap "Electric brake booster: a051 ecu bandgap";
CM_ SG_ 861 IBST_a052_AdcPinTest "Electric brake booster: a052 adc pin test";
CM_ SG_ 861 IBST_a053_AdcSelftestC5P "Electric brake booster: a053 adc selftest C5 p";
CM_ SG_ 861 IBST_a054_AdcPeripheralFault "Electric brake booster: a054 adc peripheral fault";
CM_ SG_ 861 IBST_a055_UB6SupplyPathFault "Electric brake booster: a055 UB6 supply path fault";
CM_ SG_ 861 IBST_a056_UB6PlausiMonFault "Electric brake booster: a056 UB6 plausi mon fault";
CM_ SG_ 861 IBST_a057_microRegisterFault "Electric brake booster: a057 micro register fault";
CM_ SG_ 861 IBST_a058_NvMWriteCycleExceed "Electric brake booster: a058 nv m write cycle exceed";
CM_ SG_ 861 IBST_a059_NvMEepromSize "Electric brake booster: a059 nv m eeprom size";
CM_ SG_ 861 IBST_a060_NvMMigrationFault "Electric brake booster: a060 nv m migration fault";
CM_ SG_ 861 IBST_a061_AswSystemTimeOut "Electric brake booster: a061 asw system time out";
CM_ SG_ 861 IBST_a062_MICB6TransferError "Electric brake booster: a062 MICB6 transfer error";
CM_ SG_ 861 IBST_a063_tempSens2ShortToSupply "Electric brake booster: a063 temp sens2 short to supply";
CM_ SG_ 861 IBST_a064_tempSens1ShortToGround "Electric brake booster: a064 temp sens1 short to ground";
CM_ SG_ 861 IBST_a065_tempSens2ShortToGround "Electric brake booster: a065 temp sens2 short to ground";
CM_ SG_ 861 IBST_a066_tempSens1ShortToSupply "Electric brake booster: a066 temp sens1 short to supply";
CM_ SG_ 861 IBST_a067_tempSensImplausVoltage "Electric brake booster: a067 temp sens implaus voltage";
CM_ SG_ 861 IBST_a068_chargePumpUndervoltage "Electric brake booster: a068 charge pump undervoltage";
CM_ SG_ 861 IBST_a069_greasingRoutineFault "Electric brake booster: a069 greasing routine fault";
CM_ SG_ 861 IBST_a070_notShutDownNvMWrite "Electric brake booster: a070 not shut down nv m write";
CM_ SG_ 861 IBST_a071_notShutDownNvMRead "Electric brake booster: a071 not shut down nv m read";
CM_ SG_ 861 IBST_a072_notShutDownRight "Electric brake booster: a072 not shut down right";
CM_ SG_ 861 IBST_a073_jumpInAdjustNvMRead "Electric brake booster: a073 jump in adjust nv m read";
CM_ SG_ 861 IBST_a074_FindIdleDataNvMWrite "Electric brake booster: a074 find idle data nv m write";
CM_ SG_ 861 IBST_a075_FindIdleRoutineFault "Electric brake booster: a075 find idle routine fault";
CM_ SG_ 861 IBST_a076_masterCylLengthRead "Electric brake booster: a076 master cyl length read";
CM_ SG_ 861 IBST_a077_runOutMotorSaturated "Electric brake booster: a077 run out motor saturated";
CM_ SG_ 861 IBST_a078_wearOffsetCompNVMRead "Electric brake booster: a078 wear offset comp NVM read";
CM_ SG_ 861 IBST_a079_motorTempHighLevel1 "Electric brake booster: a079 motor temp high level1";
CM_ SG_ 861 IBST_a080_motorTempHighLevel2 "Electric brake booster: a080 motor temp high level2";
CM_ SG_ 861 IBST_a081_travelDeviation "Electric brake booster: a081 travel deviation";
CM_ SG_ 861 IBST_a082_motorSpeedDeviation "Electric brake booster: a082 motor speed deviation";
CM_ SG_ 861 IBST_a083_spindlePositionTooHigh "Electric brake booster: a083 spindle position too high";
CM_ SG_ 861 IBST_a084_CANTransceiverHWFault "Electric brake booster: a084 CAN transceiver HW fault";
CM_ SG_ 861 IBST_a085_supplyUndervoltageLvl3 "Electric brake booster: a085 supply undervoltage lvl3";
CM_ SG_ 861 IBST_a086_supplyOvervoltageLvl3 "Electric brake booster: a086 supply overvoltage lvl3";
CM_ SG_ 861 IBST_a087_rotorSinOutOfRangeLow "Electric brake booster: a087 rotor sin out of range low";
CM_ SG_ 861 IBST_a088_rotorCosOutOfRangeLow "Electric brake booster: a088 rotor cos out of range low";
CM_ SG_ 861 IBST_a089_rotorSinOutOfRangeHigh "Electric brake booster: a089 rotor sin out of range high";
CM_ SG_ 861 IBST_a090_rotorCosOutOfRangeHigh "Electric brake booster: a090 rotor cos out of range high";
CM_ SG_ 861 IBST_a091_SMMOneRequestsInit "Electric brake booster: a091 SMM one requests init";
CM_ SG_ 861 IBST_a092_systemStartTimeOut "Electric brake booster: a092 system start time out";
CM_ SG_ 861 IBST_a093_UEXSOvertemperature "Electric brake booster: a093 UEXS overtemperature";
CM_ SG_ 861 IBST_a094_XPASSEchoTimeDeviation "Electric brake booster: a094 XPASS echo time deviation";
CM_ SG_ 861 IBST_a095_XPASSTimeOut "Electric brake booster: a095 XPASS time out";
CM_ SG_ 861 IBST_a096_bridgeDriverMonError "Electric brake booster: a096 bridge driver mon error";
CM_ SG_ 861 IBST_a097_bridgeDriverError "Electric brake booster: a097 bridge driver error";
CM_ SG_ 861 IBST_a098_bridgeShortedPhase "Electric brake booster: a098 bridge shorted phase";
CM_ SG_ 861 IBST_a099_bridgeSwitchInitError "Electric brake booster: a099 bridge switch init error";
CM_ SG_ 861 IBST_a100_current2OffsetHigh "Electric brake booster: a100 current2 offset high";
CM_ SG_ 861 IBST_a101_current2OffsetLow "Electric brake booster: a101 current2 offset low";
CM_ SG_ 861 IBST_a102_current1OffsetHigh "Electric brake booster: a102 current1 offset high";
CM_ SG_ 861 IBST_a103_current1OffsetLow "Electric brake booster: a103 current1 offset low";
CM_ SG_ 861 IBST_a104_bridgeDriverShort "Electric brake booster: a104 bridge driver short";
CM_ SG_ 861 IBST_a105_LiPSUndervoltage "Electric brake booster: a105 li PS undervoltage";
CM_ SG_ 861 IBST_a106_LiPS5VSupply "Electric brake booster: a106 li PS5 v supply";
CM_ SG_ 861 IBST_a107_LiPS2PwmLineHigh "Electric brake booster: a107 li PS2 pwm line high";
CM_ SG_ 861 IBST_a108_LiPS2PwmLineLow "Electric brake booster: a108 li PS2 pwm line low";
CM_ SG_ 861 IBST_a109_LiPS2PwmTransmission "Electric brake booster: a109 li PS2 pwm transmission";
CM_ SG_ 861 IBST_a110_LiPS1SentLineHigh "Electric brake booster: a110 li PS1 sent line high";
CM_ SG_ 861 IBST_a111_LiPS1SentLineLow "Electric brake booster: a111 li PS1 sent line low";
CM_ SG_ 861 IBST_a112_LiPS1SentTransmission "Electric brake booster: a112 li PS1 sent transmission";
CM_ SG_ 861 IBST_a113_LiPS1SentSensor "Electric brake booster: a113 li PS1 sent sensor";
CM_ SG_ 861 IBST_a114_partyBusOff "Electric brake booster: a114 party bus off";
CM_ SG_ 861 IBST_a115_chassisBusOff "Electric brake booster: a115 chassis bus off";
CM_ SG_ 861 IBST_a116_supplyUndervoltageLvl2 "Electric brake booster: a116 supply undervoltage lvl2";
CM_ SG_ 861 IBST_a117_supplyOvervoltageLvl2 "Electric brake booster: a117 supply overvoltage lvl2";
CM_ SG_ 861 IBST_a118_RPSNvMReadFault "Electric brake booster: a118 RPS nv m read fault";
CM_ SG_ 861 IBST_a119_RPSWrongCalibData "Electric brake booster: a119 RPS wrong calib data";
CM_ SG_ 861 IBST_a120_RPSVectorRangeHigh "Electric brake booster: a120 RPS vector range high";
CM_ SG_ 861 IBST_a121_RPSVectorRangeLow "Electric brake booster: a121 RPS vector range low";
CM_ SG_ 861 IBST_a122_RPSVectorOscillating "Electric brake booster: a122 RPS vector oscillating";
CM_ SG_ 861 IBST_a123_bridgeDriverUnavail "Electric brake booster: a123 bridge driver unavail";
CM_ SG_ 861 IBST_a124_OBDCurrent1OORHigh "Electric brake booster: a124 OBD current1 OOR high";
CM_ SG_ 861 IBST_a125_OBDCurrent2OORHigh "Electric brake booster: a125 OBD current2 OOR high";
CM_ SG_ 861 IBST_a126_OBDCurrent1OORLow "Electric brake booster: a126 OBD current1 OOR low";
CM_ SG_ 861 IBST_a127_OBDCurrent2OORLow "Electric brake booster: a127 OBD current2 OOR low";
CM_ SG_ 861 IBST_a128_BLMMuxerTimeoutError "Electric brake booster: a128 BLM muxer timeout error";
CM_ SG_ 861 IBST_a129_loadDumpOnFSLTest "Electric brake booster: a129 load dump on FSL test";
CM_ SG_ 861 IBST_a130_DTSFunctionalRangeLow "Electric brake booster: a130 DTS functional range low";
CM_ SG_ 861 IBST_a131_DTSFunctionalRangeHigh "Electric brake booster: a131 DTS functional range high";
CM_ SG_ 861 IBST_a132_DTSPlausiCheck1vs2 "Electric brake booster: a132 DTS plausi check1vs2";
CM_ SG_ 861 IBST_a133_DTSOffsetTooLow "Electric brake booster: a133 DTS offset too low";
CM_ SG_ 861 IBST_a134_DTSOffsetTooHigh "Electric brake booster: a134 DTS offset too high";
CM_ SG_ 861 IBST_a135_ESPparty1DLC "Electric brake booster: a135 ES pparty1 DLC";
CM_ SG_ 861 IBST_a136_ESPparty1Timeout "Electric brake booster: a136 ES pparty1 timeout";
CM_ SG_ 861 IBST_a137_ESPparty1Checksum "Electric brake booster: a137 ES pparty1 checksum";
CM_ SG_ 861 IBST_a138_ESPparty1Counter "Electric brake booster: a138 ES pparty1 counter";
CM_ SG_ 861 IBST_a139_ESPparty2DLC "Electric brake booster: a139 ES pparty2 DLC";
CM_ SG_ 861 IBST_a140_ESPparty2Timeout "Electric brake booster: a140 ES pparty2 timeout";
CM_ SG_ 861 IBST_a141_ESPparty2Checksum "Electric brake booster: a141 ES pparty2 checksum";
CM_ SG_ 861 IBST_a142_ESPparty2Counter "Electric brake booster: a142 ES pparty2 counter";
CM_ SG_ 861 IBST_a143_ESPparty3DLC "Electric brake booster: a143 ES pparty3 DLC";
CM_ SG_ 861 IBST_a144_ESPparty3Timeout "Electric brake booster: a144 ES pparty3 timeout";
CM_ SG_ 861 IBST_a145_ESPparty3Checksum "Electric brake booster: a145 ES pparty3 checksum";
CM_ SG_ 861 IBST_a146_ESPparty3Counter "Electric brake booster: a146 ES pparty3 counter";
CM_ SG_ 861 IBST_a147_PSCMotorSizeReadFault "Electric brake booster: a147 PSC motor size read fault";
CM_ SG_ 861 IBST_a148_MLIGainMechReadFault "Electric brake booster: a148 MLI gain mech read fault";
CM_ SG_ 861 IBST_a149_MLITMCAreaReadFault "Electric brake booster: a149 MLITMC area read fault";
CM_ SG_ 861 IBST_a150_motorTestFault "Electric brake booster: a150 motor test fault";
CM_ SG_ 861 IBST_a151_PSCGearRatioReadFault "Electric brake booster: a151 PSC gear ratio read fault";
CM_ SG_ 861 IBST_a152_PSCVoltageImplausible "Electric brake booster: a152 PSC voltage implausible";
CM_ SG_ 861 IBST_a153_unused "Electric brake booster: a153 unused";
CM_ SG_ 861 IBST_a154_unused "Electric brake booster: a154 unused";
CM_ SG_ 861 IBST_a155_supplyUndervoltageLvl1 "Electric brake booster: a155 supply undervoltage lvl1";
CM_ SG_ 861 IBST_a156_supplyOvervoltageLvl1 "Electric brake booster: a156 supply overvoltage lvl1";
CM_ SG_ 861 IBST_a157_masterCylPressInvalid "Electric brake booster: a157 master cyl press invalid";
CM_ SG_ 861 IBST_a158_DTSOffsHighSuspicious "Electric brake booster: a158 DTS offs high suspicious";
CM_ SG_ 861 IBST_a159_FindIdleNvMReadError "Electric brake booster: a159 find idle nv m read error";
CM_ SG_ 861 IBST_a160_DTSIDTimeOut "Electric brake booster: a160 DTSID time out";
CM_ SG_ 861 IBST_a161_powerPackMismatch "Electric brake booster: a161 power pack mismatch";
CM_ SG_ 861 IBST_a162_idlePosNotDetected "Electric brake booster: a162 idle pos not detected";
CM_ SG_ 861 IBST_a163_ESPpEstMaxInvalid "Electric brake booster: a163 ES pp est max invalid";
CM_ SG_ 861 IBST_a164_ESPVehicleSpeedInvalid "Electric brake booster: a164 ESP vehicle speed invalid";
CM_ SG_ 861 IBST_a165_ESPpForceBlendInvalid "Electric brake booster: a165 ES pp force blend invalid";
CM_ SG_ 861 IBST_a166_ESPpMcVirtualInvalid "Electric brake booster: a166 ES pp mc virtual invalid";
CM_ SG_ 861 IBST_a167_ESPqTargetExterInvalid "Electric brake booster: a167 ES pq target exter invalid";
CM_ SG_ 861 IBST_a168_CANOvervoltage "Electric brake booster: a168 CAN overvoltage";
CM_ SG_ 861 IBST_a169_CANUndervoltage "Electric brake booster: a169 CAN undervoltage";
CM_ SG_ 861 IBST_a170_LVPowerStateTimeout "Electric brake booster: a170 LV power state timeout";
CM_ SG_ 861 IBST_a171_LVPowerStateChecksum "Electric brake booster: a171 LV power state checksum";
CM_ SG_ 861 IBST_a172_LVPowerStateDLC "Electric brake booster: a172 LV power state DLC";
CM_ SG_ 861 IBST_a173_LVPowerStateCounter "Electric brake booster: a173 LV power state counter";
CM_ SG_ 861 IBST_a174_LVOffStateInvalid "Electric brake booster: a174 LV off state invalid";
CM_ SG_ 861 IBST_a175_LVGoingDownInvalid "Electric brake booster: a175 LV going down invalid";
CM_ SG_ 861 IBST_a176_blockedPedalDetected "Electric brake booster: a176 blocked pedal detected";
CM_ SG_ 861 IBST_a177_EPBLsystemStatusMIA "Electric brake booster: a177 EPB lsystem status MIA";
CM_ SG_ 861 IBST_a178_EPBRsystemStatusMIA "Electric brake booster: a178 EPB rsystem status MIA";
CM_ SG_ 861 IBST_a179_VCLEFTepbmStatusMIA "Electric brake booster: a179 VCLEF tepbm status MIA";
CM_ SG_ 861 IBST_a180_VCRIGHTepbmStatusMIA "Electric brake booster: a180 VCRIGH tepbm status MIA";
CM_ SG_ 861 IBST_a181_DIchassisControlDLC "Electric brake booster: a181 d ichassis control DLC";
CM_ SG_ 861 IBST_a182_DIchassisControlTimeou "Electric brake booster: a182 d ichassis control timeout";
CM_ SG_ 861 IBST_a183_DIchassisControlChecks "Electric brake booster: a183 d ichassis control checksum";
CM_ SG_ 861 IBST_a184_DIchassisControlCounte "Electric brake booster: a184 d ichassis control counter";
CM_ SG_ 861 IBST_a185_rightBusOff "Electric brake booster: a185 right bus off";
CM_ SG_ 861 IBST_a186_rightBusPassive "Electric brake booster: a186 right bus passive";
CM_ SG_ 861 IBST_a187_brakeBusOff "Electric brake booster: a187 brake bus off";
CM_ SG_ 861 IBST_a188_brakeBusPassive "Electric brake booster: a188 brake bus passive";
CM_ SG_ 861 IBST_a189_rightVCLVPowerStateTim "Electric brake booster: a189 right VCLV power state timeout";
CM_ SG_ 861 IBST_a190_rightVCLVPowerStateDLC "Electric brake booster: a190 right VCLV power state DLC";
CM_ SG_ 861 IBST_a191_rightVCLVPowerStateChe "Electric brake booster: a191 right VCLV power state checksum";
CM_ SG_ 861 IBST_a192_rightVCLVPowerStateCou "Electric brake booster: a192 right VCLV power state counter";
CM_ SG_ 861 IBST_a193_leftVCLVPowerStateTime "Electric brake booster: a193 left VCLV power state timeout";
CM_ SG_ 861 IBST_a194_leftVCLVPowerStateChec "Electric brake booster: a194 left VCLV power state checksum";
CM_ SG_ 861 IBST_a195_leftVCLVPowerStateDLC "Electric brake booster: a195 left VCLV power state DLC";
CM_ SG_ 861 IBST_a196_leftVCLVPowerStateCoun "Electric brake booster: a196 left VCLV power state counter";
CM_ SG_ 861 IBST_a197_brakeLatencyReductionA "Electric brake booster: a197 brake latency reduction active";
CM_ SG_ 861 IBST_a198_aesActive "Electric brake booster: a198 aes active";
CM_ SG_ 861 IBST_a199_undefinedAlertDetected "Electric brake booster: a199 undefined alert detected";
CM_ SG_ 861 IBST_a200_aesFault "Electric brake booster: a200 aes fault";
CM_ SG_ 861 IBST_a201_EGGREAR1wheelSpeedsRea "Electric brake booster: a201 eggrear1wheel speeds rear time out";
CM_ SG_ 861 IBST_a202_EGGREAR1wheelSpeedsRea "Electric brake booster: a202 eggrear1wheel speeds rear checksum";
CM_ SG_ 861 IBST_a203_EGGREAR1wheelSpeedsRea "Electric brake booster: a203 eggrear1wheel speeds rear DLC";
CM_ SG_ 861 IBST_a204_EGGREAR1wheelSpeedsRea "Electric brake booster: a204 eggrear1wheel speeds rear counter";
CM_ SG_ 861 IBST_a205_EGGRIGHT1wheelSpeedsFr "Electric brake booster: a205 eggright1wheel speeds front time out";
CM_ SG_ 861 IBST_a206_EGGRIGHT1wheelSpeedsFr "Electric brake booster: a206 eggright1wheel speeds front checksum";
CM_ SG_ 861 IBST_a207_EGGRIGHT1wheelSpeedsFr "Electric brake booster: a207 eggright1wheel speeds front DLC";
CM_ SG_ 861 IBST_a208_EGGRIGHT1wheelSpeedsFr "Electric brake booster: a208 eggright1wheel speeds front counter";
CM_ SG_ 861 IBST_a209_reducedBrakePowerActiv "Electric brake booster: a209 reduced brake power active";
CM_ SG_ 861 IBST_a210_reducedBrakePowerNotAv "Electric brake booster: a210 reduced brake power not available";
CM_ SG_ 861 IBST_a211_DETReportError "Electric brake booster: a211 DET report error";
CM_ SG_ 861 IBST_a212_infoFailureWrongCUBASH "Electric brake booster: a212 info failure wrong CUBAS handling detected";
CM_ SG_ 861 IBST_a213_PDURouterinitializatio "Electric brake booster: a213 PDU routerinitialization failed";
CM_ SG_ 861 IBST_a214_LossOfPDUInstanceDetec "Electric brake booster: a214 loss of PDU instance detected";
CM_ SG_ 861 IBST_a215_UnsupportedSeriesHWDet "Electric brake booster: a215 unsupported series HW detected";
CM_ SG_ 861 IBST_a216_AsicMalfunctionDetecte "Electric brake booster: a216 asic malfunction detected";
CM_ SG_ 861 IBST_a217_AsicTrimmingNotComplet "Electric brake booster: a217 asic trimming not completed";
CM_ SG_ 861 IBST_a218_uCSafetyNotificationGR "Electric brake booster: a218 u c safety notification GRAM";
CM_ SG_ 861 IBST_a219_uCSafetyNotification "Electric brake booster: a219 u c safety notification";
CM_ SG_ 861 IBST_a220_ASICOvercurrentOnGPIO2 "Electric brake booster: a220 ASIC overcurrent on GPIO250 2";
CM_ SG_ 861 IBST_a221_ASICOvercurrentOnGPIO2 "Electric brake booster: a221 ASIC overcurrent on GPIO250 1";
CM_ SG_ 861 IBST_a222_ASICOvercurrentOnGPIO5 "Electric brake booster: a222 ASIC overcurrent on GPIO50 4";
CM_ SG_ 861 IBST_a223_ASICOvercurrentOnGPIO5 "Electric brake booster: a223 ASIC overcurrent on GPIO50 3";
CM_ SG_ 861 IBST_a224_ASICOvercurrentOnGPIO5 "Electric brake booster: a224 ASIC overcurrent on GPIO50 2";
CM_ SG_ 861 IBST_a225_ASICOvercurrentOnGPIO5 "Electric brake booster: a225 ASIC overcurrent on GPIO50 1";
CM_ SG_ 861 IBST_a226_ASICOvercurrentOnWRHS "Electric brake booster: a226 ASIC overcurrent on WRHS";
CM_ SG_ 861 IBST_a227_wakeRequestMismatchDet "Electric brake booster: a227 wake request mismatch detected";
CM_ SG_ 861 IBST_a228_BlockedPedalDetectedDu "Electric brake booster: a228 blocked pedal detected during HAD";
CM_ SG_ 861 IBST_a229_BlockedPedalDetected "Electric brake booster: a229 blocked pedal detected";
CM_ SG_ 861 IBST_a230_DTS2FunctionalRangeLow "Electric brake booster: a230 DTS2 functional range low";
CM_ SG_ 861 IBST_a231_DTS2FunctionalRangeLow "Electric brake booster: a231 DTS2 functional range low";
CM_ SG_ 861 IBST_a232_PostAssemblyRoutineFai "Electric brake booster: a232 post assembly routine failed";
CM_ SG_ 861 IBST_a233_ReferenceRunAbortByECU "Electric brake booster: a233 reference run abort by ECU reset";
CM_ SG_ 861 IBST_a234_LiPSOutOfRangeHigh "Electric brake booster: a234 li PS out of range high";
CM_ SG_ 861 IBST_a235_LiPSOutOfRangeLow "Electric brake booster: a235 li PS out of range low";
CM_ BO_ 813 "Electric brake booster message: info";
CM_ SG_ 813 IBST_infoIndex "Electric brake booster: info index";
CM_ SG_ 813 IBST_infoBuildType "Electric brake booster: info build type";
CM_ SG_ 813 IBST_infoComponentID "Electric brake booster: info component ID";
CM_ SG_ 813 IBST_infoPcbaID "Electric brake booster: info pcba ID";
CM_ SG_ 813 IBST_infoAssemblyID "Electric brake booster: info assembly ID";
CM_ SG_ 813 IBST_infoUsageID "Electric brake booster: info usage ID";
CM_ SG_ 813 IBST_infoSubUsageID "Electric brake booster: info sub usage ID";
CM_ SG_ 813 IBST_infoApplicationCRC "Indicating the Application CRC value of firmware running in system.";
CM_ SG_ 813 IBST_infoBootUdsProtoVersion "Electric brake booster: info boot uds proto version";
CM_ SG_ 813 IBST_infoBootloaderCRC "Electric brake booster: info bootloader CRC";
CM_ SG_ 813 IBST_infoVariantCRC "Indicating the Calibration CRC value of firmware running in system.";
CM_ BO_ 1486 "Parking assist sensors message: alert log";
CM_ SG_ 1486 PARK_alertID "Parking assist sensors: alert ID";
CM_ SG_ 1486 PARK_alertState "Parking assist sensors: alert state";
CM_ SG_ 1486 PARK_sw001_sensorTemperature "Parking assist sensors: sw001 sensor temperature";
CM_ SG_ 1486 PARK_sw002_membraneDisconct "Parking assist sensors: sw002 membrane disconct";
CM_ SG_ 1486 PARK_sw002_dampResistorFail "Parking assist sensors: sw002 damp resistor fail";
CM_ SG_ 1486 PARK_sw002_resonanceDrift "Parking assist sensors: sw002 resonance drift";
CM_ SG_ 1486 PARK_sw002_sensorCRC "Parking assist sensors: sw002 sensor CRC";
CM_ SG_ 1486 PARK_sw002_recieveFailure "Parking assist sensors: sw002 recieve failure";
CM_ SG_ 1486 PARK_sw002_diagnosticTransferErr "Parking assist sensors: sw002 diagnostic transfer error";
CM_ SG_ 1486 PARK_sw003_linError "Parking assist sensors: sw003 lin error";
CM_ SG_ 1486 PARK_sw003_linBusError "Parking assist sensors: sw003 lin bus error";
CM_ SG_ 1486 PARK_sw003_linFrameCountError "Parking assist sensors: sw003 lin frame count error";
CM_ SG_ 1486 PARK_sw004_reverbPeriod "Parking assist sensors: sw004 reverb period";
CM_ SG_ 1486 PARK_sw004_reverbTime "Parking assist sensors: sw004 reverb time";
CM_ SG_ 1486 PARK_sw004_highAttenTime "Parking assist sensors: sw004 high atten time";
CM_ SG_ 1486 PARK_sw004_closeConstEcho "Parking assist sensors: sw004 close const echo";
CM_ SG_ 1486 PARK_sw004_lowAttenTime "Parking assist sensors: sw004 low atten time";
CM_ SG_ 1486 PARK_sw004_attenTimeJitter "Parking assist sensors: sw004 atten time jitter";
CM_ SG_ 1486 PARK_sw004_reverbFreqJitter "Parking assist sensors: sw004 reverb freq jitter";
CM_ SG_ 1486 PARK_sw006_sensorTemperature "Parking assist sensors: sw006 sensor temperature";
CM_ SG_ 1486 PARK_sw007_membraneDisconct "Parking assist sensors: sw007 membrane disconct";
CM_ SG_ 1486 PARK_sw007_dampResistorFail "Parking assist sensors: sw007 damp resistor fail";
CM_ SG_ 1486 PARK_sw007_resonanceDrift "Parking assist sensors: sw007 resonance drift";
CM_ SG_ 1486 PARK_sw007_sensorCRC "Parking assist sensors: sw007 sensor CRC";
CM_ SG_ 1486 PARK_sw007_recieveFailure "Parking assist sensors: sw007 recieve failure";
CM_ SG_ 1486 PARK_sw007_diagnosticTransferErr "Parking assist sensors: sw007 diagnostic transfer error";
CM_ SG_ 1486 PARK_sw008_linError "Parking assist sensors: sw008 lin error";
CM_ SG_ 1486 PARK_sw008_linBusError "Parking assist sensors: sw008 lin bus error";
CM_ SG_ 1486 PARK_sw008_linFrameCountError "Parking assist sensors: sw008 lin frame count error";
CM_ SG_ 1486 PARK_sw009_reverbPeriod "Parking assist sensors: sw009 reverb period";
CM_ SG_ 1486 PARK_sw009_reverbTime "Parking assist sensors: sw009 reverb time";
CM_ SG_ 1486 PARK_sw009_highAttenTime "Parking assist sensors: sw009 high atten time";
CM_ SG_ 1486 PARK_sw009_closeConstEcho "Parking assist sensors: sw009 close const echo";
CM_ SG_ 1486 PARK_sw009_lowAttenTime "Parking assist sensors: sw009 low atten time";
CM_ SG_ 1486 PARK_sw009_attenTimeJitter "Parking assist sensors: sw009 atten time jitter";
CM_ SG_ 1486 PARK_sw009_reverbFreqJitter "Parking assist sensors: sw009 reverb freq jitter";
CM_ SG_ 1486 PARK_sw011_sensorTemperature "Parking assist sensors: sw011 sensor temperature";
CM_ SG_ 1486 PARK_sw012_membraneDisconct "Parking assist sensors: sw012 membrane disconct";
CM_ SG_ 1486 PARK_sw012_dampResistorFail "Parking assist sensors: sw012 damp resistor fail";
CM_ SG_ 1486 PARK_sw012_resonanceDrift "Parking assist sensors: sw012 resonance drift";
CM_ SG_ 1486 PARK_sw012_sensorCRC "Parking assist sensors: sw012 sensor CRC";
CM_ SG_ 1486 PARK_sw012_recieveFailure "Parking assist sensors: sw012 recieve failure";
CM_ SG_ 1486 PARK_sw012_diagnosticTransferErr "Parking assist sensors: sw012 diagnostic transfer error";
CM_ SG_ 1486 PARK_sw013_linError "Parking assist sensors: sw013 lin error";
CM_ SG_ 1486 PARK_sw013_linBusError "Parking assist sensors: sw013 lin bus error";
CM_ SG_ 1486 PARK_sw013_linFrameCountError "Parking assist sensors: sw013 lin frame count error";
CM_ SG_ 1486 PARK_sw014_reverbPeriod "Parking assist sensors: sw014 reverb period";
CM_ SG_ 1486 PARK_sw014_reverbTime "Parking assist sensors: sw014 reverb time";
CM_ SG_ 1486 PARK_sw014_highAttenTime "Parking assist sensors: sw014 high atten time";
CM_ SG_ 1486 PARK_sw014_closeConstEcho "Parking assist sensors: sw014 close const echo";
CM_ SG_ 1486 PARK_sw014_lowAttenTime "Parking assist sensors: sw014 low atten time";
CM_ SG_ 1486 PARK_sw014_attenTimeJitter "Parking assist sensors: sw014 atten time jitter";
CM_ SG_ 1486 PARK_sw014_reverbFreqJitter "Parking assist sensors: sw014 reverb freq jitter";
CM_ SG_ 1486 PARK_sw016_sensorTemperature "Parking assist sensors: sw016 sensor temperature";
CM_ SG_ 1486 PARK_sw017_membraneDisconct "Parking assist sensors: sw017 membrane disconct";
CM_ SG_ 1486 PARK_sw017_dampResistorFail "Parking assist sensors: sw017 damp resistor fail";
CM_ SG_ 1486 PARK_sw017_resonanceDrift "Parking assist sensors: sw017 resonance drift";
CM_ SG_ 1486 PARK_sw017_sensorCRC "Parking assist sensors: sw017 sensor CRC";
CM_ SG_ 1486 PARK_sw017_recieveFailure "Parking assist sensors: sw017 recieve failure";
CM_ SG_ 1486 PARK_sw017_diagnosticTransferErr "Parking assist sensors: sw017 diagnostic transfer error";
CM_ SG_ 1486 PARK_sw018_linError "Parking assist sensors: sw018 lin error";
CM_ SG_ 1486 PARK_sw018_linBusError "Parking assist sensors: sw018 lin bus error";
CM_ SG_ 1486 PARK_sw018_linFrameCountError "Parking assist sensors: sw018 lin frame count error";
CM_ SG_ 1486 PARK_sw019_reverbPeriod "Parking assist sensors: sw019 reverb period";
CM_ SG_ 1486 PARK_sw019_reverbTime "Parking assist sensors: sw019 reverb time";
CM_ SG_ 1486 PARK_sw019_highAttenTime "Parking assist sensors: sw019 high atten time";
CM_ SG_ 1486 PARK_sw019_closeConstEcho "Parking assist sensors: sw019 close const echo";
CM_ SG_ 1486 PARK_sw019_lowAttenTime "Parking assist sensors: sw019 low atten time";
CM_ SG_ 1486 PARK_sw019_attenTimeJitter "Parking assist sensors: sw019 atten time jitter";
CM_ SG_ 1486 PARK_sw019_reverbFreqJitter "Parking assist sensors: sw019 reverb freq jitter";
CM_ SG_ 1486 PARK_sw021_sensorTemperature "Parking assist sensors: sw021 sensor temperature";
CM_ SG_ 1486 PARK_sw022_membraneDisconct "Parking assist sensors: sw022 membrane disconct";
CM_ SG_ 1486 PARK_sw022_dampResistorFail "Parking assist sensors: sw022 damp resistor fail";
CM_ SG_ 1486 PARK_sw022_resonanceDrift "Parking assist sensors: sw022 resonance drift";
CM_ SG_ 1486 PARK_sw022_sensorCRC "Parking assist sensors: sw022 sensor CRC";
CM_ SG_ 1486 PARK_sw022_recieveFailure "Parking assist sensors: sw022 recieve failure";
CM_ SG_ 1486 PARK_sw022_diagnosticTransferErr "Parking assist sensors: sw022 diagnostic transfer error";
CM_ SG_ 1486 PARK_sw023_linError "Parking assist sensors: sw023 lin error";
CM_ SG_ 1486 PARK_sw023_linBusError "Parking assist sensors: sw023 lin bus error";
CM_ SG_ 1486 PARK_sw023_linFrameCountError "Parking assist sensors: sw023 lin frame count error";
CM_ SG_ 1486 PARK_sw024_reverbPeriod "Parking assist sensors: sw024 reverb period";
CM_ SG_ 1486 PARK_sw024_reverbTime "Parking assist sensors: sw024 reverb time";
CM_ SG_ 1486 PARK_sw024_highAttenTime "Parking assist sensors: sw024 high atten time";
CM_ SG_ 1486 PARK_sw024_closeConstEcho "Parking assist sensors: sw024 close const echo";
CM_ SG_ 1486 PARK_sw024_lowAttenTime "Parking assist sensors: sw024 low atten time";
CM_ SG_ 1486 PARK_sw024_attenTimeJitter "Parking assist sensors: sw024 atten time jitter";
CM_ SG_ 1486 PARK_sw024_reverbFreqJitter "Parking assist sensors: sw024 reverb freq jitter";
CM_ SG_ 1486 PARK_sw026_sensorTemperature "Parking assist sensors: sw026 sensor temperature";
CM_ SG_ 1486 PARK_sw027_membraneDisconct "Parking assist sensors: sw027 membrane disconct";
CM_ SG_ 1486 PARK_sw027_dampResistorFail "Parking assist sensors: sw027 damp resistor fail";
CM_ SG_ 1486 PARK_sw027_resonanceDrift "Parking assist sensors: sw027 resonance drift";
CM_ SG_ 1486 PARK_sw027_sensorCRC "Parking assist sensors: sw027 sensor CRC";
CM_ SG_ 1486 PARK_sw027_recieveFailure "Parking assist sensors: sw027 recieve failure";
CM_ SG_ 1486 PARK_sw027_diagnosticTransferErr "Parking assist sensors: sw027 diagnostic transfer error";
CM_ SG_ 1486 PARK_sw028_linError "Parking assist sensors: sw028 lin error";
CM_ SG_ 1486 PARK_sw028_linBusError "Parking assist sensors: sw028 lin bus error";
CM_ SG_ 1486 PARK_sw028_linFrameCountError "Parking assist sensors: sw028 lin frame count error";
CM_ SG_ 1486 PARK_sw029_reverbPeriod "Parking assist sensors: sw029 reverb period";
CM_ SG_ 1486 PARK_sw029_reverbTime "Parking assist sensors: sw029 reverb time";
CM_ SG_ 1486 PARK_sw029_highAttenTime "Parking assist sensors: sw029 high atten time";
CM_ SG_ 1486 PARK_sw029_closeConstEcho "Parking assist sensors: sw029 close const echo";
CM_ SG_ 1486 PARK_sw029_lowAttenTime "Parking assist sensors: sw029 low atten time";
CM_ SG_ 1486 PARK_sw029_attenTimeJitter "Parking assist sensors: sw029 atten time jitter";
CM_ SG_ 1486 PARK_sw029_reverbFreqJitter "Parking assist sensors: sw029 reverb freq jitter";
CM_ SG_ 1486 PARK_sw031_sensorTemperature "Parking assist sensors: sw031 sensor temperature";
CM_ SG_ 1486 PARK_sw032_membraneDisconct "Parking assist sensors: sw032 membrane disconct";
CM_ SG_ 1486 PARK_sw032_dampResistorFail "Parking assist sensors: sw032 damp resistor fail";
CM_ SG_ 1486 PARK_sw032_resonanceDrift "Parking assist sensors: sw032 resonance drift";
CM_ SG_ 1486 PARK_sw032_sensorCRC "Parking assist sensors: sw032 sensor CRC";
CM_ SG_ 1486 PARK_sw032_recieveFailure "Parking assist sensors: sw032 recieve failure";
CM_ SG_ 1486 PARK_sw032_diagnosticTransferErr "Parking assist sensors: sw032 diagnostic transfer error";
CM_ SG_ 1486 PARK_sw033_linError "Parking assist sensors: sw033 lin error";
CM_ SG_ 1486 PARK_sw033_linBusError "Parking assist sensors: sw033 lin bus error";
CM_ SG_ 1486 PARK_sw033_linFrameCountError "Parking assist sensors: sw033 lin frame count error";
CM_ SG_ 1486 PARK_sw034_reverbPeriod "Parking assist sensors: sw034 reverb period";
CM_ SG_ 1486 PARK_sw034_reverbTime "Parking assist sensors: sw034 reverb time";
CM_ SG_ 1486 PARK_sw034_highAttenTime "Parking assist sensors: sw034 high atten time";
CM_ SG_ 1486 PARK_sw034_closeConstEcho "Parking assist sensors: sw034 close const echo";
CM_ SG_ 1486 PARK_sw034_lowAttenTime "Parking assist sensors: sw034 low atten time";
CM_ SG_ 1486 PARK_sw034_attenTimeJitter "Parking assist sensors: sw034 atten time jitter";
CM_ SG_ 1486 PARK_sw034_reverbFreqJitter "Parking assist sensors: sw034 reverb freq jitter";
CM_ SG_ 1486 PARK_sw036_sensorTemperature "Parking assist sensors: sw036 sensor temperature";
CM_ SG_ 1486 PARK_sw037_membraneDisconct "Parking assist sensors: sw037 membrane disconct";
CM_ SG_ 1486 PARK_sw037_dampResistorFail "Parking assist sensors: sw037 damp resistor fail";
CM_ SG_ 1486 PARK_sw037_resonanceDrift "Parking assist sensors: sw037 resonance drift";
CM_ SG_ 1486 PARK_sw037_sensorCRC "Parking assist sensors: sw037 sensor CRC";
CM_ SG_ 1486 PARK_sw037_recieveFailure "Parking assist sensors: sw037 recieve failure";
CM_ SG_ 1486 PARK_sw037_diagnosticTransferErr "Parking assist sensors: sw037 diagnostic transfer error";
CM_ SG_ 1486 PARK_sw038_linError "Parking assist sensors: sw038 lin error";
CM_ SG_ 1486 PARK_sw038_linBusError "Parking assist sensors: sw038 lin bus error";
CM_ SG_ 1486 PARK_sw038_linFrameCountError "Parking assist sensors: sw038 lin frame count error";
CM_ SG_ 1486 PARK_sw039_reverbPeriod "Parking assist sensors: sw039 reverb period";
CM_ SG_ 1486 PARK_sw039_reverbTime "Parking assist sensors: sw039 reverb time";
CM_ SG_ 1486 PARK_sw039_highAttenTime "Parking assist sensors: sw039 high atten time";
CM_ SG_ 1486 PARK_sw039_closeConstEcho "Parking assist sensors: sw039 close const echo";
CM_ SG_ 1486 PARK_sw039_lowAttenTime "Parking assist sensors: sw039 low atten time";
CM_ SG_ 1486 PARK_sw039_attenTimeJitter "Parking assist sensors: sw039 atten time jitter";
CM_ SG_ 1486 PARK_sw039_reverbFreqJitter "Parking assist sensors: sw039 reverb freq jitter";
CM_ SG_ 1486 PARK_sw041_sensorTemperature "Parking assist sensors: sw041 sensor temperature";
CM_ SG_ 1486 PARK_sw042_membraneDisconct "Parking assist sensors: sw042 membrane disconct";
CM_ SG_ 1486 PARK_sw042_dampResistorFail "Parking assist sensors: sw042 damp resistor fail";
CM_ SG_ 1486 PARK_sw042_resonanceDrift "Parking assist sensors: sw042 resonance drift";
CM_ SG_ 1486 PARK_sw042_sensorCRC "Parking assist sensors: sw042 sensor CRC";
CM_ SG_ 1486 PARK_sw042_recieveFailure "Parking assist sensors: sw042 recieve failure";
CM_ SG_ 1486 PARK_sw042_diagnosticTransferErr "Parking assist sensors: sw042 diagnostic transfer error";
CM_ SG_ 1486 PARK_sw043_linError "Parking assist sensors: sw043 lin error";
CM_ SG_ 1486 PARK_sw043_linBusError "Parking assist sensors: sw043 lin bus error";
CM_ SG_ 1486 PARK_sw043_linFrameCountError "Parking assist sensors: sw043 lin frame count error";
CM_ SG_ 1486 PARK_sw044_reverbPeriod "Parking assist sensors: sw044 reverb period";
CM_ SG_ 1486 PARK_sw044_reverbTime "Parking assist sensors: sw044 reverb time";
CM_ SG_ 1486 PARK_sw044_highAttenTime "Parking assist sensors: sw044 high atten time";
CM_ SG_ 1486 PARK_sw044_closeConstEcho "Parking assist sensors: sw044 close const echo";
CM_ SG_ 1486 PARK_sw044_lowAttenTime "Parking assist sensors: sw044 low atten time";
CM_ SG_ 1486 PARK_sw044_attenTimeJitter "Parking assist sensors: sw044 atten time jitter";
CM_ SG_ 1486 PARK_sw044_reverbFreqJitter "Parking assist sensors: sw044 reverb freq jitter";
CM_ SG_ 1486 PARK_sw046_sensorTemperature "Parking assist sensors: sw046 sensor temperature";
CM_ SG_ 1486 PARK_sw047_membraneDisconct "Parking assist sensors: sw047 membrane disconct";
CM_ SG_ 1486 PARK_sw047_dampResistorFail "Parking assist sensors: sw047 damp resistor fail";
CM_ SG_ 1486 PARK_sw047_resonanceDrift "Parking assist sensors: sw047 resonance drift";
CM_ SG_ 1486 PARK_sw047_sensorCRC "Parking assist sensors: sw047 sensor CRC";
CM_ SG_ 1486 PARK_sw047_recieveFailure "Parking assist sensors: sw047 recieve failure";
CM_ SG_ 1486 PARK_sw047_diagnosticTransferErr "Parking assist sensors: sw047 diagnostic transfer error";
CM_ SG_ 1486 PARK_sw048_linError "Parking assist sensors: sw048 lin error";
CM_ SG_ 1486 PARK_sw048_linBusError "Parking assist sensors: sw048 lin bus error";
CM_ SG_ 1486 PARK_sw048_linFrameCountError "Parking assist sensors: sw048 lin frame count error";
CM_ SG_ 1486 PARK_sw049_reverbPeriod "Parking assist sensors: sw049 reverb period";
CM_ SG_ 1486 PARK_sw049_reverbTime "Parking assist sensors: sw049 reverb time";
CM_ SG_ 1486 PARK_sw049_highAttenTime "Parking assist sensors: sw049 high atten time";
CM_ SG_ 1486 PARK_sw049_closeConstEcho "Parking assist sensors: sw049 close const echo";
CM_ SG_ 1486 PARK_sw049_lowAttenTime "Parking assist sensors: sw049 low atten time";
CM_ SG_ 1486 PARK_sw049_attenTimeJitter "Parking assist sensors: sw049 atten time jitter";
CM_ SG_ 1486 PARK_sw049_reverbFreqJitter "Parking assist sensors: sw049 reverb freq jitter";
CM_ SG_ 1486 PARK_sw051_sensorTemperature "Parking assist sensors: sw051 sensor temperature";
CM_ SG_ 1486 PARK_sw052_membraneDisconct "Parking assist sensors: sw052 membrane disconct";
CM_ SG_ 1486 PARK_sw052_dampResistorFail "Parking assist sensors: sw052 damp resistor fail";
CM_ SG_ 1486 PARK_sw052_resonanceDrift "Parking assist sensors: sw052 resonance drift";
CM_ SG_ 1486 PARK_sw052_sensorCRC "Parking assist sensors: sw052 sensor CRC";
CM_ SG_ 1486 PARK_sw052_recieveFailure "Parking assist sensors: sw052 recieve failure";
CM_ SG_ 1486 PARK_sw052_diagnosticTransferErr "Parking assist sensors: sw052 diagnostic transfer error";
CM_ SG_ 1486 PARK_sw053_linError "Parking assist sensors: sw053 lin error";
CM_ SG_ 1486 PARK_sw053_linBusError "Parking assist sensors: sw053 lin bus error";
CM_ SG_ 1486 PARK_sw053_linFrameCountError "Parking assist sensors: sw053 lin frame count error";
CM_ SG_ 1486 PARK_sw054_reverbPeriod "Parking assist sensors: sw054 reverb period";
CM_ SG_ 1486 PARK_sw054_reverbTime "Parking assist sensors: sw054 reverb time";
CM_ SG_ 1486 PARK_sw054_highAttenTime "Parking assist sensors: sw054 high atten time";
CM_ SG_ 1486 PARK_sw054_closeConstEcho "Parking assist sensors: sw054 close const echo";
CM_ SG_ 1486 PARK_sw054_lowAttenTime "Parking assist sensors: sw054 low atten time";
CM_ SG_ 1486 PARK_sw054_attenTimeJitter "Parking assist sensors: sw054 atten time jitter";
CM_ SG_ 1486 PARK_sw054_reverbFreqJitter "Parking assist sensors: sw054 reverb freq jitter";
CM_ SG_ 1486 PARK_sw056_sensorTemperature "Parking assist sensors: sw056 sensor temperature";
CM_ SG_ 1486 PARK_sw057_membraneDisconct "Parking assist sensors: sw057 membrane disconct";
CM_ SG_ 1486 PARK_sw057_dampResistorFail "Parking assist sensors: sw057 damp resistor fail";
CM_ SG_ 1486 PARK_sw057_resonanceDrift "Parking assist sensors: sw057 resonance drift";
CM_ SG_ 1486 PARK_sw057_sensorCRC "Parking assist sensors: sw057 sensor CRC";
CM_ SG_ 1486 PARK_sw057_recieveFailure "Parking assist sensors: sw057 recieve failure";
CM_ SG_ 1486 PARK_sw057_diagnosticTransferErr "Parking assist sensors: sw057 diagnostic transfer error";
CM_ SG_ 1486 PARK_sw058_linError "Parking assist sensors: sw058 lin error";
CM_ SG_ 1486 PARK_sw058_linBusError "Parking assist sensors: sw058 lin bus error";
CM_ SG_ 1486 PARK_sw058_linFrameCountError "Parking assist sensors: sw058 lin frame count error";
CM_ SG_ 1486 PARK_sw059_reverbPeriod "Parking assist sensors: sw059 reverb period";
CM_ SG_ 1486 PARK_sw059_reverbTime "Parking assist sensors: sw059 reverb time";
CM_ SG_ 1486 PARK_sw059_highAttenTime "Parking assist sensors: sw059 high atten time";
CM_ SG_ 1486 PARK_sw059_closeConstEcho "Parking assist sensors: sw059 close const echo";
CM_ SG_ 1486 PARK_sw059_lowAttenTime "Parking assist sensors: sw059 low atten time";
CM_ SG_ 1486 PARK_sw059_attenTimeJitter "Parking assist sensors: sw059 atten time jitter";
CM_ SG_ 1486 PARK_sw059_reverbFreqJitter "Parking assist sensors: sw059 reverb freq jitter";
CM_ SG_ 1486 PARK_sw061_voltage "Parking assist sensors: sw061 voltage";
CM_ SG_ 1486 PARK_sw063_voltage "Parking assist sensors: sw063 voltage";
CM_ SG_ 1486 PARK_sw064_faultCode "Parking assist sensors: sw064 fault code";
CM_ SG_ 1486 PARK_sw065_expectedCRC "Parking assist sensors: sw065 expected CRC";
CM_ SG_ 1486 PARK_sw065_calculatedCRC "Parking assist sensors: sw065 calculated CRC";
CM_ SG_ 1486 PARK_sw066_placeHolder "Parking assist sensors: sw066 place holder";
CM_ SG_ 1486 PARK_sw068_placeHolder "Parking assist sensors: sw068 place holder";
CM_ SG_ 1486 PARK_sw069_messageID "Parking assist sensors: sw069 message ID";
CM_ SG_ 1486 PARK_sw070_messageID "Parking assist sensors: sw070 message ID";
CM_ SG_ 1486 PARK_sw071_messageID "Parking assist sensors: sw071 message ID";
CM_ SG_ 1486 PARK_sw072_messageID "Parking assist sensors: sw072 message ID";
CM_ SG_ 1486 PARK_sw073_messageID "Parking assist sensors: sw073 message ID";
CM_ SG_ 1486 PARK_sw074_messageID "Parking assist sensors: sw074 message ID";
CM_ SG_ 1486 PARK_sw075_messageID "Parking assist sensors: sw075 message ID";
CM_ SG_ 1486 PARK_sw076_messageID "Parking assist sensors: sw076 message ID";
CM_ SG_ 1486 PARK_sw077_errorExp "Parking assist sensors: sw077 error exp";
CM_ SG_ 1486 PARK_sw077_errorRx "Parking assist sensors: sw077 error rx";
CM_ SG_ 1486 PARK_sw077_messageID "Parking assist sensors: sw077 message ID";
CM_ SG_ 1486 PARK_sw077_errorType "Parking assist sensors: sw077 error type";
CM_ SG_ 1486 PARK_sw078_errorExp "Parking assist sensors: sw078 error exp";
CM_ SG_ 1486 PARK_sw078_errorRx "Parking assist sensors: sw078 error rx";
CM_ SG_ 1486 PARK_sw078_messageID "Parking assist sensors: sw078 message ID";
CM_ SG_ 1486 PARK_sw078_errorType "Parking assist sensors: sw078 error type";
CM_ SG_ 1486 PARK_sw079_errorExp "Parking assist sensors: sw079 error exp";
CM_ SG_ 1486 PARK_sw079_errorRx "Parking assist sensors: sw079 error rx";
CM_ SG_ 1486 PARK_sw079_messageID "Parking assist sensors: sw079 message ID";
CM_ SG_ 1486 PARK_sw079_errorType "Parking assist sensors: sw079 error type";
CM_ SG_ 1486 PARK_sw080_errorExp "Parking assist sensors: sw080 error exp";
CM_ SG_ 1486 PARK_sw080_errorRx "Parking assist sensors: sw080 error rx";
CM_ SG_ 1486 PARK_sw080_messageID "Parking assist sensors: sw080 message ID";
CM_ SG_ 1486 PARK_sw080_errorType "Parking assist sensors: sw080 error type";
CM_ SG_ 1486 PARK_sw081_errorExp "Parking assist sensors: sw081 error exp";
CM_ SG_ 1486 PARK_sw081_errorRx "Parking assist sensors: sw081 error rx";
CM_ SG_ 1486 PARK_sw081_messageID "Parking assist sensors: sw081 message ID";
CM_ SG_ 1486 PARK_sw081_errorType "Parking assist sensors: sw081 error type";
CM_ SG_ 1486 PARK_sw082_errorExp "Parking assist sensors: sw082 error exp";
CM_ SG_ 1486 PARK_sw082_errorRx "Parking assist sensors: sw082 error rx";
CM_ SG_ 1486 PARK_sw082_messageID "Parking assist sensors: sw082 message ID";
CM_ SG_ 1486 PARK_sw082_errorType "Parking assist sensors: sw082 error type";
CM_ SG_ 1486 PARK_sw083_errorExp "Parking assist sensors: sw083 error exp";
CM_ SG_ 1486 PARK_sw083_errorRx "Parking assist sensors: sw083 error rx";
CM_ SG_ 1486 PARK_sw083_messageID "Parking assist sensors: sw083 message ID";
CM_ SG_ 1486 PARK_sw083_errorType "Parking assist sensors: sw083 error type";
CM_ SG_ 1486 PARK_sw084_errorExp "Parking assist sensors: sw084 error exp";
CM_ SG_ 1486 PARK_sw084_errorRx "Parking assist sensors: sw084 error rx";
CM_ SG_ 1486 PARK_sw084_messageID "Parking assist sensors: sw084 message ID";
CM_ SG_ 1486 PARK_sw084_errorType "Parking assist sensors: sw084 error type";
CM_ SG_ 1486 PARK_sw086_writeRetryCounter "Parking assist sensors: sw086 write retry counter";
CM_ SG_ 1486 PARK_sw086_readRetryCounter "Parking assist sensors: sw086 read retry counter";
CM_ SG_ 1486 PARK_sw086_currentErrorCode "Parking assist sensors: sw086 current error code";
CM_ SG_ 1486 PARK_sw087_s1_sensorType "Parking assist sensors: sw087 s1 sensor type; raw 3 = signal not available (SNA)";
CM_ SG_ 1486 PARK_sw087_s2_sensorType "Parking assist sensors: sw087 s2 sensor type; raw 3 = signal not available (SNA)";
CM_ SG_ 1486 PARK_sw087_s3_sensorType "Parking assist sensors: sw087 s3 sensor type; raw 3 = signal not available (SNA)";
CM_ SG_ 1486 PARK_sw087_s4_sensorType "Parking assist sensors: sw087 s4 sensor type; raw 3 = signal not available (SNA)";
CM_ SG_ 1486 PARK_sw087_s5_sensorType "Parking assist sensors: sw087 s5 sensor type; raw 3 = signal not available (SNA)";
CM_ SG_ 1486 PARK_sw087_s6_sensorType "Parking assist sensors: sw087 s6 sensor type; raw 3 = signal not available (SNA)";
CM_ SG_ 1486 PARK_sw087_s7_sensorType "Parking assist sensors: sw087 s7 sensor type; raw 3 = signal not available (SNA)";
CM_ SG_ 1486 PARK_sw087_s8_sensorType "Parking assist sensors: sw087 s8 sensor type; raw 3 = signal not available (SNA)";
CM_ SG_ 1486 PARK_sw087_s9_sensorType "Parking assist sensors: sw087 s9 sensor type; raw 3 = signal not available (SNA)";
CM_ SG_ 1486 PARK_sw087_s10_sensorType "Parking assist sensors: sw087 s10 sensor type; raw 3 = signal not available (SNA)";
CM_ SG_ 1486 PARK_sw087_s11_sensorType "Parking assist sensors: sw087 s11 sensor type; raw 3 = signal not available (SNA)";
CM_ SG_ 1486 PARK_sw087_s12_sensorType "Parking assist sensors: sw087 s12 sensor type; raw 3 = signal not available (SNA)";
CM_ BO_ 806 "Parking assist sensors message: info";
CM_ SG_ 806 PARK_infoIndex "Parking assist sensors: info index";
CM_ SG_ 806 PARK_infoBuildType "Parking assist sensors: info build type";
CM_ SG_ 806 PARK_infoComponentID "Parking assist sensors: info component ID";
CM_ SG_ 806 PARK_infoPcbaID "Parking assist sensors: info pcba ID";
CM_ SG_ 806 PARK_infoAssemblyID "Parking assist sensors: info assembly ID";
CM_ SG_ 806 PARK_infoUsageID "Parking assist sensors: info usage ID";
CM_ SG_ 806 PARK_infoApplicationCRC "Parking assist sensors: info application CRC";
CM_ SG_ 806 PARK_infoBootUdsProtoVersion "Parking assist sensors: info boot uds proto version";
CM_ SG_ 806 PARK_infoBootloaderCRC "Parking assist sensors: info bootloader CRC";
CM_ BO_ 846 "Parking assist sensors message: pas front middle";
CM_ SG_ 846 PARK_frontLeftMiddleRawDistData "Zone defined as -38 degrees -> +12 degrees, distance to object in units of centimeters.; raw 255 = signal not available (SNA)";
CM_ SG_ 846 PARK_frontMiddleRawDistData "Zone defined as -12 degrees to +12 degrees, distance to object in units of centimeters.; raw 255 = signal not available (SNA)";
CM_ SG_ 846 PARK_frontRightMiddleRawDistData "Zone defined +12 degrees to +38 degreees, distance to object in units of centimeters.; raw 255 = signal not available (SNA)";
CM_ SG_ 846 PARK_pasFrontMiddleCounter "Parking assist sensors: pas front middle counter";
CM_ SG_ 846 PARK_pasFrontMiddleChecksum "Parking assist sensors: pas front middle checksum";
CM_ BO_ 862 "Parking assist sensors message: pas rear middle";
CM_ SG_ 862 PARK_rearLeftMiddleRawDistData "Zone defined as -124 degrees to -166 degrees, distance to object in units of centimeters.; raw 255 = signal not available (SNA)";
CM_ SG_ 862 PARK_rearMiddleRawDistData "Zone defined as -166 degrees to +166 degrees, distance to object in units of centimeters.; raw 255 = signal not available (SNA)";
CM_ SG_ 862 PARK_rearRightMiddleRawDistData "Zone defined as +166 degrees to +124 degrees, distance to object in units of centimeters.; raw 255 = signal not available (SNA)";
CM_ SG_ 862 PARK_pasRearMiddleCounter "Parking assist sensors: pas rear middle counter";
CM_ SG_ 862 PARK_pasRearMiddleChecksum "Parking assist sensors: pas rear middle checksum";
CM_ BO_ 926 "Parking assist sensors message: pas sides";
CM_ SG_ 926 PARK_rightSideFrontRawDistData "Right side (from inside the car) towards the front of the car (split evenly between axles).; raw 255 = signal not available (SNA)";
CM_ SG_ 926 PARK_rightSideRearRawDistData "Right side (from inside the car) towards the rear of the car (split evenly between axles).; raw 255 = signal not available (SNA)";
CM_ SG_ 926 PARK_leftSideFrontRawDistData "Left side (from inside the car) towards the front of the car (split evenly between axles).; raw 255 = signal not available (SNA)";
CM_ SG_ 926 PARK_leftSideRearRawDistData "Left side (from inside the car) towards the rear of the car (split evenly between axles).; raw 255 = signal not available (SNA)";
CM_ SG_ 926 PARK_pasSidesCounter "Parking assist sensors: pas sides counter";
CM_ SG_ 926 PARK_pasSidesChecksum "Parking assist sensors: pas sides checksum";
CM_ BO_ 606 "Parking assist sensors message: psc env slot";
CM_ SG_ 606 PARK_pscEnvSlotType "Parking assist sensors: psc env slot type";
CM_ SG_ 606 PARK_pscLeftParallelObj1X "Parking assist sensors: psc left parallel obj1 x; raw 2047 = signal not available (SNA)";
CM_ SG_ 606 PARK_pscLeftParallelObj1Y "Parking assist sensors: psc left parallel obj1 y; raw 2047 = signal not available (SNA)";
CM_ SG_ 606 PARK_pscLeftParallelObj1Alpha "Parking assist sensors: psc left parallel obj1 alpha; raw 127 = signal not available (SNA)";
CM_ SG_ 606 PARK_pscLeftParallelObj2Y "Parking assist sensors: psc left parallel obj2 y; raw 2047 = signal not available (SNA)";
CM_ SG_ 606 PARK_pscLeftParallelObj2X "Parking assist sensors: psc left parallel obj2 x; raw 2047 = signal not available (SNA)";
CM_ SG_ 606 PARK_pscLeftParallelObj2Alpha "Parking assist sensors: psc left parallel obj2 alpha; raw 127 = signal not available (SNA)";
CM_ SG_ 606 PARK_pscLeftCrossObj1X "Parking assist sensors: psc left cross obj1 x; raw 2047 = signal not available (SNA)";
CM_ SG_ 606 PARK_pscLeftCrossObj1Y "Parking assist sensors: psc left cross obj1 y; raw 2047 = signal not available (SNA)";
CM_ SG_ 606 PARK_pscLeftCrossObj1Alpha "Parking assist sensors: psc left cross obj1 alpha; raw 127 = signal not available (SNA)";
CM_ SG_ 606 PARK_pscLeftCrossObj2Y "Parking assist sensors: psc left cross obj2 y; raw 2047 = signal not available (SNA)";
CM_ SG_ 606 PARK_pscLeftCrossObj2X "Parking assist sensors: psc left cross obj2 x; raw 2047 = signal not available (SNA)";
CM_ SG_ 606 PARK_pscLeftCrossObj2Alpha "Parking assist sensors: psc left cross obj2 alpha; raw 127 = signal not available (SNA)";
CM_ SG_ 606 PARK_pscRightParallelObj1X "Parking assist sensors: psc right parallel obj1 x; raw 2047 = signal not available (SNA)";
CM_ SG_ 606 PARK_pscRightParallelObj1Y "Parking assist sensors: psc right parallel obj1 y; raw 2047 = signal not available (SNA)";
CM_ SG_ 606 PARK_pscRightParallelObj1Alpha "Parking assist sensors: psc right parallel obj1 alpha; raw 127 = signal not available (SNA)";
CM_ SG_ 606 PARK_pscRightParallelObj2Y "Parking assist sensors: psc right parallel obj2 y; raw 2047 = signal not available (SNA)";
CM_ SG_ 606 PARK_pscRightParallelObj2X "Parking assist sensors: psc right parallel obj2 x; raw 2047 = signal not available (SNA)";
CM_ SG_ 606 PARK_pscRightParallelObj2Alpha "Parking assist sensors: psc right parallel obj2 alpha; raw 127 = signal not available (SNA)";
CM_ SG_ 606 PARK_pscRightCrossObj1X "Parking assist sensors: psc right cross obj1 x; raw 2047 = signal not available (SNA)";
CM_ SG_ 606 PARK_pscRightCrossObj1Y "Parking assist sensors: psc right cross obj1 y; raw 2047 = signal not available (SNA)";
CM_ SG_ 606 PARK_pscRightCrossObj1Alpha "Parking assist sensors: psc right cross obj1 alpha; raw 127 = signal not available (SNA)";
CM_ SG_ 606 PARK_pscRightCrossObj2Y "Parking assist sensors: psc right cross obj2 y; raw 2047 = signal not available (SNA)";
CM_ SG_ 606 PARK_pscRightCrossObj2X "Parking assist sensors: psc right cross obj2 x; raw 2047 = signal not available (SNA)";
CM_ SG_ 606 PARK_pscRightCrossObj2Alpha "Parking assist sensors: psc right cross obj2 alpha; raw 127 = signal not available (SNA)";
BA_DEF_ BO_ "GenMsgCycleTime" INT 0 3600000;
BA_DEF_ BO_ "GenMsgSendType" ENUM "Cyclic","NotUsed","NotUsed","NotUsed","NotUsed","NotUsed","NotUsed","IfActive","NoMsgSendType","NotUsed";
BA_DEF_ BO_ "VFrameFormat" ENUM "StandardCAN","ExtendedCAN","reserved","J1939PG","reserved","reserved","reserved","reserved","reserved","reserved","reserved","reserved","reserved","reserved","StandardCAN_FD","ExtendedCAN_FD";
BA_DEF_ BO_ "CANFD_BRS" ENUM "0","1";
BA_DEF_ SG_ "GenSigSNA" STRING;
BA_DEF_ SG_ "SystemSignalLongSymbol" STRING;
BA_DEF_ SG_ "Confidence" ENUM "validated","plausible","layout-only","contradicted";
BA_DEF_DEF_ "GenMsgCycleTime" 0;
BA_DEF_DEF_ "GenMsgSendType" "NoMsgSendType";
BA_DEF_DEF_ "VFrameFormat" "StandardCAN";
BA_DEF_DEF_ "CANFD_BRS" "1";
BA_DEF_DEF_ "GenSigSNA" "";
BA_DEF_DEF_ "SystemSignalLongSymbol" "";
BA_DEF_DEF_ "Confidence" "layout-only";
BA_ "GenMsgCycleTime" BO_ 981 1000;
BA_ "GenMsgSendType" BO_ 981 0;
BA_ "GenMsgCycleTime" BO_ 805 10000;
BA_ "GenMsgSendType" BO_ 805 0;
BA_ "GenMsgCycleTime" BO_ 861 1000;
BA_ "GenMsgSendType" BO_ 861 0;
BA_ "GenMsgCycleTime" BO_ 813 10000;
BA_ "GenMsgSendType" BO_ 813 0;
BA_ "GenMsgCycleTime" BO_ 806 1000;
BA_ "GenMsgSendType" BO_ 806 0;
BA_ "GenMsgCycleTime" BO_ 846 100;
BA_ "GenMsgSendType" BO_ 846 0;
BA_ "GenMsgCycleTime" BO_ 862 100;
BA_ "GenMsgSendType" BO_ 862 0;
BA_ "GenMsgCycleTime" BO_ 926 100;
BA_ "GenMsgSendType" BO_ 926 0;
BA_ "GenMsgCycleTime" BO_ 606 100;
BA_ "GenMsgSendType" BO_ 606 0;
BA_ "Confidence" SG_ 981 ESP_matrixIndex 1;
BA_ "SystemSignalLongSymbol" SG_ 981 ESP_a193_DIchassisControlChecksu "ESP_a193_DIchassisControlChecksum";
BA_ "SystemSignalLongSymbol" SG_ 981 ESP_a269_DIRELTorqueCommandInval "ESP_a269_DIRELTorqueCommandInvalid";
BA_ "SystemSignalLongSymbol" SG_ 981 ESP_a271_DIRELTorqueActualInvali "ESP_a271_DIRELTorqueActualInvalid";
BA_ "SystemSignalLongSymbol" SG_ 981 ESP_a276_DIRERTorqueCommandInval "ESP_a276_DIRERTorqueCommandInvalid";
BA_ "SystemSignalLongSymbol" SG_ 981 ESP_a278_DIRERTorqueActualInvali "ESP_a278_DIRERTorqueActualInvalid";
BA_ "SystemSignalLongSymbol" SG_ 981 ESP_a279_lifetimeManagementOverr "ESP_a279_lifetimeManagementOverrun";
BA_ "SystemSignalLongSymbol" SG_ 981 ESP_a282_trackModeABSRequestInva "ESP_a282_trackModeABSRequestInvalid";
BA_ "SystemSignalLongSymbol" SG_ 981 ESP_a283_secondaryCollisionMitig "ESP_a283_secondaryCollisionMitigationActive";
BA_ "SystemSignalLongSymbol" SG_ 981 ESP_a284_scmRequestInvalidChecks "ESP_a284_scmRequestInvalidChecksum";
BA_ "SystemSignalLongSymbol" SG_ 981 ESP_a287_failedBrakeCircuitDetec "ESP_a287_failedBrakeCircuitDetected";
BA_ "SystemSignalLongSymbol" SG_ 981 ESP_a296_roadWheelAngleHealthDeg "ESP_a296_roadWheelAngleHealthDegraded";
BA_ "SystemSignalLongSymbol" SG_ 981 ESP_a297_roadWheelAngleHealthFau "ESP_a297_roadWheelAngleHealthFaulted";
BA_ "SystemSignalLongSymbol" SG_ 981 ESP_a298_RSArearSteerStatusTimeo "ESP_a298_RSArearSteerStatusTimeout";
BA_ "SystemSignalLongSymbol" SG_ 981 ESP_a300_RSArearSteerStatusCheck "ESP_a300_RSArearSteerStatusChecksum";
BA_ "SystemSignalLongSymbol" SG_ 981 ESP_a302_rearRoadWheelAngleHealt "ESP_a302_rearRoadWheelAngleHealthDegraded";
BA_ "SystemSignalLongSymbol" SG_ 981 ESP_a303_rearRoadWheelAngleHealt "ESP_a303_rearRoadWheelAngleHealthFaulted";
BA_ "SystemSignalLongSymbol" SG_ 981 ESP_a304_rearVCLVPowerStateTimeo "ESP_a304_rearVCLVPowerStateTimeout";
BA_ "SystemSignalLongSymbol" SG_ 981 ESP_a306_rearVCLVPowerStateCheck "ESP_a306_rearVCLVPowerStateChecksum";
BA_ "SystemSignalLongSymbol" SG_ 981 ESP_a307_rearVCLVPowerStateCount "ESP_a307_rearVCLVPowerStateCounter";
BA_ "SystemSignalLongSymbol" SG_ 981 ESP_a310_brakeLatencyReductionAc "ESP_a310_brakeLatencyReductionActive";
BA_ "SystemSignalLongSymbol" SG_ 981 ESP_a319_AES_BackupActuatorActiv "ESP_a319_AES_BackupActuatorActive";
BA_ "SystemSignalLongSymbol" SG_ 981 ESP_a334_BrakePedalAppliedInvali "ESP_a334_BrakePedalAppliedInvalid";
BA_ "SystemSignalLongSymbol" SG_ 981 ESP_a337_pReductionPotentialInva "ESP_a337_pReductionPotentialInvalid";
BA_ "SystemSignalLongSymbol" SG_ 981 ESP_a341_EnhancedPressureBuildAc "ESP_a341_EnhancedPressureBuildActive";
BA_ "SystemSignalLongSymbol" SG_ 981 ESP_a342_EnhancedPressureBuildNo "ESP_a342_EnhancedPressureBuildNotActive";
BA_ "SystemSignalLongSymbol" SG_ 981 ESP_a343_EnhancedPressureBuildLt "ESP_a343_EnhancedPressureBuildLtmReached";
BA_ "SystemSignalLongSymbol" SG_ 981 ESP_a351_ActuatorYellowLampReque "ESP_a351_ActuatorYellowLampRequested";
BA_ "SystemSignalLongSymbol" SG_ 981 ESP_a353_PressureSensorImplausHi "ESP_a353_PressureSensorImplausHigh";
BA_ "SystemSignalLongSymbol" SG_ 981 ESP_a358_externalActuatorFallbac "ESP_a358_externalActuatorFallback";
BA_ "SystemSignalLongSymbol" SG_ 981 ESP_a359_externalActuatorNoExtRe "ESP_a359_externalActuatorNoExtReq";
BA_ "SystemSignalLongSymbol" SG_ 981 ESP_a362_BBbrakeActuationChecksu "ESP_a362_BBbrakeActuationChecksum";
BA_ "SystemSignalLongSymbol" SG_ 981 ESP_a366_ActuatorBlendingModeReq "ESP_a366_ActuatorBlendingModeReqNotAvailable";
BA_ "SystemSignalLongSymbol" SG_ 981 ESP_a367_CBDS_fillBufferThreshol "ESP_a367_CBDS_fillBufferThreshold";
BA_ "SystemSignalLongSymbol" SG_ 981 ESP_a369_LargeLeakageDetectedByD "ESP_a369_LargeLeakageDetectedByDPB";
BA_ "Confidence" SG_ 805 ESP_infoIndex 1;
BA_ "Confidence" SG_ 805 ESP_infoBuildType 0;
BA_ "Confidence" SG_ 805 ESP_vehFlashMode 0;
BA_ "Confidence" SG_ 805 ESP_infoComponentID 0;
BA_ "Confidence" SG_ 805 ESP_infoPcbaID 0;
BA_ "Confidence" SG_ 805 ESP_infoAssemblyID 0;
BA_ "Confidence" SG_ 805 ESP_infoUsageID 0;
BA_ "Confidence" SG_ 805 ESP_infoSubUsageID 0;
BA_ "Confidence" SG_ 805 ESP_infoApplicationCRC 1;
BA_ "Confidence" SG_ 805 ESP_infoVehicleVariant 0;
BA_ "Confidence" SG_ 805 ESP_infoSubcomponent1 0;
BA_ "Confidence" SG_ 805 ESP_infoBootUdsProtoVersion 0;
BA_ "Confidence" SG_ 805 ESP_infoBootloaderCRC 0;
BA_ "Confidence" SG_ 805 ESP_infoVariantCRC 1;
BA_ "Confidence" SG_ 861 IBST_matrixIndex 1;
BA_ "SystemSignalLongSymbol" SG_ 861 IBST_a182_DIchassisControlTimeou "IBST_a182_DIchassisControlTimeout";
BA_ "SystemSignalLongSymbol" SG_ 861 IBST_a183_DIchassisControlChecks "IBST_a183_DIchassisControlChecksum";
BA_ "SystemSignalLongSymbol" SG_ 861 IBST_a184_DIchassisControlCounte "IBST_a184_DIchassisControlCounter";
BA_ "SystemSignalLongSymbol" SG_ 861 IBST_a189_rightVCLVPowerStateTim "IBST_a189_rightVCLVPowerStateTimeout";
BA_ "SystemSignalLongSymbol" SG_ 861 IBST_a191_rightVCLVPowerStateChe "IBST_a191_rightVCLVPowerStateChecksum";
BA_ "SystemSignalLongSymbol" SG_ 861 IBST_a192_rightVCLVPowerStateCou "IBST_a192_rightVCLVPowerStateCounter";
BA_ "SystemSignalLongSymbol" SG_ 861 IBST_a193_leftVCLVPowerStateTime "IBST_a193_leftVCLVPowerStateTimeout";
BA_ "SystemSignalLongSymbol" SG_ 861 IBST_a194_leftVCLVPowerStateChec "IBST_a194_leftVCLVPowerStateChecksum";
BA_ "SystemSignalLongSymbol" SG_ 861 IBST_a196_leftVCLVPowerStateCoun "IBST_a196_leftVCLVPowerStateCounter";
BA_ "SystemSignalLongSymbol" SG_ 861 IBST_a197_brakeLatencyReductionA "IBST_a197_brakeLatencyReductionActive";
BA_ "SystemSignalLongSymbol" SG_ 861 IBST_a201_EGGREAR1wheelSpeedsRea "IBST_a201_EGGREAR1wheelSpeedsRearTimeOut";
BA_ "SystemSignalLongSymbol" SG_ 861 IBST_a202_EGGREAR1wheelSpeedsRea "IBST_a202_EGGREAR1wheelSpeedsRearChecksum";
BA_ "SystemSignalLongSymbol" SG_ 861 IBST_a203_EGGREAR1wheelSpeedsRea "IBST_a203_EGGREAR1wheelSpeedsRearDLC";
BA_ "SystemSignalLongSymbol" SG_ 861 IBST_a204_EGGREAR1wheelSpeedsRea "IBST_a204_EGGREAR1wheelSpeedsRearCounter";
BA_ "SystemSignalLongSymbol" SG_ 861 IBST_a205_EGGRIGHT1wheelSpeedsFr "IBST_a205_EGGRIGHT1wheelSpeedsFrontTimeOut";
BA_ "SystemSignalLongSymbol" SG_ 861 IBST_a206_EGGRIGHT1wheelSpeedsFr "IBST_a206_EGGRIGHT1wheelSpeedsFrontChecksum";
BA_ "SystemSignalLongSymbol" SG_ 861 IBST_a207_EGGRIGHT1wheelSpeedsFr "IBST_a207_EGGRIGHT1wheelSpeedsFrontDLC";
BA_ "SystemSignalLongSymbol" SG_ 861 IBST_a208_EGGRIGHT1wheelSpeedsFr "IBST_a208_EGGRIGHT1wheelSpeedsFrontCounter";
BA_ "SystemSignalLongSymbol" SG_ 861 IBST_a209_reducedBrakePowerActiv "IBST_a209_reducedBrakePowerActive";
BA_ "SystemSignalLongSymbol" SG_ 861 IBST_a210_reducedBrakePowerNotAv "IBST_a210_reducedBrakePowerNotAvailable";
BA_ "SystemSignalLongSymbol" SG_ 861 IBST_a212_infoFailureWrongCUBASH "IBST_a212_infoFailureWrongCUBASHandlingDetected";
BA_ "SystemSignalLongSymbol" SG_ 861 IBST_a213_PDURouterinitializatio "IBST_a213_PDURouterinitializationFailed";
BA_ "SystemSignalLongSymbol" SG_ 861 IBST_a214_LossOfPDUInstanceDetec "IBST_a214_LossOfPDUInstanceDetected";
BA_ "SystemSignalLongSymbol" SG_ 861 IBST_a215_UnsupportedSeriesHWDet "IBST_a215_UnsupportedSeriesHWDetected";
BA_ "SystemSignalLongSymbol" SG_ 861 IBST_a216_AsicMalfunctionDetecte "IBST_a216_AsicMalfunctionDetected";
BA_ "SystemSignalLongSymbol" SG_ 861 IBST_a217_AsicTrimmingNotComplet "IBST_a217_AsicTrimmingNotCompleted";
BA_ "SystemSignalLongSymbol" SG_ 861 IBST_a218_uCSafetyNotificationGR "IBST_a218_uCSafetyNotificationGRAM";
BA_ "SystemSignalLongSymbol" SG_ 861 IBST_a220_ASICOvercurrentOnGPIO2 "IBST_a220_ASICOvercurrentOnGPIO250_2";
BA_ "SystemSignalLongSymbol" SG_ 861 IBST_a221_ASICOvercurrentOnGPIO2 "IBST_a221_ASICOvercurrentOnGPIO250_1";
BA_ "SystemSignalLongSymbol" SG_ 861 IBST_a222_ASICOvercurrentOnGPIO5 "IBST_a222_ASICOvercurrentOnGPIO50_4";
BA_ "SystemSignalLongSymbol" SG_ 861 IBST_a223_ASICOvercurrentOnGPIO5 "IBST_a223_ASICOvercurrentOnGPIO50_3";
BA_ "SystemSignalLongSymbol" SG_ 861 IBST_a224_ASICOvercurrentOnGPIO5 "IBST_a224_ASICOvercurrentOnGPIO50_2";
BA_ "SystemSignalLongSymbol" SG_ 861 IBST_a225_ASICOvercurrentOnGPIO5 "IBST_a225_ASICOvercurrentOnGPIO50_1";
BA_ "SystemSignalLongSymbol" SG_ 861 IBST_a227_wakeRequestMismatchDet "IBST_a227_wakeRequestMismatchDetected";
BA_ "SystemSignalLongSymbol" SG_ 861 IBST_a228_BlockedPedalDetectedDu "IBST_a228_BlockedPedalDetectedDuringHAD";
BA_ "SystemSignalLongSymbol" SG_ 861 IBST_a232_PostAssemblyRoutineFai "IBST_a232_PostAssemblyRoutineFailed";
BA_ "SystemSignalLongSymbol" SG_ 861 IBST_a233_ReferenceRunAbortByECU "IBST_a233_ReferenceRunAbortByECUReset";
BA_ "Confidence" SG_ 813 IBST_infoIndex 1;
BA_ "Confidence" SG_ 813 IBST_infoBuildType 0;
BA_ "Confidence" SG_ 813 IBST_infoPcbaID 0;
BA_ "Confidence" SG_ 813 IBST_infoAssemblyID 0;
BA_ "Confidence" SG_ 813 IBST_infoUsageID 0;
BA_ "Confidence" SG_ 813 IBST_infoSubUsageID 0;
BA_ "Confidence" SG_ 813 IBST_infoApplicationCRC 0;
BA_ "Confidence" SG_ 813 IBST_infoBootUdsProtoVersion 0;
BA_ "Confidence" SG_ 813 IBST_infoBootloaderCRC 0;
BA_ "Confidence" SG_ 813 IBST_infoVariantCRC 0;
BA_ "Confidence" SG_ 1486 PARK_alertID 1;
BA_ "Confidence" SG_ 1486 PARK_alertState 1;
BA_ "Confidence" SG_ 1486 PARK_sw001_sensorTemperature 1;
BA_ "SystemSignalLongSymbol" SG_ 1486 PARK_sw002_diagnosticTransferErr "PARK_sw002_diagnosticTransferError";
BA_ "Confidence" SG_ 1486 PARK_sw004_reverbPeriod 1;
BA_ "Confidence" SG_ 1486 PARK_sw004_reverbTime 1;
BA_ "Confidence" SG_ 1486 PARK_sw006_sensorTemperature 1;
BA_ "SystemSignalLongSymbol" SG_ 1486 PARK_sw007_diagnosticTransferErr "PARK_sw007_diagnosticTransferError";
BA_ "Confidence" SG_ 1486 PARK_sw009_reverbPeriod 1;
BA_ "Confidence" SG_ 1486 PARK_sw009_reverbTime 1;
BA_ "Confidence" SG_ 1486 PARK_sw011_sensorTemperature 1;
BA_ "SystemSignalLongSymbol" SG_ 1486 PARK_sw012_diagnosticTransferErr "PARK_sw012_diagnosticTransferError";
BA_ "Confidence" SG_ 1486 PARK_sw014_reverbPeriod 1;
BA_ "Confidence" SG_ 1486 PARK_sw014_reverbTime 1;
BA_ "Confidence" SG_ 1486 PARK_sw016_sensorTemperature 1;
BA_ "SystemSignalLongSymbol" SG_ 1486 PARK_sw017_diagnosticTransferErr "PARK_sw017_diagnosticTransferError";
BA_ "Confidence" SG_ 1486 PARK_sw019_reverbPeriod 1;
BA_ "Confidence" SG_ 1486 PARK_sw019_reverbTime 1;
BA_ "Confidence" SG_ 1486 PARK_sw021_sensorTemperature 1;
BA_ "SystemSignalLongSymbol" SG_ 1486 PARK_sw022_diagnosticTransferErr "PARK_sw022_diagnosticTransferError";
BA_ "Confidence" SG_ 1486 PARK_sw024_reverbPeriod 1;
BA_ "Confidence" SG_ 1486 PARK_sw024_reverbTime 1;
BA_ "Confidence" SG_ 1486 PARK_sw026_sensorTemperature 1;
BA_ "SystemSignalLongSymbol" SG_ 1486 PARK_sw027_diagnosticTransferErr "PARK_sw027_diagnosticTransferError";
BA_ "Confidence" SG_ 1486 PARK_sw029_reverbPeriod 1;
BA_ "Confidence" SG_ 1486 PARK_sw029_reverbTime 1;
BA_ "Confidence" SG_ 1486 PARK_sw031_sensorTemperature 1;
BA_ "SystemSignalLongSymbol" SG_ 1486 PARK_sw032_diagnosticTransferErr "PARK_sw032_diagnosticTransferError";
BA_ "Confidence" SG_ 1486 PARK_sw034_reverbPeriod 1;
BA_ "Confidence" SG_ 1486 PARK_sw034_reverbTime 1;
BA_ "Confidence" SG_ 1486 PARK_sw036_sensorTemperature 1;
BA_ "SystemSignalLongSymbol" SG_ 1486 PARK_sw037_diagnosticTransferErr "PARK_sw037_diagnosticTransferError";
BA_ "Confidence" SG_ 1486 PARK_sw039_reverbPeriod 1;
BA_ "Confidence" SG_ 1486 PARK_sw039_reverbTime 1;
BA_ "Confidence" SG_ 1486 PARK_sw041_sensorTemperature 1;
BA_ "SystemSignalLongSymbol" SG_ 1486 PARK_sw042_diagnosticTransferErr "PARK_sw042_diagnosticTransferError";
BA_ "Confidence" SG_ 1486 PARK_sw044_reverbPeriod 1;
BA_ "Confidence" SG_ 1486 PARK_sw044_reverbTime 1;
BA_ "Confidence" SG_ 1486 PARK_sw046_sensorTemperature 1;
BA_ "SystemSignalLongSymbol" SG_ 1486 PARK_sw047_diagnosticTransferErr "PARK_sw047_diagnosticTransferError";
BA_ "Confidence" SG_ 1486 PARK_sw049_reverbPeriod 1;
BA_ "Confidence" SG_ 1486 PARK_sw049_reverbTime 1;
BA_ "Confidence" SG_ 1486 PARK_sw051_sensorTemperature 1;
BA_ "SystemSignalLongSymbol" SG_ 1486 PARK_sw052_diagnosticTransferErr "PARK_sw052_diagnosticTransferError";
BA_ "Confidence" SG_ 1486 PARK_sw054_reverbPeriod 1;
BA_ "Confidence" SG_ 1486 PARK_sw054_reverbTime 1;
BA_ "Confidence" SG_ 1486 PARK_sw056_sensorTemperature 1;
BA_ "SystemSignalLongSymbol" SG_ 1486 PARK_sw057_diagnosticTransferErr "PARK_sw057_diagnosticTransferError";
BA_ "Confidence" SG_ 1486 PARK_sw059_reverbPeriod 1;
BA_ "Confidence" SG_ 1486 PARK_sw059_reverbTime 1;
BA_ "Confidence" SG_ 1486 PARK_sw061_voltage 1;
BA_ "Confidence" SG_ 1486 PARK_sw063_voltage 1;
BA_ "Confidence" SG_ 1486 PARK_sw077_errorType 1;
BA_ "Confidence" SG_ 1486 PARK_sw078_errorType 1;
BA_ "Confidence" SG_ 1486 PARK_sw079_errorType 1;
BA_ "Confidence" SG_ 1486 PARK_sw080_errorType 1;
BA_ "Confidence" SG_ 1486 PARK_sw081_errorType 1;
BA_ "Confidence" SG_ 1486 PARK_sw082_errorType 1;
BA_ "Confidence" SG_ 1486 PARK_sw083_errorType 1;
BA_ "Confidence" SG_ 1486 PARK_sw084_errorType 1;
BA_ "Confidence" SG_ 1486 PARK_sw087_s1_sensorType 1;
BA_ "GenSigSNA" SG_ 1486 PARK_sw087_s1_sensorType "3";
BA_ "Confidence" SG_ 1486 PARK_sw087_s2_sensorType 1;
BA_ "GenSigSNA" SG_ 1486 PARK_sw087_s2_sensorType "3";
BA_ "Confidence" SG_ 1486 PARK_sw087_s3_sensorType 1;
BA_ "GenSigSNA" SG_ 1486 PARK_sw087_s3_sensorType "3";
BA_ "Confidence" SG_ 1486 PARK_sw087_s4_sensorType 1;
BA_ "GenSigSNA" SG_ 1486 PARK_sw087_s4_sensorType "3";
BA_ "Confidence" SG_ 1486 PARK_sw087_s5_sensorType 1;
BA_ "GenSigSNA" SG_ 1486 PARK_sw087_s5_sensorType "3";
BA_ "Confidence" SG_ 1486 PARK_sw087_s6_sensorType 1;
BA_ "GenSigSNA" SG_ 1486 PARK_sw087_s6_sensorType "3";
BA_ "Confidence" SG_ 1486 PARK_sw087_s7_sensorType 1;
BA_ "GenSigSNA" SG_ 1486 PARK_sw087_s7_sensorType "3";
BA_ "Confidence" SG_ 1486 PARK_sw087_s8_sensorType 1;
BA_ "GenSigSNA" SG_ 1486 PARK_sw087_s8_sensorType "3";
BA_ "Confidence" SG_ 1486 PARK_sw087_s9_sensorType 1;
BA_ "GenSigSNA" SG_ 1486 PARK_sw087_s9_sensorType "3";
BA_ "Confidence" SG_ 1486 PARK_sw087_s10_sensorType 1;
BA_ "GenSigSNA" SG_ 1486 PARK_sw087_s10_sensorType "3";
BA_ "Confidence" SG_ 1486 PARK_sw087_s11_sensorType 1;
BA_ "GenSigSNA" SG_ 1486 PARK_sw087_s11_sensorType "3";
BA_ "Confidence" SG_ 1486 PARK_sw087_s12_sensorType 1;
BA_ "GenSigSNA" SG_ 1486 PARK_sw087_s12_sensorType "3";
BA_ "Confidence" SG_ 806 PARK_infoIndex 1;
BA_ "Confidence" SG_ 806 PARK_infoBuildType 0;
BA_ "Confidence" SG_ 806 PARK_infoComponentID 0;
BA_ "Confidence" SG_ 806 PARK_infoPcbaID 0;
BA_ "Confidence" SG_ 806 PARK_infoAssemblyID 0;
BA_ "Confidence" SG_ 806 PARK_infoUsageID 0;
BA_ "Confidence" SG_ 806 PARK_infoApplicationCRC 0;
BA_ "Confidence" SG_ 806 PARK_infoBootUdsProtoVersion 0;
BA_ "Confidence" SG_ 806 PARK_infoBootloaderCRC 0;
BA_ "Confidence" SG_ 846 PARK_frontLeftMiddleRawDistData 0;
BA_ "GenSigSNA" SG_ 846 PARK_frontLeftMiddleRawDistData "255";
BA_ "Confidence" SG_ 846 PARK_frontMiddleRawDistData 0;
BA_ "GenSigSNA" SG_ 846 PARK_frontMiddleRawDistData "255";
BA_ "Confidence" SG_ 846 PARK_frontRightMiddleRawDistData 0;
BA_ "GenSigSNA" SG_ 846 PARK_frontRightMiddleRawDistData "255";
BA_ "Confidence" SG_ 846 PARK_pasFrontMiddleCounter 0;
BA_ "Confidence" SG_ 846 PARK_pasFrontMiddleChecksum 0;
BA_ "Confidence" SG_ 862 PARK_rearLeftMiddleRawDistData 0;
BA_ "GenSigSNA" SG_ 862 PARK_rearLeftMiddleRawDistData "255";
BA_ "Confidence" SG_ 862 PARK_rearMiddleRawDistData 0;
BA_ "GenSigSNA" SG_ 862 PARK_rearMiddleRawDistData "255";
BA_ "Confidence" SG_ 862 PARK_rearRightMiddleRawDistData 0;
BA_ "GenSigSNA" SG_ 862 PARK_rearRightMiddleRawDistData "255";
BA_ "Confidence" SG_ 862 PARK_pasRearMiddleCounter 0;
BA_ "Confidence" SG_ 862 PARK_pasRearMiddleChecksum 0;
BA_ "Confidence" SG_ 926 PARK_rightSideFrontRawDistData 0;
BA_ "GenSigSNA" SG_ 926 PARK_rightSideFrontRawDistData "255";
BA_ "Confidence" SG_ 926 PARK_rightSideRearRawDistData 0;
BA_ "GenSigSNA" SG_ 926 PARK_rightSideRearRawDistData "255";
BA_ "Confidence" SG_ 926 PARK_leftSideFrontRawDistData 0;
BA_ "GenSigSNA" SG_ 926 PARK_leftSideFrontRawDistData "255";
BA_ "Confidence" SG_ 926 PARK_leftSideRearRawDistData 0;
BA_ "GenSigSNA" SG_ 926 PARK_leftSideRearRawDistData "255";
BA_ "Confidence" SG_ 926 PARK_pasSidesCounter 0;
BA_ "Confidence" SG_ 926 PARK_pasSidesChecksum 0;
BA_ "Confidence" SG_ 606 PARK_pscEnvSlotType 1;
BA_ "Confidence" SG_ 606 PARK_pscLeftParallelObj1X 0;
BA_ "GenSigSNA" SG_ 606 PARK_pscLeftParallelObj1X "2047";
BA_ "Confidence" SG_ 606 PARK_pscLeftParallelObj1Y 0;
BA_ "GenSigSNA" SG_ 606 PARK_pscLeftParallelObj1Y "2047";
BA_ "Confidence" SG_ 606 PARK_pscLeftParallelObj1Alpha 0;
BA_ "GenSigSNA" SG_ 606 PARK_pscLeftParallelObj1Alpha "127";
BA_ "Confidence" SG_ 606 PARK_pscLeftParallelObj2Y 0;
BA_ "GenSigSNA" SG_ 606 PARK_pscLeftParallelObj2Y "2047";
BA_ "Confidence" SG_ 606 PARK_pscLeftParallelObj2X 0;
BA_ "GenSigSNA" SG_ 606 PARK_pscLeftParallelObj2X "2047";
BA_ "Confidence" SG_ 606 PARK_pscLeftParallelObj2Alpha 0;
BA_ "GenSigSNA" SG_ 606 PARK_pscLeftParallelObj2Alpha "127";
BA_ "Confidence" SG_ 606 PARK_pscLeftCrossObj1X 0;
BA_ "GenSigSNA" SG_ 606 PARK_pscLeftCrossObj1X "2047";
BA_ "Confidence" SG_ 606 PARK_pscLeftCrossObj1Y 0;
BA_ "GenSigSNA" SG_ 606 PARK_pscLeftCrossObj1Y "2047";
BA_ "Confidence" SG_ 606 PARK_pscLeftCrossObj1Alpha 0;
BA_ "GenSigSNA" SG_ 606 PARK_pscLeftCrossObj1Alpha "127";
BA_ "Confidence" SG_ 606 PARK_pscLeftCrossObj2Y 0;
BA_ "GenSigSNA" SG_ 606 PARK_pscLeftCrossObj2Y "2047";
BA_ "Confidence" SG_ 606 PARK_pscLeftCrossObj2X 0;
BA_ "GenSigSNA" SG_ 606 PARK_pscLeftCrossObj2X "2047";
BA_ "Confidence" SG_ 606 PARK_pscLeftCrossObj2Alpha 0;
BA_ "GenSigSNA" SG_ 606 PARK_pscLeftCrossObj2Alpha "127";
BA_ "Confidence" SG_ 606 PARK_pscRightParallelObj1X 0;
BA_ "GenSigSNA" SG_ 606 PARK_pscRightParallelObj1X "2047";
BA_ "Confidence" SG_ 606 PARK_pscRightParallelObj1Y 0;
BA_ "GenSigSNA" SG_ 606 PARK_pscRightParallelObj1Y "2047";
BA_ "Confidence" SG_ 606 PARK_pscRightParallelObj1Alpha 0;
BA_ "GenSigSNA" SG_ 606 PARK_pscRightParallelObj1Alpha "127";
BA_ "Confidence" SG_ 606 PARK_pscRightParallelObj2Y 0;
BA_ "GenSigSNA" SG_ 606 PARK_pscRightParallelObj2Y "2047";
BA_ "Confidence" SG_ 606 PARK_pscRightParallelObj2X 0;
BA_ "GenSigSNA" SG_ 606 PARK_pscRightParallelObj2X "2047";
BA_ "Confidence" SG_ 606 PARK_pscRightParallelObj2Alpha 0;
BA_ "GenSigSNA" SG_ 606 PARK_pscRightParallelObj2Alpha "127";
BA_ "Confidence" SG_ 606 PARK_pscRightCrossObj1X 0;
BA_ "GenSigSNA" SG_ 606 PARK_pscRightCrossObj1X "2047";
BA_ "Confidence" SG_ 606 PARK_pscRightCrossObj1Y 0;
BA_ "GenSigSNA" SG_ 606 PARK_pscRightCrossObj1Y "2047";
BA_ "Confidence" SG_ 606 PARK_pscRightCrossObj1Alpha 0;
BA_ "GenSigSNA" SG_ 606 PARK_pscRightCrossObj1Alpha "127";
BA_ "Confidence" SG_ 606 PARK_pscRightCrossObj2Y 0;
BA_ "GenSigSNA" SG_ 606 PARK_pscRightCrossObj2Y "2047";
BA_ "Confidence" SG_ 606 PARK_pscRightCrossObj2X 0;
BA_ "GenSigSNA" SG_ 606 PARK_pscRightCrossObj2X "2047";
BA_ "Confidence" SG_ 606 PARK_pscRightCrossObj2Alpha 0;
BA_ "GenSigSNA" SG_ 606 PARK_pscRightCrossObj2Alpha "127";
VAL_ 981 ESP_matrixIndex 6 "AlertMatrix6" 5 "AlertMatrix5" 4 "AlertMatrix4" 3 "AlertMatrix3" 2 "AlertMatrix2" 1 "AlertMatrix1" 0 "AlertMatrix0" ;
VAL_ 805 ESP_infoIndex 255 "END" 31 "SUBCOMPONENT_GITHASH" 30 "PACKAGE_SN_8_14" 29 "PACKAGE_SN_1_7" 27 "PACKAGE_PN_15_20" 26 "PACKAGE_PN_8_14" 25 "PACKAGE_PN_1_7" 23 "SUBCOMPONENT2" 22 "VARIANTCRC" 20 "UDS_PROTOCOL_BOOTCRC" 19 "VERSION_DEPRECATED" 18 "BOOTLOADER_GITHASH" 17 "APP_GITHASH" 16 "SUBCOMPONENT" 15 "BOOTLOADER_CRC" 14 "BOOTLOADER_SVN" 13 "APP_CRC" 11 "PCBAID_ASSYID_USAGEID" 10 "BUILD_HWID_COMPONENTID" 9 "DEPRECATED_9" 8 "DEPRECATED_8" 7 "DEPRECATED_7" 6 "DEPRECATED_6" 5 "DEPRECATED_5" 4 "DEPRECATED_4" 3 "DEPRECATED_3" 2 "DEPRECATED_2" 1 "DEPRECATED_1" 0 "DEPRECATED_0" ;
VAL_ 805 ESP_infoBuildType 4 "INFO_MFG_BUILD" 3 "INFO_TRACEABLE_CI_BUILD" 2 "INFO_LOCAL_BUILD" 1 "INFO_PLATFORM_BUILD" 0 "INFO_UNKNOWN_BUILD" ;
VAL_ 805 ESP_vehFlashMode 1 "Development_Mode" 0 "Production_Mode" ;
VAL_ 805 ESP_infoSubUsageID 16 "XCP_Dfive_ESP_CP_CB" 8 "nonXCP_Dfour_ESP_CP_CB" 4 "XCP_Gladiator_ESP" 2 "nonXCP_Rev_C_ESP_Cappella" 0 "nonXCP_Rev_B_ESP_Cappella" ;
VAL_ 805 ESP_infoVehicleVariant 9 "MODEL_3_VARIANT_09" 8 "MODEL_3_VARIANT_08" 7 "MODEL_3_VARIANT_07" 6 "MODEL_3_VARIANT_06" 5 "MODEL_3_VARIANT_05" 4 "MODEL_3_VARIANT_04" 3 "MODEL_3_VARIANT_03" 2 "MODEL_3_VARIANT_02" 1 "MODEL_3_VARIANT_01" ;
VAL_ 861 IBST_matrixIndex 3 "AlertMatrix3" 2 "AlertMatrix2" 1 "AlertMatrix1" 0 "AlertMatrix0" ;
VAL_ 813 IBST_infoIndex 255 "END" 31 "SUBCOMPONENT_GITHASH" 30 "PACKAGE_SN_8_14" 29 "PACKAGE_SN_1_7" 27 "PACKAGE_PN_15_20" 26 "PACKAGE_PN_8_14" 25 "PACKAGE_PN_1_7" 23 "SUBCOMPONENT2" 22 "VARIANTCRC" 20 "UDS_PROTOCOL_BOOTCRC" 19 "VERSION_DEPRECATED" 18 "BOOTLOADER_GITHASH" 17 "APP_GITHASH" 16 "SUBCOMPONENT" 15 "BOOTLOADER_CRC" 14 "BOOTLOADER_SVN" 13 "APP_CRC" 11 "PCBAID_ASSYID_USAGEID" 10 "BUILD_HWID_COMPONENTID" 9 "DEPRECATED_9" 8 "DEPRECATED_8" 7 "DEPRECATED_7" 6 "DEPRECATED_6" 5 "DEPRECATED_5" 4 "DEPRECATED_4" 3 "DEPRECATED_3" 2 "DEPRECATED_2" 1 "DEPRECATED_1" 0 "DEPRECATED_0" ;
VAL_ 813 IBST_infoBuildType 4 "INFO_MFG_BUILD" 3 "INFO_TRACEABLE_CI_BUILD" 2 "INFO_LOCAL_BUILD" 1 "INFO_PLATFORM_BUILD" 0 "INFO_UNKNOWN_BUILD" ;
VAL_ 1486 PARK_alertID 87 "a087_sensorMismatchError" 86 "a086_nvmFault" 85 "a085_watchdogReset" 84 "a084_sccmError" 83 "a083_vcFrontError" 82 "a082_rcmError" 81 "a081_espError" 80 "a080_epbError" 79 "a079_epasError" 78 "a078_diError" 77 "a077_dasError" 76 "a076_vcFrontMia" 75 "a075_rcmMia" 74 "a074_espMia" 73 "a073_epbMia" 72 "a072_epasMia" 71 "a071_diMia" 70 "a070_sccmMia" 69 "a069_dasMia" 68 "a068_hardwareWatchDog" 67 "a067_privateCANBusOff" 66 "a066_calibrationMissing" 65 "a065_crcFault" 64 "a064_ecuFault" 63 "a063_sensorVoltage" 62 "a062_ecuOverVoltage" 61 "a061_ecuUnderVoltage" 60 "a060_s12_crossTalk" 59 "a059_s12_blocked" 58 "a058_s12_linCommError" 57 "a057_s12_internalFail" 56 "a056_s12_overTemp" 55 "a055_s11_crossTalk" 54 "a054_s11_blocked" 53 "a053_s11_linCommError" 52 "a052_s11_internalFail" 51 "a051_s11_overTemp" 50 "a050_s10_crossTalk" 49 "a049_s10_blocked" 48 "a048_s10_linCommError" 47 "a047_s10_internalFail" 46 "a046_s10_overTemp" 45 "a045_s9_crossTalk" 44 "a044_s9_blocked" 43 "a043_s9_linCommError" 42 "a042_s9_internalFail" 41 "a041_s9_overTemp" 40 "a040_s8_crossTalk" 39 "a039_s8_blocked" 38 "a038_s8_linCommError" 37 "a037_s8_internalFail" 36 "a036_s8_overTemp" 35 "a035_s7_crossTalk" 34 "a034_s7_blocked" 33 "a033_s7_linCommError" 32 "a032_s7_internalFail" 31 "a031_s7_overTemp" 30 "a030_s6_crossTalk" 29 "a029_s6_blocked" 28 "a028_s6_linCommError" 27 "a027_s6_internalFail" 26 "a026_s6_overTemp" 25 "a025_s5_crossTalk" 24 "a024_s5_blocked" 23 "a023_s5_linCommError" 22 "a022_s5_internalFail" 21 "a021_s5_overTemp" 20 "a020_s4_crossTalk" 19 "a019_s4_blocked" 18 "a018_s4_linCommError" 17 "a017_s4_internalFail" 16 "a016_s4_overTemp" 15 "a015_s3_crossTalk" 14 "a014_s3_blocked" 13 "a013_s3_linCommError" 12 "a012_s3_internalFail" 11 "a011_s3_overTemp" 10 "a010_s2_crossTalk" 9 "a009_s2_blocked" 8 "a008_s2_linCommError" 7 "a007_s2_internalFail" 6 "a006_s2_overTemp" 5 "a005_s1_crossTalk" 4 "a004_s1_blocked" 3 "a003_s1_linCommError" 2 "a002_s1_internalFail" 1 "a001_s1_overTemp" 0 "ALERT_DO_NOT_USE_ZERO" ;
VAL_ 1486 PARK_alertState 1 "SET" 0 "CLEARED" ;
VAL_ 1486 PARK_sw077_errorType 5 "OVERRUN" 4 "INVALID_DATA" 3 "SEQUENCE" 2 "CHECKSUM" 1 "LENGTH" 0 "NONE" ;
VAL_ 1486 PARK_sw078_errorType 5 "OVERRUN" 4 "INVALID_DATA" 3 "SEQUENCE" 2 "CHECKSUM" 1 "LENGTH" 0 "NONE" ;
VAL_ 1486 PARK_sw079_errorType 5 "OVERRUN" 4 "INVALID_DATA" 3 "SEQUENCE" 2 "CHECKSUM" 1 "LENGTH" 0 "NONE" ;
VAL_ 1486 PARK_sw080_errorType 5 "OVERRUN" 4 "INVALID_DATA" 3 "SEQUENCE" 2 "CHECKSUM" 1 "LENGTH" 0 "NONE" ;
VAL_ 1486 PARK_sw081_errorType 5 "OVERRUN" 4 "INVALID_DATA" 3 "SEQUENCE" 2 "CHECKSUM" 1 "LENGTH" 0 "NONE" ;
VAL_ 1486 PARK_sw082_errorType 5 "OVERRUN" 4 "INVALID_DATA" 3 "SEQUENCE" 2 "CHECKSUM" 1 "LENGTH" 0 "NONE" ;
VAL_ 1486 PARK_sw083_errorType 5 "OVERRUN" 4 "INVALID_DATA" 3 "SEQUENCE" 2 "CHECKSUM" 1 "LENGTH" 0 "NONE" ;
VAL_ 1486 PARK_sw084_errorType 5 "OVERRUN" 4 "INVALID_DATA" 3 "SEQUENCE" 2 "CHECKSUM" 1 "LENGTH" 0 "NONE" ;
VAL_ 1486 PARK_sw087_s1_sensorType 3 "SNA" 2 "VALEO_HP" 1 "VALEO_HPFL" 0 "NONE" ;
VAL_ 1486 PARK_sw087_s2_sensorType 3 "SNA" 2 "VALEO_HP" 1 "VALEO_HPFL" 0 "NONE" ;
VAL_ 1486 PARK_sw087_s3_sensorType 3 "SNA" 2 "VALEO_HP" 1 "VALEO_HPFL" 0 "NONE" ;
VAL_ 1486 PARK_sw087_s4_sensorType 3 "SNA" 2 "VALEO_HP" 1 "VALEO_HPFL" 0 "NONE" ;
VAL_ 1486 PARK_sw087_s5_sensorType 3 "SNA" 2 "VALEO_HP" 1 "VALEO_HPFL" 0 "NONE" ;
VAL_ 1486 PARK_sw087_s6_sensorType 3 "SNA" 2 "VALEO_HP" 1 "VALEO_HPFL" 0 "NONE" ;
VAL_ 1486 PARK_sw087_s7_sensorType 3 "SNA" 2 "VALEO_HP" 1 "VALEO_HPFL" 0 "NONE" ;
VAL_ 1486 PARK_sw087_s8_sensorType 3 "SNA" 2 "VALEO_HP" 1 "VALEO_HPFL" 0 "NONE" ;
VAL_ 1486 PARK_sw087_s9_sensorType 3 "SNA" 2 "VALEO_HP" 1 "VALEO_HPFL" 0 "NONE" ;
VAL_ 1486 PARK_sw087_s10_sensorType 3 "SNA" 2 "VALEO_HP" 1 "VALEO_HPFL" 0 "NONE" ;
VAL_ 1486 PARK_sw087_s11_sensorType 3 "SNA" 2 "VALEO_HP" 1 "VALEO_HPFL" 0 "NONE" ;
VAL_ 1486 PARK_sw087_s12_sensorType 3 "SNA" 2 "VALEO_HP" 1 "VALEO_HPFL" 0 "NONE" ;
VAL_ 806 PARK_infoIndex 255 "END" 31 "SUBCOMPONENT_GITHASH" 30 "PACKAGE_SN_8_14" 29 "PACKAGE_SN_1_7" 27 "PACKAGE_PN_15_20" 26 "PACKAGE_PN_8_14" 25 "PACKAGE_PN_1_7" 23 "SUBCOMPONENT2" 22 "VARIANTCRC" 20 "UDS_PROTOCOL_BOOTCRC" 19 "VERSION_DEPRECATED" 18 "BOOTLOADER_GITHASH" 17 "APP_GITHASH" 16 "SUBCOMPONENT" 15 "BOOTLOADER_CRC" 14 "BOOTLOADER_SVN" 13 "APP_CRC" 11 "PCBAID_ASSYID_USAGEID" 10 "BUILD_HWID_COMPONENTID" 9 "DEPRECATED_9" 8 "DEPRECATED_8" 7 "DEPRECATED_7" 6 "DEPRECATED_6" 5 "DEPRECATED_5" 4 "DEPRECATED_4" 3 "DEPRECATED_3" 2 "DEPRECATED_2" 1 "DEPRECATED_1" 0 "DEPRECATED_0" ;
VAL_ 806 PARK_infoBuildType 4 "INFO_MFG_BUILD" 3 "INFO_TRACEABLE_CI_BUILD" 2 "INFO_LOCAL_BUILD" 1 "INFO_PLATFORM_BUILD" 0 "INFO_UNKNOWN_BUILD" ;
VAL_ 846 PARK_frontLeftMiddleRawDistData 255 "SNA" ;
VAL_ 846 PARK_frontMiddleRawDistData 255 "SNA" ;
VAL_ 846 PARK_frontRightMiddleRawDistData 255 "SNA" ;
VAL_ 862 PARK_rearLeftMiddleRawDistData 255 "SNA" ;
VAL_ 862 PARK_rearMiddleRawDistData 255 "SNA" ;
VAL_ 862 PARK_rearRightMiddleRawDistData 255 "SNA" ;
VAL_ 926 PARK_rightSideFrontRawDistData 255 "SNA" ;
VAL_ 926 PARK_rightSideRearRawDistData 255 "SNA" ;
VAL_ 926 PARK_leftSideFrontRawDistData 255 "SNA" ;
VAL_ 926 PARK_leftSideRearRawDistData 255 "SNA" ;
VAL_ 606 PARK_pscEnvSlotType 3 "RIGHT_CROSS" 2 "RIGHT_PARALLEL" 1 "LEFT_CROSS" 0 "LEFT_PARALLEL" ;
VAL_ 606 PARK_pscLeftParallelObj1X 2047 "SNA" 2046 "NO_SPACE" ;
VAL_ 606 PARK_pscLeftParallelObj1Y 2047 "SNA" 2046 "NO_SPACE" ;
VAL_ 606 PARK_pscLeftParallelObj1Alpha 127 "SNA" 126 "NO_SPACE" ;
VAL_ 606 PARK_pscLeftParallelObj2Y 2047 "SNA" 2046 "NO_SPACE" ;
VAL_ 606 PARK_pscLeftParallelObj2X 2047 "SNA" 2046 "NO_SPACE" ;
VAL_ 606 PARK_pscLeftParallelObj2Alpha 127 "SNA" 126 "NO_SPACE" ;
VAL_ 606 PARK_pscLeftCrossObj1X 2047 "SNA" 2046 "NO_SPACE" ;
VAL_ 606 PARK_pscLeftCrossObj1Y 2047 "SNA" 2046 "NO_SPACE" ;
VAL_ 606 PARK_pscLeftCrossObj1Alpha 127 "SNA" 126 "NO_SPACE" ;
VAL_ 606 PARK_pscLeftCrossObj2Y 2047 "SNA" 2046 "NO_SPACE" ;
VAL_ 606 PARK_pscLeftCrossObj2X 2047 "SNA" 2046 "NO_SPACE" ;
VAL_ 606 PARK_pscLeftCrossObj2Alpha 127 "SNA" 126 "NO_SPACE" ;
VAL_ 606 PARK_pscRightParallelObj1X 2047 "SNA" 2046 "NO_SPACE" ;
VAL_ 606 PARK_pscRightParallelObj1Y 2047 "SNA" 2046 "NO_SPACE" ;
VAL_ 606 PARK_pscRightParallelObj1Alpha 127 "SNA" 126 "NO_SPACE" ;
VAL_ 606 PARK_pscRightParallelObj2Y 2047 "SNA" 2046 "NO_SPACE" ;
VAL_ 606 PARK_pscRightParallelObj2X 2047 "SNA" 2046 "NO_SPACE" ;
VAL_ 606 PARK_pscRightParallelObj2Alpha 127 "SNA" 126 "NO_SPACE" ;
VAL_ 606 PARK_pscRightCrossObj1X 2047 "SNA" 2046 "NO_SPACE" ;
VAL_ 606 PARK_pscRightCrossObj1Y 2047 "SNA" 2046 "NO_SPACE" ;
VAL_ 606 PARK_pscRightCrossObj1Alpha 127 "SNA" 126 "NO_SPACE" ;
VAL_ 606 PARK_pscRightCrossObj2Y 2047 "SNA" 2046 "NO_SPACE" ;
VAL_ 606 PARK_pscRightCrossObj2X 2047 "SNA" 2046 "NO_SPACE" ;
VAL_ 606 PARK_pscRightCrossObj2Alpha 127 "SNA" 126 "NO_SPACE" ;
